VERSION "dbc-export 1 2026.26.6.5"

NS_ :

BS_:

BU_: APP APS BMS CC CMP CMPD CP DAS DI DIF DIR EPBL EPBR EVSE FC GTW HCML HCMR HVP ICR PCS PCS2 PLG PM PMF PMR PTC SCCM SCM SCS SDCR TAS UMC V2G VC VCBATT VCBATT0 VCBATT1 VCBATT2 VCFRONT VCFRONT1 VCFRONT2 VCLEFT VCRIGHT VCSEC

BO_ 963 VCRIGHT_switchStatus: 8 VCRIGHT
 SG_ VCRIGHT_switchStatusIndex M : 0|1@1+ (1,0) [0|1] "" Vector__XXX
 SG_ VCRIGHT_btnWindowUpRF : 24|1@1+ (1,0) [0|1] "" Vector__XXX
 SG_ VCRIGHT_btnWindowAutoUpRF : 25|1@1+ (1,0) [0|1] "" Vector__XXX
 SG_ VCRIGHT_btnWindowDownRF : 26|1@1+ (1,0) [0|1] "" Vector__XXX
 SG_ VCRIGHT_btnWindowAutoDownRF : 27|1@1+ (1,0) [0|1] "" Vector__XXX
 SG_ VCRIGHT_btnWindowUpRR : 28|1@1+ (1,0) [0|1] "" Vector__XXX
 SG_ VCRIGHT_btnWindowAutoUpRR : 29|1@1+ (1,0) [0|1] "" Vector__XXX
 SG_ VCRIGHT_btnWindowDownRR : 30|1@1+ (1,0) [0|1] "" Vector__XXX
 SG_ VCRIGHT_btnWindowAutoDownRR : 31|1@1+ (1,0) [0|1] "" Vector__XXX
 SG_ VCRIGHT_btnWindowSwPackUpLF : 32|1@1+ (1,0) [0|1] "" Vector__XXX
 SG_ VCRIGHT_btnWindowSwPackAutoUpLF : 33|1@1+ (1,0) [0|1] "" Vector__XXX
 SG_ VCRIGHT_btnWindowSwPackDownLF : 34|1@1+ (1,0) [0|1] "" Vector__XXX
 SG_ VCRIGHT_btnWindowSwPackAutoDwnLF : 35|1@1+ (1,0) [0|1] "" Vector__XXX
 SG_ VCRIGHT_btnWindowSwPackUpLR : 36|1@1+ (1,0) [0|1] "" Vector__XXX
 SG_ VCRIGHT_btnWindowSwPackAutoUpLR : 37|1@1+ (1,0) [0|1] "" Vector__XXX
 SG_ VCRIGHT_btnWindowSwPackDownLR : 38|1@1+ (1,0) [0|1] "" Vector__XXX
 SG_ VCRIGHT_btnWindowSwPackAutoDwnLR : 39|1@1+ (1,0) [0|1] "" Vector__XXX
 SG_ VCRIGHT_frontOccupancySwitch : 42|2@1+ (1,0) [0|3] "" Vector__XXX
 SG_ VCRIGHT_trunkExtReleasePressed : 48|1@1+ (1,0) [0|1] "" Vector__XXX
 SG_ VCRIGHT_btnWindowSwPackUpRR : 49|1@1+ (1,0) [0|1] "" Vector__XXX
 SG_ VCRIGHT_btnWindowSwPackAutoUpRR : 50|1@1+ (1,0) [0|1] "" Vector__XXX
 SG_ VCRIGHT_btnWindowSwPackDownRR : 51|1@1+ (1,0) [0|1] "" Vector__XXX
 SG_ VCRIGHT_btnWindowSwPackAutoDwnRR : 52|1@1+ (1,0) [0|1] "" Vector__XXX
 SG_ VCRIGHT_frontBuckleSwitch m0 : 40|2@1+ (1,0) [0|3] "" Vector__XXX
 SG_ VCRIGHT_rearCenterBuckleSwitch m0 : 44|2@1+ (1,0) [0|3] "" Vector__XXX
 SG_ VCRIGHT_rearRightBuckleSwitch m0 : 46|2@1+ (1,0) [0|3] "" Vector__XXX
 SG_ VCRIGHT_trunkExtReleasePressedPe m1 : 1|1@1+ (1,0) [0|1] "" Vector__XXX
 SG_ VCRIGHT_frontSeatTrackBack m1 : 2|2@1+ (1,0) [1|3] "" Vector__XXX
 SG_ VCRIGHT_frontSeatTrackForward m1 : 4|2@1+ (1,0) [1|3] "" Vector__XXX
 SG_ VCRIGHT_frontSeatTiltDown m1 : 6|2@1+ (1,0) [1|3] "" Vector__XXX
 SG_ VCRIGHT_frontSeatTiltUp m1 : 8|2@1+ (1,0) [1|3] "" Vector__XXX
 SG_ VCRIGHT_frontSeatLiftDown m1 : 10|2@1+ (1,0) [1|3] "" Vector__XXX
 SG_ VCRIGHT_frontSeatLiftUp m1 : 12|2@1+ (1,0) [1|3] "" Vector__XXX
 SG_ VCRIGHT_frontSeatBackrestBack m1 : 14|2@1+ (1,0) [1|3] "" Vector__XXX
 SG_ VCRIGHT_frontSeatBackrestForward m1 : 16|2@1+ (1,0) [1|3] "" Vector__XXX
 SG_ VCRIGHT_frontSeatLumbarDown m1 : 18|2@1+ (1,0) [1|3] "" Vector__XXX
 SG_ VCRIGHT_frontSeatLumbarUp m1 : 20|2@1+ (1,0) [1|3] "" Vector__XXX
 SG_ VCRIGHT_frontSeatLumbarIn m1 : 22|2@1+ (1,0) [1|3] "" Vector__XXX
 SG_ VCRIGHT_frontSeatResistiveOccupa m1 : 54|2@1+ (1,0) [1|3] "" Vector__XXX
 SG_ VCRIGHT_2RowSeatReclineSwitchpac m1 : 56|3@1+ (1,0) [0|7] "" Vector__XXX
 SG_ VCRIGHT_hvacHeatingAllowedRight m1 : 59|1@1+ (1,0) [0|1] "" Vector__XXX
 SG_ VCRIGHT_frontSeatThighSupportRet m1 : 60|2@1+ (1,0) [1|3] "" Vector__XXX

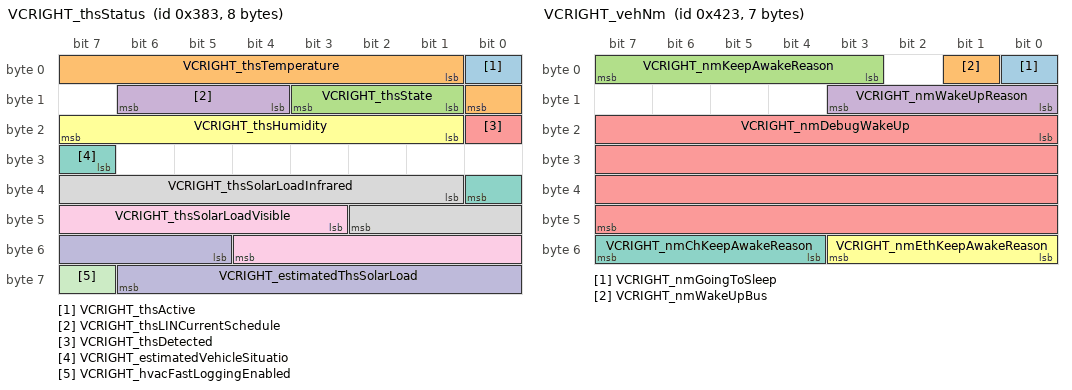
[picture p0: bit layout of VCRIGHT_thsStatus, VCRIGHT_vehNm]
BO_ 899 VCRIGHT_thsStatus: 8 VCRIGHT
 SG_ VCRIGHT_thsActive : 0|1@1+ (1,0) [0|1] "" Vector__XXX
 SG_ VCRIGHT_thsTemperature : 1|8@1+ (1,-40) [-40|150] "degC" Vector__XXX
 SG_ VCRIGHT_thsState : 9|3@1+ (1,0) [0|7] "" Vector__XXX
 SG_ VCRIGHT_thsLINCurrentSchedule : 12|3@1+ (1,0) [0|7] "" Vector__XXX
 SG_ VCRIGHT_thsDetected : 16|1@1+ (1,0) [0|1] "" Vector__XXX
 SG_ VCRIGHT_thsHumidity : 17|7@1+ (1,0) [0|100] "%" Vector__XXX
 SG_ VCRIGHT_estimatedVehicleSituatio : 31|2@1+ (1,0) [0|3] "" Vector__XXX
 SG_ VCRIGHT_thsSolarLoadInfrared : 33|10@1+ (2,0) [0|2044] "W/m2" Vector__XXX
 SG_ VCRIGHT_thsSolarLoadVisible : 43|10@1+ (2,0) [0|2044] "W/m2" Vector__XXX
 SG_ VCRIGHT_estimatedThsSolarLoad : 53|10@1+ (1,0) [0|1022] "W/m2" Vector__XXX
 SG_ VCRIGHT_hvacFastLoggingEnabled : 63|1@1+ (1,0) [0|1] "" Vector__XXX

BO_ 1545 VCRIGHT_udsResponse: 8 VCRIGHT
 SG_ VCRIGHT_udsResponseData_H : 7|32@0+ (1,0) [0|4294967295] "" Vector__XXX
 SG_ VCRIGHT_udsResponseData_L : 39|32@0+ (1,0) [0|4294967295] "" Vector__XXX

BO_ 1059 VCRIGHT_vehNm: 7 VCRIGHT
 SG_ VCRIGHT_nmGoingToSleep : 0|1@1+ (1,0) [0|1] "" Vector__XXX
 SG_ VCRIGHT_nmWakeUpBus : 1|1@1+ (1,0) [0|1] "" Vector__XXX
 SG_ VCRIGHT_nmKeepAwakeReason : 3|5@1+ (1,0) [1|31] "" Vector__XXX
 SG_ VCRIGHT_nmWakeUpReason : 8|4@1+ (1,0) [0|15] "" Vector__XXX
 SG_ VCRIGHT_nmDebugWakeUp : 16|32@1+ (1,0) [0|4294967295] "" Vector__XXX
 SG_ VCRIGHT_nmEthKeepAwakeReason : 48|4@1+ (1,0) [1|15] "" Vector__XXX
 SG_ VCRIGHT_nmChKeepAwakeReason : 52|4@1+ (1,0) [1|15] "" Vector__XXX

BO_ 707 VCRIGHT_windowStatus: 8 VCRIGHT
 SG_ VCRIGHT_windowStatusIndex M : 0|1@1+ (1,0) [0|1] "" Vector__XXX
 SG_ VCRIGHT_windowStateRF m0 : 1|4@1+ (1,0) [0|15] "" Vector__XXX
 SG_ VCRIGHT_windowTrimClearMoveReque m0 : 5|2@1+ (1,0) [0|3] "" Vector__XXX
 SG_ VCRIGHT_windowDutyRF m0 : 8|6@1- (5,0) [-100|100] "%" Vector__XXX
 SG_ VCRIGHT_windowTrimClearActiveReq m0 : 14|2@1+ (1,0) [1|3] "" Vector__XXX
 SG_ VCRIGHT_windowCurrentRF m0 : 16|6@1- (0.5,0) [-15|15] "A" Vector__XXX
 SG_ VCRIGHT_windowPositionRF m0 : 22|9@1- (1.25,265) [-50|580] "mm" Vector__XXX
 SG_ VCRIGHT_windowCalibratedRF m0 : 32|1@1+ (1,0) [0|1] "" Vector__XXX
 SG_ VCRIGHT_windowStateRR m0 : 33|4@1+ (1,0) [0|15] "" Vector__XXX
 SG_ VCRIGHT_windowDutyRR m0 : 40|6@1- (5,0) [-100|100] "%" Vector__XXX
 SG_ VCRIGHT_windowCurrentRR m0 : 48|6@1- (0.5,0) [-15|15] "A" Vector__XXX
 SG_ VCRIGHT_windowPositionRR m0 : 54|9@1- (1.25,265) [-50|580] "mm" Vector__XXX
 SG_ VCRIGHT_windowCalibratedRR m0 : 63|1@1+ (1,0) [0|1] "" Vector__XXX
 SG_ VCRIGHT_windowThermalTCRF m1 : 1|8@1+ (1,0) [0|255] "s" Vector__XXX
 SG_ VCRIGHT_windowThermalModeRF m1 : 9|2@1+ (1,0) [1|3] "" Vector__XXX
 SG_ VCRIGHT_windowStopReasonRF m1 : 11|3@1+ (1,0) [0|7] "" Vector__XXX
 SG_ VCRIGHT_windowStopReqReasonRF m1 : 14|4@1+ (1,0) [0|15] "" Vector__XXX
 SG_ VCRIGHT_windowThermalTCRR m1 : 18|8@1+ (1,0) [0|255] "s" Vector__XXX
 SG_ VCRIGHT_windowThermalModeRR m1 : 26|2@1+ (1,0) [1|3] "" Vector__XXX
 SG_ VCRIGHT_windowStopReasonRR m1 : 28|3@1+ (1,0) [0|7] "" Vector__XXX
 SG_ VCRIGHT_windowStopReqReasonRR m1 : 31|4@1+ (1,0) [0|15] "" Vector__XXX
 SG_ VCRIGHT_windowControlStateRF m1 : 35|2@1+ (1,0) [0|3] "" Vector__XXX
 SG_ VCRIGHT_windowCtrlUnavailableRF m1 : 38|3@1+ (1,0) [0|7] "" Vector__XXX
 SG_ VCRIGHT_windowControlStateRR m1 : 42|2@1+ (1,0) [0|3] "" Vector__XXX
 SG_ VCRIGHT_windowCtrlUnavailableRR m1 : 45|3@1+ (1,0) [0|7] "" Vector__XXX
 SG_ VCRIGHT_windowPositionStateRF m1 : 49|3@1+ (1,0) [0|7] "" Vector__XXX
 SG_ VCRIGHT_windowPositionStateRR m1 : 52|3@1+ (1,0) [0|7] "" Vector__XXX
 SG_ VCRIGHT_windowVehGearStateRF m1 : 56|2@1+ (1,0) [1|3] "" Vector__XXX
 SG_ VCRIGHT_windowVehGearStateRR m1 : 58|2@1+ (1,0) [1|3] "" Vector__XXX
 SG_ VCRIGHT_windowSpeedTableStatusRF m1 : 60|2@1+ (1,0) [1|3] "" Vector__XXX
 SG_ VCRIGHT_windowSpeedTableStatusRR m1 : 62|2@1+ (1,0) [1|3] "" Vector__XXX

BO_ 969 VCSEC_BLEEndpointInfo: 8 VCSEC
 SG_ VCSEC_BLEEndpointInfoIndex M : 0|8@1+ (1,0) [0|255] "" Vector__XXX
 SG_ VCSEC_BLECENTERComponentID m1 : 8|16@1+ (1,0) [0|65535] "" Vector__XXX
 SG_ VCSEC_BLECENTERPcbaID m1 : 24|8@1+ (1,0) [0|255] "" Vector__XXX
 SG_ VCSEC_BLECENTERAssemblyID m1 : 32|8@1+ (1,0) [0|255] "" Vector__XXX
 SG_ VCSEC_BLECENTERUsageID m1 : 40|16@1+ (1,0) [0|65535] "" Vector__XXX
 SG_ VCSEC_BLECENTERCrc m2 : 8|32@1+ (1,0) [0|4294967295] "" Vector__XXX
 SG_ VCSEC_BLELEFTAppGitHashByte m3 : 8|56@1+ (1,0) [0|7.20575940379e+16] "" Vector__XXX
 SG_ VCSEC_BLELEFTComponentID m4 : 8|16@1+ (1,0) [0|65535] "" Vector__XXX
 SG_ VCSEC_BLELEFTPcbaID m4 : 24|8@1+ (1,0) [0|255] "" Vector__XXX
 SG_ VCSEC_BLELEFTAssemblyID m4 : 32|8@1+ (1,0) [0|255] "" Vector__XXX
 SG_ VCSEC_BLELEFTUsageID m4 : 40|16@1+ (1,0) [0|65535] "" Vector__XXX
 SG_ VCSEC_BLELEFTCrc m5 : 8|32@1+ (1,0) [0|4294967295] "" Vector__XXX
 SG_ VCSEC_BLERIGHTAppGitHashByte m6 : 8|56@1+ (1,0) [0|7.20575940379e+16] "" Vector__XXX
 SG_ VCSEC_BLERIGHTComponentID m7 : 8|16@1+ (1,0) [0|65535] "" Vector__XXX
 SG_ VCSEC_BLERIGHTPcbaID m7 : 24|8@1+ (1,0) [0|255] "" Vector__XXX
 SG_ VCSEC_BLERIGHTAssemblyID m7 : 32|8@1+ (1,0) [0|255] "" Vector__XXX
 SG_ VCSEC_BLERIGHTUsageID m7 : 40|16@1+ (1,0) [0|65535] "" Vector__XXX
 SG_ VCSEC_BLERIGHTCrc m8 : 8|32@1+ (1,0) [0|4294967295] "" Vector__XXX
 SG_ VCSEC_BLEREARAppGitHashByte m9 : 8|56@1+ (1,0) [0|7.20575940379e+16] "" Vector__XXX
 SG_ VCSEC_BLEREARComponentID m10 : 8|16@1+ (1,0) [0|65535] "" Vector__XXX
 SG_ VCSEC_BLEREARPcbaID m10 : 24|8@1+ (1,0) [0|255] "" Vector__XXX
 SG_ VCSEC_BLEREARAssemblyID m10 : 32|8@1+ (1,0) [0|255] "" Vector__XXX
 SG_ VCSEC_BLEREARUsageID m10 : 40|16@1+ (1,0) [0|65535] "" Vector__XXX
 SG_ VCSEC_BLEREARCrc m11 : 8|32@1+ (1,0) [0|4294967295] "" Vector__XXX
 SG_ VCSEC_UWBRightCrc m12 : 8|32@1+ (1,0) [0|4294967295] "" Vector__XXX
 SG_ VCSEC_UWBRightRadioConfigState m12 : 40|4@1+ (1,0) [0|15] "" Vector__XXX
 SG_ VCSEC_UWBRightUpdateStatus m12 : 44|3@1+ (1,0) [0|6] "" Vector__XXX
 SG_ VCSEC_UWBRightRetryLimitReached m12 : 47|1@1+ (1,0) [0|1] "" Vector__XXX
 SG_ VCSEC_UWBRightDspVersion m12 : 48|16@1+ (1,0) [0|65535] "" Vector__XXX
 SG_ VCSEC_UWBRightComponentID m13 : 8|8@1+ (1,0) [0|255] "" Vector__XXX
 SG_ VCSEC_UWBRightPcbaID m13 : 16|8@1+ (1,0) [0|255] "" Vector__XXX
 SG_ VCSEC_UWBRightAssemblyID m13 : 24|8@1+ (1,0) [0|255] "" Vector__XXX
 SG_ VCSEC_UWBRightUsageID m13 : 32|16@1+ (1,0) [0|65535] "" Vector__XXX
 SG_ VCSEC_UWBRearRightCrc m15 : 8|32@1+ (1,0) [0|4294967295] "" Vector__XXX
 SG_ VCSEC_UWBRearRightRadioConfigSta m15 : 40|4@1+ (1,0) [0|15] "" Vector__XXX
 SG_ VCSEC_UWBRearRightUpdateStatus m15 : 44|3@1+ (1,0) [0|6] "" Vector__XXX
 SG_ VCSEC_UWBRearRightRetryLimitReac m15 : 47|1@1+ (1,0) [0|1] "" Vector__XXX
 SG_ VCSEC_UWBRearRightDspVersion m15 : 48|16@1+ (1,0) [0|65535] "" Vector__XXX
 SG_ VCSEC_UWBRearRightComponentID m16 : 8|8@1+ (1,0) [0|255] "" Vector__XXX
 SG_ VCSEC_UWBRearRightPcbaID m16 : 16|8@1+ (1,0) [0|255] "" Vector__XXX
 SG_ VCSEC_UWBRearRightAssemblyID m16 : 24|8@1+ (1,0) [0|255] "" Vector__XXX
 SG_ VCSEC_UWBRearRightUsageID m16 : 32|16@1+ (1,0) [0|65535] "" Vector__XXX
 SG_ VCSEC_UWBRearLeftCrc m18 : 8|32@1+ (1,0) [0|4294967295] "" Vector__XXX
 SG_ VCSEC_UWBRearLeftRadioConfigStat m18 : 40|4@1+ (1,0) [0|15] "" Vector__XXX
 SG_ VCSEC_UWBRearLeftUpdateStatus m18 : 44|3@1+ (1,0) [0|6] "" Vector__XXX
 SG_ VCSEC_UWBRearLeftRetryLimitReach m18 : 47|1@1+ (1,0) [0|1] "" Vector__XXX
 SG_ VCSEC_UWBRearLeftDspVersion m18 : 48|16@1+ (1,0) [0|65535] "" Vector__XXX
 SG_ VCSEC_UWBRearLeftComponentID m19 : 8|8@1+ (1,0) [0|255] "" Vector__XXX
 SG_ VCSEC_UWBRearLeftPcbaID m19 : 16|8@1+ (1,0) [0|255] "" Vector__XXX
 SG_ VCSEC_UWBRearLeftAssemblyID m19 : 24|8@1+ (1,0) [0|255] "" Vector__XXX
 SG_ VCSEC_UWBRearLeftUsageID m19 : 32|16@1+ (1,0) [0|65535] "" Vector__XXX
 SG_ VCSEC_UWBRearCrc m21 : 8|32@1+ (1,0) [0|4294967295] "" Vector__XXX
 SG_ VCSEC_UWBRearRadioConfigState m21 : 40|4@1+ (1,0) [0|15] "" Vector__XXX
 SG_ VCSEC_UWBRearUpdateStatus m21 : 44|3@1+ (1,0) [0|6] "" Vector__XXX
 SG_ VCSEC_UWBRearRetryLimitReached m21 : 47|1@1+ (1,0) [0|1] "" Vector__XXX
 SG_ VCSEC_UWBRearDspVersion m21 : 48|16@1+ (1,0) [0|65535] "" Vector__XXX
 SG_ VCSEC_UWBRearComponentID m22 : 8|8@1+ (1,0) [0|255] "" Vector__XXX
 SG_ VCSEC_UWBRearPcbaID m22 : 16|8@1+ (1,0) [0|255] "" Vector__XXX
 SG_ VCSEC_UWBRearAssemblyID m22 : 24|8@1+ (1,0) [0|255] "" Vector__XXX
 SG_ VCSEC_UWBRearUsageID m22 : 32|16@1+ (1,0) [0|65535] "" Vector__XXX
 SG_ VCSEC_UWBLeftCrc m24 : 8|32@1+ (1,0) [0|4294967295] "" Vector__XXX
 SG_ VCSEC_UWBLeftRadioConfigState m24 : 40|4@1+ (1,0) [0|15] "" Vector__XXX
 SG_ VCSEC_UWBLeftUpdateStatus m24 : 44|3@1+ (1,0) [0|6] "" Vector__XXX
 SG_ VCSEC_UWBLeftRetryLimitReached m24 : 47|1@1+ (1,0) [0|1] "" Vector__XXX
 SG_ VCSEC_UWBLeftDspVersion m24 : 48|16@1+ (1,0) [0|65535] "" Vector__XXX
 SG_ VCSEC_UWBLeftComponentID m25 : 8|8@1+ (1,0) [0|255] "" Vector__XXX
 SG_ VCSEC_UWBLeftPcbaID m25 : 16|8@1+ (1,0) [0|255] "" Vector__XXX
 SG_ VCSEC_UWBLeftAssemblyID m25 : 24|8@1+ (1,0) [0|255] "" Vector__XXX
 SG_ VCSEC_UWBLeftUsageID m25 : 32|16@1+ (1,0) [0|65535] "" Vector__XXX
 SG_ VCSEC_UWBCenterCrc m27 : 8|32@1+ (1,0) [0|4294967295] "" Vector__XXX
 SG_ VCSEC_UWBCenterRadioConfigState m27 : 40|4@1+ (1,0) [0|15] "" Vector__XXX
 SG_ VCSEC_UWBCenterUpdateStatus m27 : 44|3@1+ (1,0) [0|6] "" Vector__XXX
 SG_ VCSEC_UWBCenterRetryLimitReached m27 : 47|1@1+ (1,0) [0|1] "" Vector__XXX
 SG_ VCSEC_UWBCenterDspVersion m27 : 48|16@1+ (1,0) [0|65535] "" Vector__XXX
 SG_ VCSEC_UWBCenterComponentID m28 : 8|8@1+ (1,0) [0|255] "" Vector__XXX
 SG_ VCSEC_UWBCenterPcbaID m28 : 16|8@1+ (1,0) [0|255] "" Vector__XXX
 SG_ VCSEC_UWBCenterAssemblyID m28 : 24|8@1+ (1,0) [0|255] "" Vector__XXX
 SG_ VCSEC_UWBCenterUsageID m28 : 32|16@1+ (1,0) [0|65535] "" Vector__XXX
 SG_ VCSEC_BLERIGHTREARCrc m30 : 8|32@1+ (1,0) [0|4294967295] "" Vector__XXX
 SG_ VCSEC_BLERIGHTREARComponentID m31 : 8|16@1+ (1,0) [0|65535] "" Vector__XXX
 SG_ VCSEC_BLERIGHTREARPcbaID m31 : 24|8@1+ (1,0) [0|255] "" Vector__XXX
 SG_ VCSEC_BLERIGHTREARAssemblyID m31 : 32|8@1+ (1,0) [0|255] "" Vector__XXX
 SG_ VCSEC_BLERIGHTREARUsageID m31 : 40|16@1+ (1,0) [0|65535] "" Vector__XXX
 SG_ VCSEC_BLENFCCRADLECrc m33 : 8|32@1+ (1,0) [0|4294967295] "" Vector__XXX
 SG_ VCSEC_BLENFCCRADLEComponentID m34 : 8|16@1+ (1,0) [0|65535] "" Vector__XXX
 SG_ VCSEC_BLENFCCRADLEPcbaID m34 : 24|8@1+ (1,0) [0|255] "" Vector__XXX
 SG_ VCSEC_BLENFCCRADLEAssemblyID m34 : 32|8@1+ (1,0) [0|255] "" Vector__XXX
 SG_ VCSEC_BLENFCCRADLEUsageID m34 : 40|16@1+ (1,0) [0|65535] "" Vector__XXX
 SG_ VCSEC_BLELEFTREARCrc m36 : 8|32@1+ (1,0) [0|4294967295] "" Vector__XXX
 SG_ VCSEC_BLELEFTREARComponentID m37 : 8|16@1+ (1,0) [0|65535] "" Vector__XXX
 SG_ VCSEC_BLELEFTREARPcbaID m37 : 24|8@1+ (1,0) [0|255] "" Vector__XXX
 SG_ VCSEC_BLELEFTREARAssemblyID m37 : 32|8@1+ (1,0) [0|255] "" Vector__XXX
 SG_ VCSEC_BLELEFTREARUsageID m37 : 40|16@1+ (1,0) [0|65535] "" Vector__XXX

BO_ 607 VCSEC_ChildSeatStatus: 8 VCSEC
 SG_ VCSEC_childSeat0_connectionState : 0|3@1+ (1,0) [0|7] "" Vector__XXX
 SG_ VCSEC_childSeat0_taskDisconnecti : 3|2@1+ (1,0) [0|3] "" Vector__XXX
 SG_ VCSEC_childSeat0_state : 5|4@1+ (1,0) [0|15] "" Vector__XXX
 SG_ VCSEC_childSeat0_taskErrorCode : 9|3@1+ (1,0) [0|7] "" Vector__XXX
 SG_ VCSEC_childSeat0_RSSI : 12|8@1- (1,0) [-128|126] "" Vector__XXX
 SG_ VCSEC_childSeat0_ISOFixStatus : 20|2@1+ (1,0) [0|3] "" Vector__XXX
 SG_ VCSEC_childSeat0_buckleStatus : 22|2@1+ (1,0) [0|3] "" Vector__XXX
 SG_ VCSEC_childSeat0_occupancyStatus : 24|2@1+ (1,0) [0|3] "" Vector__XXX
 SG_ VCSEC_childSeat1_connectionState : 26|3@1+ (1,0) [0|7] "" Vector__XXX
 SG_ VCSEC_childSeat1_taskDisconnecti : 29|2@1+ (1,0) [0|3] "" Vector__XXX
 SG_ VCSEC_childSeat1_state : 31|4@1+ (1,0) [0|15] "" Vector__XXX
 SG_ VCSEC_childSeat1_taskErrorCode : 35|3@1+ (1,0) [0|7] "" Vector__XXX
 SG_ VCSEC_childSeat1_RSSI : 38|8@1- (1,0) [-128|126] "" Vector__XXX
 SG_ VCSEC_childSeat1_ISOFixStatus : 46|2@1+ (1,0) [0|3] "" Vector__XXX
 SG_ VCSEC_childSeat1_buckleStatus : 48|2@1+ (1,0) [0|3] "" Vector__XXX
 SG_ VCSEC_childSeat1_occupancyStatus : 50|2@1+ (1,0) [0|3] "" Vector__XXX
 SG_ VCSEC_childPresenceDetectionWarn : 52|1@1+ (1,0) [0|1] "" Vector__XXX
 SG_ VCSEC_childSeatScanStatus : 53|2@1+ (1,0) [0|3] "" Vector__XXX
 SG_ VCSEC_childPresenceDetectionStat : 55|4@1+ (1,0) [0|15] "" Vector__XXX
 SG_ VCSEC_childPresenceDetectionSupp : 59|2@1+ (1,0) [0|3] "" Vector__XXX
 SG_ VCSEC_childPresenceDetectionNoti : 61|1@1+ (1,0) [0|1] "" Vector__XXX

BO_ 857 VCSEC_DeviceStatus: 8 VCSEC
 SG_ VCSEC_DeviceStatusIndex M : 0|7@1+ (1,0) [0|127] "" Vector__XXX
 SG_ VCSEC_Device0AuthResponseTime m0 : 7|7@1+ (50,0) [0|6300] "ms" Vector__XXX
 SG_ VCSEC_Device0Impermanent m0 : 14|1@1+ (1,0) [0|1] "" Vector__XXX
 SG_ VCSEC_Device0SELockedDown m0 : 15|1@1+ (1,0) [0|1] "" Vector__XXX
 SG_ VCSEC_Device0Version m0 : 16|16@1+ (1,0) [0|65535] "" Vector__XXX
 SG_ VCSEC_Device0WLEntry m0 : 32|5@1+ (1,0) [0|31] "" Vector__XXX
 SG_ VCSEC_Device0OSVersion m0 : 37|12@1+ (1,0) [0|4095] "" Vector__XXX
 SG_ VCSEC_Device0BatteryLevel m0 : 49|8@1+ (0.015625,0) [0|3.9] "V" Vector__XXX
 SG_ VCSEC_Device0Formfactor m0 : 57|5@1+ (1,0) [0|31] "" Vector__XXX
 SG_ VCSEC_Device0BlacklistStatus m0 : 62|1@1+ (1,0) [0|1] "" Vector__XXX
 SG_ VCSEC_Device0Stationary m0 : 63|1@1+ (1,0) [0|1] "" Vector__XXX
 SG_ VCSEC_Device0Bonded m2 : 8|1@1+ (1,0) [0|1] "" Vector__XXX
 SG_ VCSEC_Device0Role m2 : 9|4@1+ (1,0) [0|15] "" Vector__XXX
 SG_ VCSEC_Device0WhitelistActiveTime m2 : 16|16@1+ (1,0) [0|65535] "mins" Vector__XXX
 SG_ VCSEC_Device0SHA1 m2 : 32|32@1+ (1,0) [0|4294967295] "" Vector__XXX
 SG_ VCSEC_Device0Permissions m3 : 32|32@1+ (1,0) [0|4294967295] "" Vector__XXX
 SG_ VCSEC_Device0ManufacturerHashBit m5 : 8|24@1+ (1,0) [0|16777215] "" Vector__XXX
 SG_ VCSEC_Device0BuildNumberHashBits m5 : 32|32@1+ (1,0) [0|4294967295] "" Vector__XXX
 SG_ VCSEC_Device1AuthResponseTime m6 : 7|7@1+ (50,0) [0|6300] "ms" Vector__XXX
 SG_ VCSEC_Device1Impermanent m6 : 14|1@1+ (1,0) [0|1] "" Vector__XXX
 SG_ VCSEC_Device1SELockedDown m6 : 15|1@1+ (1,0) [0|1] "" Vector__XXX
 SG_ VCSEC_Device1Version m6 : 16|16@1+ (1,0) [0|65535] "" Vector__XXX
 SG_ VCSEC_Device1WLEntry m6 : 32|5@1+ (1,0) [0|31] "" Vector__XXX
 SG_ VCSEC_Device1OSVersion m6 : 37|12@1+ (1,0) [0|4095] "" Vector__XXX
 SG_ VCSEC_Device1BatteryLevel m6 : 49|8@1+ (0.015625,0) [0|3.9] "V" Vector__XXX
 SG_ VCSEC_Device1Formfactor m6 : 57|5@1+ (1,0) [0|31] "" Vector__XXX
 SG_ VCSEC_Device1BlacklistStatus m6 : 62|1@1+ (1,0) [0|1] "" Vector__XXX
 SG_ VCSEC_Device1Stationary m6 : 63|1@1+ (1,0) [0|1] "" Vector__XXX
 SG_ VCSEC_Device1Bonded m8 : 8|1@1+ (1,0) [0|1] "" Vector__XXX
 SG_ VCSEC_Device1Role m8 : 9|4@1+ (1,0) [0|15] "" Vector__XXX
 SG_ VCSEC_Device1WhitelistActiveTime m8 : 16|16@1+ (1,0) [0|65535] "mins" Vector__XXX
 SG_ VCSEC_Device1SHA1 m8 : 32|32@1+ (1,0) [0|4294967295] "" Vector__XXX
 SG_ VCSEC_Device1Permissions m9 : 32|32@1+ (1,0) [0|4294967295] "" Vector__XXX
 SG_ VCSEC_Device1ManufacturerHashBit m11 : 8|24@1+ (1,0) [0|16777215] "" Vector__XXX
 SG_ VCSEC_Device1BuildNumberHashBits m11 : 32|32@1+ (1,0) [0|4294967295] "" Vector__XXX
 SG_ VCSEC_Device2AuthResponseTime m12 : 7|7@1+ (50,0) [0|6300] "ms" Vector__XXX
 SG_ VCSEC_Device2Impermanent m12 : 14|1@1+ (1,0) [0|1] "" Vector__XXX
 SG_ VCSEC_Device2SELockedDown m12 : 15|1@1+ (1,0) [0|1] "" Vector__XXX
 SG_ VCSEC_Device2Version m12 : 16|16@1+ (1,0) [0|65535] "" Vector__XXX
 SG_ VCSEC_Device2WLEntry m12 : 32|5@1+ (1,0) [0|31] "" Vector__XXX
 SG_ VCSEC_Device2OSVersion m12 : 37|12@1+ (1,0) [0|4095] "" Vector__XXX
 SG_ VCSEC_Device2BatteryLevel m12 : 49|8@1+ (0.015625,0) [0|3.9] "V" Vector__XXX
 SG_ VCSEC_Device2Formfactor m12 : 57|5@1+ (1,0) [0|31] "" Vector__XXX
 SG_ VCSEC_Device2BlacklistStatus m12 : 62|1@1+ (1,0) [0|1] "" Vector__XXX
 SG_ VCSEC_Device2Stationary m12 : 63|1@1+ (1,0) [0|1] "" Vector__XXX
 SG_ VCSEC_Device2Bonded m14 : 8|1@1+ (1,0) [0|1] "" Vector__XXX
 SG_ VCSEC_Device2Role m14 : 9|4@1+ (1,0) [0|15] "" Vector__XXX
 SG_ VCSEC_Device2WhitelistActiveTime m14 : 16|16@1+ (1,0) [0|65535] "mins" Vector__XXX
 SG_ VCSEC_Device2SHA1 m14 : 32|32@1+ (1,0) [0|4294967295] "" Vector__XXX
 SG_ VCSEC_Device2Permissions m15 : 32|32@1+ (1,0) [0|4294967295] "" Vector__XXX
 SG_ VCSEC_Device2ManufacturerHashBit m17 : 8|24@1+ (1,0) [0|16777215] "" Vector__XXX
 SG_ VCSEC_Device2BuildNumberHashBits m17 : 32|32@1+ (1,0) [0|4294967295] "" Vector__XXX
 SG_ VCSEC_Device3AuthResponseTime m18 : 7|7@1+ (50,0) [0|6300] "ms" Vector__XXX
 SG_ VCSEC_Device3Impermanent m18 : 14|1@1+ (1,0) [0|1] "" Vector__XXX
 SG_ VCSEC_Device3SELockedDown m18 : 15|1@1+ (1,0) [0|1] "" Vector__XXX
 SG_ VCSEC_Device3Version m18 : 16|16@1+ (1,0) [0|65535] "" Vector__XXX
 SG_ VCSEC_Device3WLEntry m18 : 32|5@1+ (1,0) [0|31] "" Vector__XXX
 SG_ VCSEC_Device3OSVersion m18 : 37|12@1+ (1,0) [0|4095] "" Vector__XXX
 SG_ VCSEC_Device3BatteryLevel m18 : 49|8@1+ (0.015625,0) [0|3.9] "V" Vector__XXX
 SG_ VCSEC_Device3Formfactor m18 : 57|5@1+ (1,0) [0|31] "" Vector__XXX
 SG_ VCSEC_Device3BlacklistStatus m18 : 62|1@1+ (1,0) [0|1] "" Vector__XXX
 SG_ VCSEC_Device3Stationary m18 : 63|1@1+ (1,0) [0|1] "" Vector__XXX
 SG_ VCSEC_Device3Bonded m20 : 8|1@1+ (1,0) [0|1] "" Vector__XXX
 SG_ VCSEC_Device3Role m20 : 9|4@1+ (1,0) [0|15] "" Vector__XXX
 SG_ VCSEC_Device3WhitelistActiveTime m20 : 16|16@1+ (1,0) [0|65535] "mins" Vector__XXX
 SG_ VCSEC_Device3SHA1 m20 : 32|32@1+ (1,0) [0|4294967295] "" Vector__XXX
 SG_ VCSEC_Device3Permissions m21 : 32|32@1+ (1,0) [0|4294967295] "" Vector__XXX
 SG_ VCSEC_Device3ManufacturerHashBit m23 : 8|24@1+ (1,0) [0|16777215] "" Vector__XXX
 SG_ VCSEC_Device3BuildNumberHashBits m23 : 32|32@1+ (1,0) [0|4294967295] "" Vector__XXX
 SG_ VCSEC_Device4AuthResponseTime m24 : 7|7@1+ (50,0) [0|6300] "ms" Vector__XXX
 SG_ VCSEC_Device4Impermanent m24 : 14|1@1+ (1,0) [0|1] "" Vector__XXX
 SG_ VCSEC_Device4SELockedDown m24 : 15|1@1+ (1,0) [0|1] "" Vector__XXX
 SG_ VCSEC_Device4Version m24 : 16|16@1+ (1,0) [0|65535] "" Vector__XXX
 SG_ VCSEC_Device4WLEntry m24 : 32|5@1+ (1,0) [0|31] "" Vector__XXX
 SG_ VCSEC_Device4OSVersion m24 : 37|12@1+ (1,0) [0|4095] "" Vector__XXX
 SG_ VCSEC_Device4BatteryLevel m24 : 49|8@1+ (0.015625,0) [0|3.9] "V" Vector__XXX
 SG_ VCSEC_Device4Formfactor m24 : 57|5@1+ (1,0) [0|31] "" Vector__XXX
 SG_ VCSEC_Device4BlacklistStatus m24 : 62|1@1+ (1,0) [0|1] "" Vector__XXX
 SG_ VCSEC_Device4Stationary m24 : 63|1@1+ (1,0) [0|1] "" Vector__XXX
 SG_ VCSEC_Device4Bonded m26 : 8|1@1+ (1,0) [0|1] "" Vector__XXX
 SG_ VCSEC_Device4Role m26 : 9|4@1+ (1,0) [0|15] "" Vector__XXX
 SG_ VCSEC_Device4WhitelistActiveTime m26 : 16|16@1+ (1,0) [0|65535] "mins" Vector__XXX
 SG_ VCSEC_Device4SHA1 m26 : 32|32@1+ (1,0) [0|4294967295] "" Vector__XXX
 SG_ VCSEC_Device4Permissions m27 : 32|32@1+ (1,0) [0|4294967295] "" Vector__XXX
 SG_ VCSEC_Device4ManufacturerHashBit m29 : 8|24@1+ (1,0) [0|16777215] "" Vector__XXX
 SG_ VCSEC_Device4BuildNumberHashBits m29 : 32|32@1+ (1,0) [0|4294967295] "" Vector__XXX
 SG_ VCSEC_Device5AuthResponseTime m30 : 7|7@1+ (50,0) [0|6300] "ms" Vector__XXX
 SG_ VCSEC_Device5Impermanent m30 : 14|1@1+ (1,0) [0|1] "" Vector__XXX
 SG_ VCSEC_Device5SELockedDown m30 : 15|1@1+ (1,0) [0|1] "" Vector__XXX
 SG_ VCSEC_Device5Version m30 : 16|16@1+ (1,0) [0|65535] "" Vector__XXX
 SG_ VCSEC_Device5WLEntry m30 : 32|5@1+ (1,0) [0|31] "" Vector__XXX
 SG_ VCSEC_Device5OSVersion m30 : 37|12@1+ (1,0) [0|4095] "" Vector__XXX
 SG_ VCSEC_Device5BatteryLevel m30 : 49|8@1+ (0.015625,0) [0|3.9] "V" Vector__XXX
 SG_ VCSEC_Device5Formfactor m30 : 57|5@1+ (1,0) [0|31] "" Vector__XXX
 SG_ VCSEC_Device5BlacklistStatus m30 : 62|1@1+ (1,0) [0|1] "" Vector__XXX
 SG_ VCSEC_Device5Stationary m30 : 63|1@1+ (1,0) [0|1] "" Vector__XXX
 SG_ VCSEC_Device5Bonded m32 : 8|1@1+ (1,0) [0|1] "" Vector__XXX
 SG_ VCSEC_Device5Role m32 : 9|4@1+ (1,0) [0|15] "" Vector__XXX
 SG_ VCSEC_Device5WhitelistActiveTime m32 : 16|16@1+ (1,0) [0|65535] "mins" Vector__XXX
 SG_ VCSEC_Device5SHA1 m32 : 32|32@1+ (1,0) [0|4294967295] "" Vector__XXX
 SG_ VCSEC_Device5Permissions m33 : 32|32@1+ (1,0) [0|4294967295] "" Vector__XXX
 SG_ VCSEC_Device5ManufacturerHashBit m35 : 8|24@1+ (1,0) [0|16777215] "" Vector__XXX
 SG_ VCSEC_Device5BuildNumberHashBits m35 : 32|32@1+ (1,0) [0|4294967295] "" Vector__XXX
 SG_ VCSEC_Device6AuthResponseTime m36 : 7|7@1+ (50,0) [0|6300] "ms" Vector__XXX
 SG_ VCSEC_Device6Impermanent m36 : 14|1@1+ (1,0) [0|1] "" Vector__XXX
 SG_ VCSEC_Device6SELockedDown m36 : 15|1@1+ (1,0) [0|1] "" Vector__XXX
 SG_ VCSEC_Device6Version m36 : 16|16@1+ (1,0) [0|65535] "" Vector__XXX
 SG_ VCSEC_Device6WLEntry m36 : 32|5@1+ (1,0) [0|31] "" Vector__XXX
 SG_ VCSEC_Device6OSVersion m36 : 37|12@1+ (1,0) [0|4095] "" Vector__XXX
 SG_ VCSEC_Device6BatteryLevel m36 : 49|8@1+ (0.015625,0) [0|3.9] "V" Vector__XXX
 SG_ VCSEC_Device6Formfactor m36 : 57|5@1+ (1,0) [0|31] "" Vector__XXX
 SG_ VCSEC_Device6BlacklistStatus m36 : 62|1@1+ (1,0) [0|1] "" Vector__XXX
 SG_ VCSEC_Device6Stationary m36 : 63|1@1+ (1,0) [0|1] "" Vector__XXX
 SG_ VCSEC_Device6Bonded m38 : 8|1@1+ (1,0) [0|1] "" Vector__XXX
 SG_ VCSEC_Device6Role m38 : 9|4@1+ (1,0) [0|15] "" Vector__XXX
 SG_ VCSEC_Device6WhitelistActiveTime m38 : 16|16@1+ (1,0) [0|65535] "mins" Vector__XXX
 SG_ VCSEC_Device6SHA1 m38 : 32|32@1+ (1,0) [0|4294967295] "" Vector__XXX
 SG_ VCSEC_Device6Permissions m39 : 32|32@1+ (1,0) [0|4294967295] "" Vector__XXX
 SG_ VCSEC_Device6ManufacturerHashBit m41 : 8|24@1+ (1,0) [0|16777215] "" Vector__XXX
 SG_ VCSEC_Device6BuildNumberHashBits m41 : 32|32@1+ (1,0) [0|4294967295] "" Vector__XXX
 SG_ VCSEC_Device7AuthResponseTime m42 : 7|7@1+ (50,0) [0|6300] "ms" Vector__XXX
 SG_ VCSEC_Device7Impermanent m42 : 14|1@1+ (1,0) [0|1] "" Vector__XXX
 SG_ VCSEC_Device7SELockedDown m42 : 15|1@1+ (1,0) [0|1] "" Vector__XXX
 SG_ VCSEC_Device7Version m42 : 16|16@1+ (1,0) [0|65535] "" Vector__XXX
 SG_ VCSEC_Device7WLEntry m42 : 32|5@1+ (1,0) [0|31] "" Vector__XXX
 SG_ VCSEC_Device7OSVersion m42 : 37|12@1+ (1,0) [0|4095] "" Vector__XXX
 SG_ VCSEC_Device7BatteryLevel m42 : 49|8@1+ (0.015625,0) [0|3.9] "V" Vector__XXX
 SG_ VCSEC_Device7Formfactor m42 : 57|5@1+ (1,0) [0|31] "" Vector__XXX
 SG_ VCSEC_Device7BlacklistStatus m42 : 62|1@1+ (1,0) [0|1] "" Vector__XXX
 SG_ VCSEC_Device7Stationary m42 : 63|1@1+ (1,0) [0|1] "" Vector__XXX
 SG_ VCSEC_Device7Bonded m44 : 8|1@1+ (1,0) [0|1] "" Vector__XXX
 SG_ VCSEC_Device7Role m44 : 9|4@1+ (1,0) [0|15] "" Vector__XXX
 SG_ VCSEC_Device7WhitelistActiveTime m44 : 16|16@1+ (1,0) [0|65535] "mins" Vector__XXX
 SG_ VCSEC_Device7SHA1 m44 : 32|32@1+ (1,0) [0|4294967295] "" Vector__XXX
 SG_ VCSEC_Device7Permissions m45 : 32|32@1+ (1,0) [0|4294967295] "" Vector__XXX
 SG_ VCSEC_Device7ManufacturerHashBit m47 : 8|24@1+ (1,0) [0|16777215] "" Vector__XXX
 SG_ VCSEC_Device7BuildNumberHashBits m47 : 32|32@1+ (1,0) [0|4294967295] "" Vector__XXX
 SG_ VCSEC_Device8AuthResponseTime m48 : 7|7@1+ (50,0) [0|6300] "ms" Vector__XXX
 SG_ VCSEC_Device8Impermanent m48 : 14|1@1+ (1,0) [0|1] "" Vector__XXX
 SG_ VCSEC_Device8SELockedDown m48 : 15|1@1+ (1,0) [0|1] "" Vector__XXX
 SG_ VCSEC_Device8Version m48 : 16|16@1+ (1,0) [0|65535] "" Vector__XXX
 SG_ VCSEC_Device8WLEntry m48 : 32|5@1+ (1,0) [0|31] "" Vector__XXX
 SG_ VCSEC_Device8OSVersion m48 : 37|12@1+ (1,0) [0|4095] "" Vector__XXX
 SG_ VCSEC_Device8BatteryLevel m48 : 49|8@1+ (0.015625,0) [0|3.9] "V" Vector__XXX
 SG_ VCSEC_Device8Formfactor m48 : 57|5@1+ (1,0) [0|31] "" Vector__XXX
 SG_ VCSEC_Device8BlacklistStatus m48 : 62|1@1+ (1,0) [0|1] "" Vector__XXX
 SG_ VCSEC_Device8Stationary m48 : 63|1@1+ (1,0) [0|1] "" Vector__XXX
 SG_ VCSEC_Device8Bonded m50 : 8|1@1+ (1,0) [0|1] "" Vector__XXX
 SG_ VCSEC_Device8Role m50 : 9|4@1+ (1,0) [0|15] "" Vector__XXX
 SG_ VCSEC_Device8WhitelistActiveTime m50 : 16|16@1+ (1,0) [0|65535] "mins" Vector__XXX
 SG_ VCSEC_Device8SHA1 m50 : 32|32@1+ (1,0) [0|4294967295] "" Vector__XXX
 SG_ VCSEC_Device8Permissions m51 : 32|32@1+ (1,0) [0|4294967295] "" Vector__XXX
 SG_ VCSEC_Device8ManufacturerHashBit m53 : 8|24@1+ (1,0) [0|16777215] "" Vector__XXX
 SG_ VCSEC_Device8BuildNumberHashBits m53 : 32|32@1+ (1,0) [0|4294967295] "" Vector__XXX
 SG_ VCSEC_Device9AuthResponseTime m54 : 7|7@1+ (50,0) [0|6300] "ms" Vector__XXX
 SG_ VCSEC_Device9Impermanent m54 : 14|1@1+ (1,0) [0|1] "" Vector__XXX
 SG_ VCSEC_Device9SELockedDown m54 : 15|1@1+ (1,0) [0|1] "" Vector__XXX
 SG_ VCSEC_Device9Version m54 : 16|16@1+ (1,0) [0|65535] "" Vector__XXX
 SG_ VCSEC_Device9WLEntry m54 : 32|5@1+ (1,0) [0|31] "" Vector__XXX
 SG_ VCSEC_Device9OSVersion m54 : 37|12@1+ (1,0) [0|4095] "" Vector__XXX
 SG_ VCSEC_Device9BatteryLevel m54 : 49|8@1+ (0.015625,0) [0|3.9] "V" Vector__XXX
 SG_ VCSEC_Device9Formfactor m54 : 57|5@1+ (1,0) [0|31] "" Vector__XXX
 SG_ VCSEC_Device9BlacklistStatus m54 : 62|1@1+ (1,0) [0|1] "" Vector__XXX
 SG_ VCSEC_Device9Stationary m54 : 63|1@1+ (1,0) [0|1] "" Vector__XXX
 SG_ VCSEC_Device9Bonded m56 : 8|1@1+ (1,0) [0|1] "" Vector__XXX
 SG_ VCSEC_Device9Role m56 : 9|4@1+ (1,0) [0|15] "" Vector__XXX
 SG_ VCSEC_Device9WhitelistActiveTime m56 : 16|16@1+ (1,0) [0|65535] "mins" Vector__XXX
 SG_ VCSEC_Device9SHA1 m56 : 32|32@1+ (1,0) [0|4294967295] "" Vector__XXX
 SG_ VCSEC_Device9Permissions m57 : 32|32@1+ (1,0) [0|4294967295] "" Vector__XXX
 SG_ VCSEC_Device9ManufacturerHashBit m59 : 8|24@1+ (1,0) [0|16777215] "" Vector__XXX
 SG_ VCSEC_Device9BuildNumberHashBits m59 : 32|32@1+ (1,0) [0|4294967295] "" Vector__XXX
 SG_ VCSEC_Device10AuthResponseTime m60 : 7|7@1+ (50,0) [0|6300] "ms" Vector__XXX
 SG_ VCSEC_Device10Impermanent m60 : 14|1@1+ (1,0) [0|1] "" Vector__XXX
 SG_ VCSEC_Device10SELockedDown m60 : 15|1@1+ (1,0) [0|1] "" Vector__XXX
 SG_ VCSEC_Device10Version m60 : 16|16@1+ (1,0) [0|65535] "" Vector__XXX
 SG_ VCSEC_Device10WLEntry m60 : 32|5@1+ (1,0) [0|31] "" Vector__XXX
 SG_ VCSEC_Device10OSVersion m60 : 37|12@1+ (1,0) [0|4095] "" Vector__XXX
 SG_ VCSEC_Device10BatteryLevel m60 : 49|8@1+ (0.015625,0) [0|3.9] "V" Vector__XXX
 SG_ VCSEC_Device10Formfactor m60 : 57|5@1+ (1,0) [0|31] "" Vector__XXX
 SG_ VCSEC_Device10BlacklistStatus m60 : 62|1@1+ (1,0) [0|1] "" Vector__XXX
 SG_ VCSEC_Device10Stationary m60 : 63|1@1+ (1,0) [0|1] "" Vector__XXX
 SG_ VCSEC_Device10Bonded m62 : 8|1@1+ (1,0) [0|1] "" Vector__XXX
 SG_ VCSEC_Device10Role m62 : 9|4@1+ (1,0) [0|15] "" Vector__XXX
 SG_ VCSEC_Device10WhitelistActiveTim m62 : 16|16@1+ (1,0) [0|65535] "mins" Vector__XXX
 SG_ VCSEC_Device10SHA1 m62 : 32|32@1+ (1,0) [0|4294967295] "" Vector__XXX
 SG_ VCSEC_Device10Permissions m63 : 32|32@1+ (1,0) [0|4294967295] "" Vector__XXX
 SG_ VCSEC_Device10ManufacturerHashBi m65 : 8|24@1+ (1,0) [0|16777215] "" Vector__XXX
 SG_ VCSEC_Device10BuildNumberHashBit m65 : 32|32@1+ (1,0) [0|4294967295] "" Vector__XXX
 SG_ VCSEC_Device11AuthResponseTime m66 : 7|7@1+ (50,0) [0|6300] "ms" Vector__XXX
 SG_ VCSEC_Device11Impermanent m66 : 14|1@1+ (1,0) [0|1] "" Vector__XXX
 SG_ VCSEC_Device11SELockedDown m66 : 15|1@1+ (1,0) [0|1] "" Vector__XXX
 SG_ VCSEC_Device11Version m66 : 16|16@1+ (1,0) [0|65535] "" Vector__XXX
 SG_ VCSEC_Device11WLEntry m66 : 32|5@1+ (1,0) [0|31] "" Vector__XXX
 SG_ VCSEC_Device11OSVersion m66 : 37|12@1+ (1,0) [0|4095] "" Vector__XXX
 SG_ VCSEC_Device11BatteryLevel m66 : 49|8@1+ (0.015625,0) [0|3.9] "V" Vector__XXX
 SG_ VCSEC_Device11Formfactor m66 : 57|5@1+ (1,0) [0|31] "" Vector__XXX
 SG_ VCSEC_Device11BlacklistStatus m66 : 62|1@1+ (1,0) [0|1] "" Vector__XXX
 SG_ VCSEC_Device11Stationary m66 : 63|1@1+ (1,0) [0|1] "" Vector__XXX
 SG_ VCSEC_Device11Bonded m68 : 8|1@1+ (1,0) [0|1] "" Vector__XXX
 SG_ VCSEC_Device11Role m68 : 9|4@1+ (1,0) [0|15] "" Vector__XXX
 SG_ VCSEC_Device11WhitelistActiveTim m68 : 16|16@1+ (1,0) [0|65535] "mins" Vector__XXX
 SG_ VCSEC_Device11SHA1 m68 : 32|32@1+ (1,0) [0|4294967295] "" Vector__XXX
 SG_ VCSEC_Device11Permissions m69 : 32|32@1+ (1,0) [0|4294967295] "" Vector__XXX
 SG_ VCSEC_Device11ManufacturerHashBi m71 : 8|24@1+ (1,0) [0|16777215] "" Vector__XXX
 SG_ VCSEC_Device11BuildNumberHashBit m71 : 32|32@1+ (1,0) [0|4294967295] "" Vector__XXX
 SG_ VCSEC_Device12AuthResponseTime m72 : 7|7@1+ (50,0) [0|6300] "ms" Vector__XXX
 SG_ VCSEC_Device12Impermanent m72 : 14|1@1+ (1,0) [0|1] "" Vector__XXX
 SG_ VCSEC_Device12SELockedDown m72 : 15|1@1+ (1,0) [0|1] "" Vector__XXX
 SG_ VCSEC_Device12Version m72 : 16|16@1+ (1,0) [0|65535] "" Vector__XXX
 SG_ VCSEC_Device12WLEntry m72 : 32|5@1+ (1,0) [0|31] "" Vector__XXX
 SG_ VCSEC_Device12OSVersion m72 : 37|12@1+ (1,0) [0|4095] "" Vector__XXX
 SG_ VCSEC_Device12BatteryLevel m72 : 49|8@1+ (0.015625,0) [0|3.9] "V" Vector__XXX
 SG_ VCSEC_Device12Formfactor m72 : 57|5@1+ (1,0) [0|31] "" Vector__XXX
 SG_ VCSEC_Device12BlacklistStatus m72 : 62|1@1+ (1,0) [0|1] "" Vector__XXX
 SG_ VCSEC_Device12Stationary m72 : 63|1@1+ (1,0) [0|1] "" Vector__XXX
 SG_ VCSEC_Device12Bonded m74 : 8|1@1+ (1,0) [0|1] "" Vector__XXX
 SG_ VCSEC_Device12Role m74 : 9|4@1+ (1,0) [0|15] "" Vector__XXX
 SG_ VCSEC_Device12WhitelistActiveTim m74 : 16|16@1+ (1,0) [0|65535] "mins" Vector__XXX
 SG_ VCSEC_Device12SHA1 m74 : 32|32@1+ (1,0) [0|4294967295] "" Vector__XXX
 SG_ VCSEC_Device12Permissions m75 : 32|32@1+ (1,0) [0|4294967295] "" Vector__XXX
 SG_ VCSEC_Device12ManufacturerHashBi m77 : 8|24@1+ (1,0) [0|16777215] "" Vector__XXX
 SG_ VCSEC_Device12BuildNumberHashBit m77 : 32|32@1+ (1,0) [0|4294967295] "" Vector__XXX
 SG_ VCSEC_Device13AuthResponseTime m78 : 7|7@1+ (50,0) [0|6300] "ms" Vector__XXX
 SG_ VCSEC_Device13Impermanent m78 : 14|1@1+ (1,0) [0|1] "" Vector__XXX
 SG_ VCSEC_Device13SELockedDown m78 : 15|1@1+ (1,0) [0|1] "" Vector__XXX
 SG_ VCSEC_Device13Version m78 : 16|16@1+ (1,0) [0|65535] "" Vector__XXX
 SG_ VCSEC_Device13WLEntry m78 : 32|5@1+ (1,0) [0|31] "" Vector__XXX
 SG_ VCSEC_Device13OSVersion m78 : 37|12@1+ (1,0) [0|4095] "" Vector__XXX
 SG_ VCSEC_Device13BatteryLevel m78 : 49|8@1+ (0.015625,0) [0|3.9] "V" Vector__XXX
 SG_ VCSEC_Device13Formfactor m78 : 57|5@1+ (1,0) [0|31] "" Vector__XXX
 SG_ VCSEC_Device13BlacklistStatus m78 : 62|1@1+ (1,0) [0|1] "" Vector__XXX
 SG_ VCSEC_Device13Stationary m78 : 63|1@1+ (1,0) [0|1] "" Vector__XXX
 SG_ VCSEC_Device13Bonded m80 : 8|1@1+ (1,0) [0|1] "" Vector__XXX
 SG_ VCSEC_Device13Role m80 : 9|4@1+ (1,0) [0|15] "" Vector__XXX
 SG_ VCSEC_Device13WhitelistActiveTim m80 : 16|16@1+ (1,0) [0|65535] "mins" Vector__XXX
 SG_ VCSEC_Device13SHA1 m80 : 32|32@1+ (1,0) [0|4294967295] "" Vector__XXX
 SG_ VCSEC_Device13Permissions m81 : 32|32@1+ (1,0) [0|4294967295] "" Vector__XXX
 SG_ VCSEC_Device13ManufacturerHashBi m83 : 8|24@1+ (1,0) [0|16777215] "" Vector__XXX
 SG_ VCSEC_Device13BuildNumberHashBit m83 : 32|32@1+ (1,0) [0|4294967295] "" Vector__XXX
 SG_ VCSEC_Device14AuthResponseTime m84 : 7|7@1+ (50,0) [0|6300] "ms" Vector__XXX
 SG_ VCSEC_Device14Impermanent m84 : 14|1@1+ (1,0) [0|1] "" Vector__XXX
 SG_ VCSEC_Device14SELockedDown m84 : 15|1@1+ (1,0) [0|1] "" Vector__XXX
 SG_ VCSEC_Device14Version m84 : 16|16@1+ (1,0) [0|65535] "" Vector__XXX
 SG_ VCSEC_Device14WLEntry m84 : 32|5@1+ (1,0) [0|31] "" Vector__XXX
 SG_ VCSEC_Device14OSVersion m84 : 37|12@1+ (1,0) [0|4095] "" Vector__XXX
 SG_ VCSEC_Device14BatteryLevel m84 : 49|8@1+ (0.015625,0) [0|3.9] "V" Vector__XXX
 SG_ VCSEC_Device14Formfactor m84 : 57|5@1+ (1,0) [0|31] "" Vector__XXX
 SG_ VCSEC_Device14BlacklistStatus m84 : 62|1@1+ (1,0) [0|1] "" Vector__XXX
 SG_ VCSEC_Device14Stationary m84 : 63|1@1+ (1,0) [0|1] "" Vector__XXX
 SG_ VCSEC_Device14Bonded m86 : 8|1@1+ (1,0) [0|1] "" Vector__XXX
 SG_ VCSEC_Device14Role m86 : 9|4@1+ (1,0) [0|15] "" Vector__XXX
 SG_ VCSEC_Device14WhitelistActiveTim m86 : 16|16@1+ (1,0) [0|65535] "mins" Vector__XXX
 SG_ VCSEC_Device14SHA1 m86 : 32|32@1+ (1,0) [0|4294967295] "" Vector__XXX
 SG_ VCSEC_Device14Permissions m87 : 32|32@1+ (1,0) [0|4294967295] "" Vector__XXX
 SG_ VCSEC_Device14ManufacturerHashBi m89 : 8|24@1+ (1,0) [0|16777215] "" Vector__XXX
 SG_ VCSEC_Device14BuildNumberHashBit m89 : 32|32@1+ (1,0) [0|4294967295] "" Vector__XXX
 SG_ VCSEC_Device15AuthResponseTime m90 : 7|7@1+ (50,0) [0|6300] "ms" Vector__XXX
 SG_ VCSEC_Device15Impermanent m90 : 14|1@1+ (1,0) [0|1] "" Vector__XXX
 SG_ VCSEC_Device15SELockedDown m90 : 15|1@1+ (1,0) [0|1] "" Vector__XXX
 SG_ VCSEC_Device15Version m90 : 16|16@1+ (1,0) [0|65535] "" Vector__XXX
 SG_ VCSEC_Device15WLEntry m90 : 32|5@1+ (1,0) [0|31] "" Vector__XXX
 SG_ VCSEC_Device15OSVersion m90 : 37|12@1+ (1,0) [0|4095] "" Vector__XXX
 SG_ VCSEC_Device15BatteryLevel m90 : 49|8@1+ (0.015625,0) [0|3.9] "V" Vector__XXX
 SG_ VCSEC_Device15Formfactor m90 : 57|5@1+ (1,0) [0|31] "" Vector__XXX
 SG_ VCSEC_Device15BlacklistStatus m90 : 62|1@1+ (1,0) [0|1] "" Vector__XXX
 SG_ VCSEC_Device15Stationary m90 : 63|1@1+ (1,0) [0|1] "" Vector__XXX
 SG_ VCSEC_Device15Bonded m92 : 8|1@1+ (1,0) [0|1] "" Vector__XXX
 SG_ VCSEC_Device15Role m92 : 9|4@1+ (1,0) [0|15] "" Vector__XXX
 SG_ VCSEC_Device15WhitelistActiveTim m92 : 16|16@1+ (1,0) [0|65535] "mins" Vector__XXX
 SG_ VCSEC_Device15SHA1 m92 : 32|32@1+ (1,0) [0|4294967295] "" Vector__XXX
 SG_ VCSEC_Device15Permissions m93 : 32|32@1+ (1,0) [0|4294967295] "" Vector__XXX
 SG_ VCSEC_Device15ManufacturerHashBi m95 : 8|24@1+ (1,0) [0|16777215] "" Vector__XXX
 SG_ VCSEC_Device15BuildNumberHashBit m95 : 32|32@1+ (1,0) [0|4294967295] "" Vector__XXX
 SG_ VCSEC_Device16AuthResponseTime m96 : 7|7@1+ (50,0) [0|6300] "ms" Vector__XXX
 SG_ VCSEC_Device16Impermanent m96 : 14|1@1+ (1,0) [0|1] "" Vector__XXX
 SG_ VCSEC_Device16SELockedDown m96 : 15|1@1+ (1,0) [0|1] "" Vector__XXX
 SG_ VCSEC_Device16Version m96 : 16|16@1+ (1,0) [0|65535] "" Vector__XXX
 SG_ VCSEC_Device16WLEntry m96 : 32|5@1+ (1,0) [0|31] "" Vector__XXX
 SG_ VCSEC_Device16OSVersion m96 : 37|12@1+ (1,0) [0|4095] "" Vector__XXX
 SG_ VCSEC_Device16BatteryLevel m96 : 49|8@1+ (0.015625,0) [0|3.9] "V" Vector__XXX
 SG_ VCSEC_Device16Formfactor m96 : 57|5@1+ (1,0) [0|31] "" Vector__XXX
 SG_ VCSEC_Device16BlacklistStatus m96 : 62|1@1+ (1,0) [0|1] "" Vector__XXX
 SG_ VCSEC_Device16Stationary m96 : 63|1@1+ (1,0) [0|1] "" Vector__XXX
 SG_ VCSEC_Device16Bonded m98 : 8|1@1+ (1,0) [0|1] "" Vector__XXX
 SG_ VCSEC_Device16Role m98 : 9|4@1+ (1,0) [0|15] "" Vector__XXX
 SG_ VCSEC_Device16WhitelistActiveTim m98 : 16|16@1+ (1,0) [0|65535] "mins" Vector__XXX
 SG_ VCSEC_Device16SHA1 m98 : 32|32@1+ (1,0) [0|4294967295] "" Vector__XXX
 SG_ VCSEC_Device16Permissions m99 : 32|32@1+ (1,0) [0|4294967295] "" Vector__XXX
 SG_ VCSEC_Device16ManufacturerHashBi m101 : 8|24@1+ (1,0) [0|16777215] "" Vector__XXX
 SG_ VCSEC_Device16BuildNumberHashBit m101 : 32|32@1+ (1,0) [0|4294967295] "" Vector__XXX
 SG_ VCSEC_Device17AuthResponseTime m102 : 7|7@1+ (50,0) [0|6300] "ms" Vector__XXX
 SG_ VCSEC_Device17Impermanent m102 : 14|1@1+ (1,0) [0|1] "" Vector__XXX
 SG_ VCSEC_Device17SELockedDown m102 : 15|1@1+ (1,0) [0|1] "" Vector__XXX
 SG_ VCSEC_Device17Version m102 : 16|16@1+ (1,0) [0|65535] "" Vector__XXX
 SG_ VCSEC_Device17WLEntry m102 : 32|5@1+ (1,0) [0|31] "" Vector__XXX
 SG_ VCSEC_Device17OSVersion m102 : 37|12@1+ (1,0) [0|4095] "" Vector__XXX
 SG_ VCSEC_Device17BatteryLevel m102 : 49|8@1+ (0.015625,0) [0|3.9] "V" Vector__XXX
 SG_ VCSEC_Device17Formfactor m102 : 57|5@1+ (1,0) [0|31] "" Vector__XXX
 SG_ VCSEC_Device17BlacklistStatus m102 : 62|1@1+ (1,0) [0|1] "" Vector__XXX
 SG_ VCSEC_Device17Stationary m102 : 63|1@1+ (1,0) [0|1] "" Vector__XXX
 SG_ VCSEC_Device17Bonded m104 : 8|1@1+ (1,0) [0|1] "" Vector__XXX
 SG_ VCSEC_Device17Role m104 : 9|4@1+ (1,0) [0|15] "" Vector__XXX
 SG_ VCSEC_Device17WhitelistActiveTim m104 : 16|16@1+ (1,0) [0|65535] "mins" Vector__XXX
 SG_ VCSEC_Device17SHA1 m104 : 32|32@1+ (1,0) [0|4294967295] "" Vector__XXX
 SG_ VCSEC_Device17Permissions m105 : 32|32@1+ (1,0) [0|4294967295] "" Vector__XXX
 SG_ VCSEC_Device17ManufacturerHashBi m107 : 8|24@1+ (1,0) [0|16777215] "" Vector__XXX
 SG_ VCSEC_Device17BuildNumberHashBit m107 : 32|32@1+ (1,0) [0|4294967295] "" Vector__XXX
 SG_ VCSEC_Device18AuthResponseTime m108 : 7|7@1+ (50,0) [0|6300] "ms" Vector__XXX
 SG_ VCSEC_Device18Impermanent m108 : 14|1@1+ (1,0) [0|1] "" Vector__XXX
 SG_ VCSEC_Device18SELockedDown m108 : 15|1@1+ (1,0) [0|1] "" Vector__XXX
 SG_ VCSEC_Device18Version m108 : 16|16@1+ (1,0) [0|65535] "" Vector__XXX
 SG_ VCSEC_Device18WLEntry m108 : 32|5@1+ (1,0) [0|31] "" Vector__XXX
 SG_ VCSEC_Device18OSVersion m108 : 37|12@1+ (1,0) [0|4095] "" Vector__XXX
 SG_ VCSEC_Device18BatteryLevel m108 : 49|8@1+ (0.015625,0) [0|3.9] "V" Vector__XXX
 SG_ VCSEC_Device18Formfactor m108 : 57|5@1+ (1,0) [0|31] "" Vector__XXX
 SG_ VCSEC_Device18BlacklistStatus m108 : 62|1@1+ (1,0) [0|1] "" Vector__XXX
 SG_ VCSEC_Device18Stationary m108 : 63|1@1+ (1,0) [0|1] "" Vector__XXX
 SG_ VCSEC_Device18Bonded m110 : 8|1@1+ (1,0) [0|1] "" Vector__XXX
 SG_ VCSEC_Device18Role m110 : 9|4@1+ (1,0) [0|15] "" Vector__XXX
 SG_ VCSEC_Device18WhitelistActiveTim m110 : 16|16@1+ (1,0) [0|65535] "mins" Vector__XXX
 SG_ VCSEC_Device18SHA1 m110 : 32|32@1+ (1,0) [0|4294967295] "" Vector__XXX
 SG_ VCSEC_Device18Permissions m111 : 32|32@1+ (1,0) [0|4294967295] "" Vector__XXX
 SG_ VCSEC_Device18ManufacturerHashBi m113 : 8|24@1+ (1,0) [0|16777215] "" Vector__XXX
 SG_ VCSEC_Device18BuildNumberHashBit m113 : 32|32@1+ (1,0) [0|4294967295] "" Vector__XXX
 SG_ VCSEC_Device19AuthResponseTime m114 : 7|7@1+ (50,0) [0|6300] "ms" Vector__XXX
 SG_ VCSEC_Device19Impermanent m114 : 14|1@1+ (1,0) [0|1] "" Vector__XXX
 SG_ VCSEC_Device19SELockedDown m114 : 15|1@1+ (1,0) [0|1] "" Vector__XXX
 SG_ VCSEC_Device19Version m114 : 16|16@1+ (1,0) [0|65535] "" Vector__XXX
 SG_ VCSEC_Device19WLEntry m114 : 32|5@1+ (1,0) [0|31] "" Vector__XXX
 SG_ VCSEC_Device19OSVersion m114 : 37|12@1+ (1,0) [0|4095] "" Vector__XXX
 SG_ VCSEC_Device19BatteryLevel m114 : 49|8@1+ (0.015625,0) [0|3.9] "V" Vector__XXX
 SG_ VCSEC_Device19Formfactor m114 : 57|5@1+ (1,0) [0|31] "" Vector__XXX
 SG_ VCSEC_Device19BlacklistStatus m114 : 62|1@1+ (1,0) [0|1] "" Vector__XXX
 SG_ VCSEC_Device19Stationary m114 : 63|1@1+ (1,0) [0|1] "" Vector__XXX
 SG_ VCSEC_Device19Bonded m116 : 8|1@1+ (1,0) [0|1] "" Vector__XXX
 SG_ VCSEC_Device19Role m116 : 9|4@1+ (1,0) [0|15] "" Vector__XXX
 SG_ VCSEC_Device19WhitelistActiveTim m116 : 16|16@1+ (1,0) [0|65535] "mins" Vector__XXX
 SG_ VCSEC_Device19SHA1 m116 : 32|32@1+ (1,0) [0|4294967295] "" Vector__XXX
 SG_ VCSEC_Device19Permissions m117 : 32|32@1+ (1,0) [0|4294967295] "" Vector__XXX
 SG_ VCSEC_Device19ManufacturerHashBi m119 : 8|24@1+ (1,0) [0|16777215] "" Vector__XXX
 SG_ VCSEC_Device19BuildNumberHashBit m119 : 32|32@1+ (1,0) [0|4294967295] "" Vector__XXX

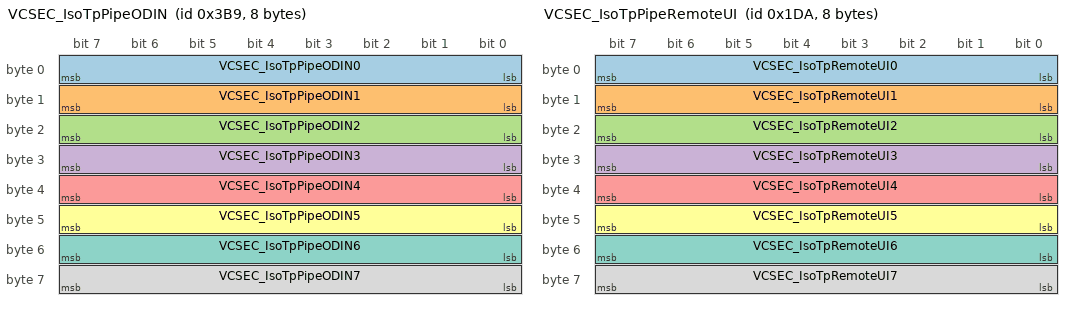
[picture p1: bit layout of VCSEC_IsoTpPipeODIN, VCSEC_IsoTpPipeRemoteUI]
BO_ 953 VCSEC_IsoTpPipeODIN: 8 VCSEC
 SG_ VCSEC_IsoTpPipeODIN0 : 0|8@1+ (1,0) [0|255] "" Vector__XXX
 SG_ VCSEC_IsoTpPipeODIN1 : 8|8@1+ (1,0) [0|255] "" Vector__XXX
 SG_ VCSEC_IsoTpPipeODIN2 : 16|8@1+ (1,0) [0|255] "" Vector__XXX
 SG_ VCSEC_IsoTpPipeODIN3 : 24|8@1+ (1,0) [0|255] "" Vector__XXX
 SG_ VCSEC_IsoTpPipeODIN4 : 32|8@1+ (1,0) [0|255] "" Vector__XXX
 SG_ VCSEC_IsoTpPipeODIN5 : 40|8@1+ (1,0) [0|255] "" Vector__XXX
 SG_ VCSEC_IsoTpPipeODIN6 : 48|8@1+ (1,0) [0|255] "" Vector__XXX
 SG_ VCSEC_IsoTpPipeODIN7 : 56|8@1+ (1,0) [0|255] "" Vector__XXX

BO_ 474 VCSEC_IsoTpPipeRemoteUI: 8 VCSEC
 SG_ VCSEC_IsoTpRemoteUI0 : 0|8@1+ (1,0) [0|255] "" Vector__XXX
 SG_ VCSEC_IsoTpRemoteUI1 : 8|8@1+ (1,0) [0|255] "" Vector__XXX
 SG_ VCSEC_IsoTpRemoteUI2 : 16|8@1+ (1,0) [0|255] "" Vector__XXX
 SG_ VCSEC_IsoTpRemoteUI3 : 24|8@1+ (1,0) [0|255] "" Vector__XXX
 SG_ VCSEC_IsoTpRemoteUI4 : 32|8@1+ (1,0) [0|255] "" Vector__XXX
 SG_ VCSEC_IsoTpRemoteUI5 : 40|8@1+ (1,0) [0|255] "" Vector__XXX
 SG_ VCSEC_IsoTpRemoteUI6 : 48|8@1+ (1,0) [0|255] "" Vector__XXX
 SG_ VCSEC_IsoTpRemoteUI7 : 56|8@1+ (1,0) [0|255] "" Vector__XXX

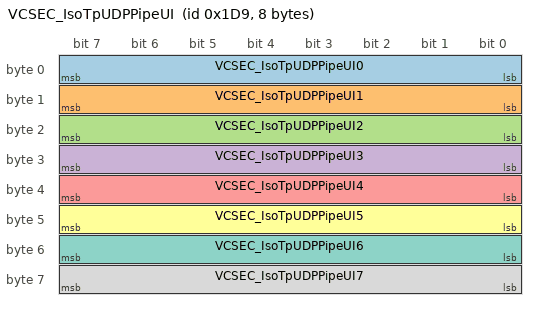
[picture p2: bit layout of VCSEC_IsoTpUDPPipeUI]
BO_ 473 VCSEC_IsoTpUDPPipeUI: 8 VCSEC
 SG_ VCSEC_IsoTpUDPPipeUI0 : 0|8@1+ (1,0) [0|255] "" Vector__XXX
 SG_ VCSEC_IsoTpUDPPipeUI1 : 8|8@1+ (1,0) [0|255] "" Vector__XXX
 SG_ VCSEC_IsoTpUDPPipeUI2 : 16|8@1+ (1,0) [0|255] "" Vector__XXX
 SG_ VCSEC_IsoTpUDPPipeUI3 : 24|8@1+ (1,0) [0|255] "" Vector__XXX
 SG_ VCSEC_IsoTpUDPPipeUI4 : 32|8@1+ (1,0) [0|255] "" Vector__XXX
 SG_ VCSEC_IsoTpUDPPipeUI5 : 40|8@1+ (1,0) [0|255] "" Vector__XXX
 SG_ VCSEC_IsoTpUDPPipeUI6 : 48|8@1+ (1,0) [0|255] "" Vector__XXX
 SG_ VCSEC_IsoTpUDPPipeUI7 : 56|8@1+ (1,0) [0|255] "" Vector__XXX

BO_ 1066 VCSEC_TPMSConnectionData: 8 VCSEC
 SG_ VCSEC_TPMSSensorState0 : 0|3@1+ (1,0) [0|7] "" Vector__XXX
 SG_ VCSEC_TPMSRSSI0 : 3|7@1+ (1,-127) [-127|0] "dBm" Vector__XXX
 SG_ VCSEC_TPMSConnectionTypeCurrent0 : 10|2@1+ (1,0) [0|3] "" Vector__XXX
 SG_ VCSEC_TPMSConnectionTypeDesired0 : 12|2@1+ (1,0) [0|3] "" Vector__XXX
 SG_ VCSEC_TPMSSensorState1 : 14|3@1+ (1,0) [0|7] "" Vector__XXX
 SG_ VCSEC_TPMSRSSI1 : 17|7@1+ (1,-127) [-127|0] "dBm" Vector__XXX
 SG_ VCSEC_TPMSConnectionTypeCurrent1 : 24|2@1+ (1,0) [0|3] "" Vector__XXX
 SG_ VCSEC_TPMSConnectionTypeDesired1 : 26|2@1+ (1,0) [0|3] "" Vector__XXX
 SG_ VCSEC_TPMSSensorState2 : 28|3@1+ (1,0) [0|7] "" Vector__XXX
 SG_ VCSEC_TPMSRSSI2 : 31|7@1+ (1,-127) [-127|0] "dBm" Vector__XXX
 SG_ VCSEC_TPMSConnectionTypeCurrent2 : 38|2@1+ (1,0) [0|3] "" Vector__XXX
 SG_ VCSEC_TPMSConnectionTypeDesired2 : 40|2@1+ (1,0) [0|3] "" Vector__XXX
 SG_ VCSEC_TPMSSensorState3 : 42|3@1+ (1,0) [0|7] "" Vector__XXX
 SG_ VCSEC_TPMSRSSI3 : 45|7@1+ (1,-127) [-127|0] "dBm" Vector__XXX
 SG_ VCSEC_TPMSConnectionTypeCurrent3 : 52|2@1+ (1,0) [0|3] "" Vector__XXX
 SG_ VCSEC_TPMSConnectionTypeDesired3 : 54|2@1+ (1,0) [0|3] "" Vector__XXX
 SG_ VCSEC_TPMSSensorPresence0 : 56|2@1+ (1,0) [0|3] "" Vector__XXX
 SG_ VCSEC_TPMSSensorPresence1 : 58|2@1+ (1,0) [0|3] "" Vector__XXX
 SG_ VCSEC_TPMSSensorPresence2 : 60|2@1+ (1,0) [0|3] "" Vector__XXX
 SG_ VCSEC_TPMSSensorPresence3 : 62|2@1+ (1,0) [0|3] "" Vector__XXX

BO_TX_BU_ 963 : VCRIGHT;
BO_TX_BU_ 899 : VCRIGHT;
BO_TX_BU_ 1545 : VCRIGHT;
BO_TX_BU_ 1059 : VCRIGHT;
BO_TX_BU_ 707 : VCRIGHT;
BO_TX_BU_ 969 : VCSEC;
BO_TX_BU_ 607 : VCSEC;
BO_TX_BU_ 857 : VCSEC;
BO_TX_BU_ 953 : VCSEC;
BO_TX_BU_ 474 : VCSEC;
BO_TX_BU_ 473 : VCSEC;
BO_TX_BU_ 1066 : VCSEC;
CM_ BO_ 963 "Right body controller message: switch status; frame length observed on a vehicle bus";
CM_ SG_ 963 VCRIGHT_switchStatusIndex "Right body controller: switch status index";
CM_ SG_ 963 VCRIGHT_btnWindowUpRF "Position from firmware; message assignment inferred.";
CM_ SG_ 963 VCRIGHT_btnWindowAutoUpRF "Position from firmware; message assignment inferred.";
CM_ SG_ 963 VCRIGHT_btnWindowDownRF "Position from firmware; message assignment inferred.";
CM_ SG_ 963 VCRIGHT_btnWindowAutoDownRF "Position from firmware; message assignment inferred.";
CM_ SG_ 963 VCRIGHT_btnWindowUpRR "Position from firmware; message assignment inferred.";
CM_ SG_ 963 VCRIGHT_btnWindowAutoUpRR "Position from firmware; message assignment inferred.";
CM_ SG_ 963 VCRIGHT_btnWindowDownRR "Position from firmware; message assignment inferred.";
CM_ SG_ 963 VCRIGHT_btnWindowAutoDownRR "Position from firmware; message assignment inferred.";
CM_ SG_ 963 VCRIGHT_btnWindowSwPackUpLF "Position from firmware; message assignment inferred.";
CM_ SG_ 963 VCRIGHT_btnWindowSwPackAutoUpLF "Position from firmware; message assignment inferred.";
CM_ SG_ 963 VCRIGHT_btnWindowSwPackDownLF "Position from firmware; message assignment inferred.";
CM_ SG_ 963 VCRIGHT_btnWindowSwPackAutoDwnLF "Position from firmware; message assignment inferred.";
CM_ SG_ 963 VCRIGHT_btnWindowSwPackUpLR "Position from firmware; message assignment inferred.";
CM_ SG_ 963 VCRIGHT_btnWindowSwPackAutoUpLR "Position from firmware; message assignment inferred.";
CM_ SG_ 963 VCRIGHT_btnWindowSwPackDownLR "Position from firmware; message assignment inferred.";
CM_ SG_ 963 VCRIGHT_btnWindowSwPackAutoDwnLR "Position from firmware; message assignment inferred.";
CM_ SG_ 963 VCRIGHT_frontOccupancySwitch "Front right seat occupancy status. Position from firmware; message assignment inferred.";
CM_ SG_ 963 VCRIGHT_trunkExtReleasePressed "State of exterior trunk release switch. Position from firmware; message assignment inferred.";
CM_ SG_ 963 VCRIGHT_btnWindowSwPackUpRR "Position from firmware; message assignment inferred.";
CM_ SG_ 963 VCRIGHT_btnWindowSwPackAutoUpRR "Position from firmware; message assignment inferred.";
CM_ SG_ 963 VCRIGHT_btnWindowSwPackDownRR "Position from firmware; message assignment inferred.";
CM_ SG_ 963 VCRIGHT_btnWindowSwPackAutoDwnRR "Position from firmware; message assignment inferred.";
CM_ SG_ 963 VCRIGHT_frontBuckleSwitch "Right body controller: front buckle switch";
CM_ SG_ 963 VCRIGHT_rearCenterBuckleSwitch "Right body controller: rear center buckle switch";
CM_ SG_ 963 VCRIGHT_rearRightBuckleSwitch "Right body controller: rear right buckle switch";
CM_ SG_ 963 VCRIGHT_trunkExtReleasePressedPe "Right body controller: trunk ext release pressed persist";
CM_ SG_ 963 VCRIGHT_frontSeatTrackBack "Right body controller: front seat track back; raw 0 = signal not available (SNA)";
CM_ SG_ 963 VCRIGHT_frontSeatTrackForward "Right body controller: front seat track forward; raw 0 = signal not available (SNA)";
CM_ SG_ 963 VCRIGHT_frontSeatTiltDown "Right body controller: front seat tilt down; raw 0 = signal not available (SNA)";
CM_ SG_ 963 VCRIGHT_frontSeatTiltUp "Right body controller: front seat tilt up; raw 0 = signal not available (SNA)";
CM_ SG_ 963 VCRIGHT_frontSeatLiftDown "Right body controller: front seat lift down; raw 0 = signal not available (SNA)";
CM_ SG_ 963 VCRIGHT_frontSeatLiftUp "Right body controller: front seat lift up; raw 0 = signal not available (SNA)";
CM_ SG_ 963 VCRIGHT_frontSeatBackrestBack "Right body controller: front seat backrest back; raw 0 = signal not available (SNA)";
CM_ SG_ 963 VCRIGHT_frontSeatBackrestForward "Right body controller: front seat backrest forward; raw 0 = signal not available (SNA)";
CM_ SG_ 963 VCRIGHT_frontSeatLumbarDown "Right body controller: front seat lumbar down; raw 0 = signal not available (SNA)";
CM_ SG_ 963 VCRIGHT_frontSeatLumbarUp "Right body controller: front seat lumbar up; raw 0 = signal not available (SNA)";
CM_ SG_ 963 VCRIGHT_frontSeatLumbarIn "Right body controller: front seat lumbar in; raw 0 = signal not available (SNA)";
CM_ SG_ 963 VCRIGHT_frontSeatResistiveOccupa "Front right seat occupancy status; raw 0 = signal not available (SNA)";
CM_ SG_ 963 VCRIGHT_2RowSeatReclineSwitchpac "State of the right second row powered recline adjustment switchpack";
CM_ SG_ 963 VCRIGHT_hvacHeatingAllowedRight "Right body controller: hvac heating allowed right";
CM_ SG_ 963 VCRIGHT_frontSeatThighSupportRet "Status of the switch used to retract front seat thigh support; raw 0 = signal not available (SNA)";
CM_ BO_ 899 "Right body controller message: ths status; frame length observed on a vehicle bus";
CM_ SG_ 899 VCRIGHT_thsActive "Right body controller: ths active";
CM_ SG_ 899 VCRIGHT_thsTemperature "Tesla HVAC sensor temperature; raw 255 = signal not available (SNA)";
CM_ SG_ 899 VCRIGHT_thsState "Right body controller: ths state";
CM_ SG_ 899 VCRIGHT_thsLINCurrentSchedule "Right body controller: ths LIN current schedule";
CM_ SG_ 899 VCRIGHT_thsDetected "Tesla HVAC sensor connection is detected";
CM_ SG_ 899 VCRIGHT_thsHumidity "Tesla HVAC sensor humidity; raw 127 = signal not available (SNA)";
CM_ SG_ 899 VCRIGHT_estimatedVehicleSituatio "Right body controller: estimated vehicle situation";
CM_ SG_ 899 VCRIGHT_thsSolarLoadInfrared "Solar power hitting the vehicle in the infrared spectrum; raw 1023 = signal not available (SNA)";
CM_ SG_ 899 VCRIGHT_thsSolarLoadVisible "Solar power hitting the vehicle in the visible spectrum; raw 1023 = signal not available (SNA)";
CM_ SG_ 899 VCRIGHT_estimatedThsSolarLoad "Right body controller: estimated ths solar load; raw 1023 = signal not available (SNA)";
CM_ SG_ 899 VCRIGHT_hvacFastLoggingEnabled "Right body controller: hvac fast logging enabled";
CM_ BO_ 1545 "Right body controller message: uds response; frame length from the layout, not yet observed on a vehicle bus";
CM_ SG_ 1545 VCRIGHT_udsResponseData_H "Right body controller: uds response data h";
CM_ SG_ 1545 VCRIGHT_udsResponseData_L "Right body controller: uds response data l";
CM_ BO_ 1059 "Right body controller message: veh nm; frame length observed on a vehicle bus";
CM_ SG_ 1059 VCRIGHT_nmGoingToSleep "Right body controller: nm going to sleep";
CM_ SG_ 1059 VCRIGHT_nmWakeUpBus "Right body controller: nm wake up bus";
CM_ SG_ 1059 VCRIGHT_nmKeepAwakeReason "Reason controller is preventing the vehicle from sleeping; raw 0 = signal not available (SNA)";
CM_ SG_ 1059 VCRIGHT_nmWakeUpReason "Right body controller: nm wake up reason";
CM_ SG_ 1059 VCRIGHT_nmDebugWakeUp "Right body controller: nm debug wake up";
CM_ SG_ 1059 VCRIGHT_nmEthKeepAwakeReason "Right body controller: nm eth keep awake reason; raw 0 = signal not available (SNA)";
CM_ SG_ 1059 VCRIGHT_nmChKeepAwakeReason "Right body controller: nm ch keep awake reason; raw 0 = signal not available (SNA)";
CM_ BO_ 707 "Right body controller message: window status; frame length observed on a vehicle bus";
CM_ SG_ 707 VCRIGHT_windowStatusIndex "Right body controller: window status index";
CM_ SG_ 707 VCRIGHT_windowStateRF "Status of right front window motor";
CM_ SG_ 707 VCRIGHT_windowTrimClearMoveReque "Reports a request for whether windows should enter or exit trim clear mode. Signal is only valid if Vehicle Controller Left (VCLEFT) is on driver side.";
CM_ SG_ 707 VCRIGHT_windowDutyRF "Right body controller: window duty RF";
CM_ SG_ 707 VCRIGHT_windowTrimClearActiveReq "Reports whether window trim clear is active. Signal is only valid if Vehicle Controller Left (VCLEFT) is on driver side; raw 0 = signal not available (SNA)";
CM_ SG_ 707 VCRIGHT_windowCurrentRF "Current drawn by left front window regulator";
CM_ SG_ 707 VCRIGHT_windowPositionRF "Right body controller: window position RF; raw 1 = signal not available (SNA)";
CM_ SG_ 707 VCRIGHT_windowCalibratedRF "Calibration status of right front window motor";
CM_ SG_ 707 VCRIGHT_windowStateRR "Status of right rear window motor";
CM_ SG_ 707 VCRIGHT_windowDutyRR "Right body controller: window duty RR";
CM_ SG_ 707 VCRIGHT_windowCurrentRR "Current drawn by left rear window regulator";
CM_ SG_ 707 VCRIGHT_windowPositionRR "Right body controller: window position RR";
CM_ SG_ 707 VCRIGHT_windowCalibratedRR "Calibration status of right rear window motor";
CM_ SG_ 707 VCRIGHT_windowThermalTCRF "Right body controller: window thermal TCRF";
CM_ SG_ 707 VCRIGHT_windowThermalModeRF "Right body controller: window thermal mode RF; raw 0 = signal not available (SNA)";
CM_ SG_ 707 VCRIGHT_windowStopReasonRF "Reason for right front window stopping motion";
CM_ SG_ 707 VCRIGHT_windowStopReqReasonRF "Reason for right front window stopping motion";
CM_ SG_ 707 VCRIGHT_windowThermalTCRR "Right body controller: window thermal TCRR";
CM_ SG_ 707 VCRIGHT_windowThermalModeRR "Right body controller: window thermal mode RR; raw 0 = signal not available (SNA)";
CM_ SG_ 707 VCRIGHT_windowStopReasonRR "Reason for right rear window stopping motion";
CM_ SG_ 707 VCRIGHT_windowStopReqReasonRR "Reason for right rear window stopping motion";
CM_ SG_ 707 VCRIGHT_windowControlStateRF "Window control state";
CM_ SG_ 707 VCRIGHT_windowCtrlUnavailableRF "Window control unavailable reason";
CM_ SG_ 707 VCRIGHT_windowControlStateRR "Window control state";
CM_ SG_ 707 VCRIGHT_windowCtrlUnavailableRR "Window control unavailable reason";
CM_ SG_ 707 VCRIGHT_windowPositionStateRF "Reports the window position state";
CM_ SG_ 707 VCRIGHT_windowPositionStateRR "Window position state";
CM_ SG_ 707 VCRIGHT_windowVehGearStateRF "Window's interpretation of vehicle gear state; raw 0 = signal not available (SNA)";
CM_ SG_ 707 VCRIGHT_windowVehGearStateRR "Window's interpretation of vehicle gear state; raw 0 = signal not available (SNA)";
CM_ SG_ 707 VCRIGHT_windowSpeedTableStatusRF "Speed table build status of right front window; raw 0 = signal not available (SNA)";
CM_ SG_ 707 VCRIGHT_windowSpeedTableStatusRR "Speed table build status of right rear window; raw 0 = signal not available (SNA)";
CM_ BO_ 969 "Vehicle security controller message: BLE endpoint info; frame length from the layout, not yet observed on a vehicle bus";
CM_ SG_ 969 VCSEC_BLEEndpointInfoIndex "Vehicle security controller: BLE endpoint info index";
CM_ SG_ 969 VCSEC_BLECENTERComponentID "Vehicle security controller: BLECENTER component ID";
CM_ SG_ 969 VCSEC_BLECENTERPcbaID "Vehicle security controller: BLECENTER pcba ID";
CM_ SG_ 969 VCSEC_BLECENTERAssemblyID "Vehicle security controller: BLECENTER assembly ID";
CM_ SG_ 969 VCSEC_BLECENTERUsageID "Vehicle security controller: BLECENTER usage ID";
CM_ SG_ 969 VCSEC_BLECENTERCrc "Vehicle security controller: BLECENTER crc";
CM_ SG_ 969 VCSEC_BLELEFTAppGitHashByte "Vehicle security controller: BLELEFT app git hash byte";
CM_ SG_ 969 VCSEC_BLELEFTComponentID "Vehicle security controller: BLELEFT component ID";
CM_ SG_ 969 VCSEC_BLELEFTPcbaID "Vehicle security controller: BLELEFT pcba ID";
CM_ SG_ 969 VCSEC_BLELEFTAssemblyID "Vehicle security controller: BLELEFT assembly ID";
CM_ SG_ 969 VCSEC_BLELEFTUsageID "Vehicle security controller: BLELEFT usage ID";
CM_ SG_ 969 VCSEC_BLELEFTCrc "Vehicle security controller: BLELEFT crc";
CM_ SG_ 969 VCSEC_BLERIGHTAppGitHashByte "Vehicle security controller: BLERIGHT app git hash byte";
CM_ SG_ 969 VCSEC_BLERIGHTComponentID "Vehicle security controller: BLERIGHT component ID";
CM_ SG_ 969 VCSEC_BLERIGHTPcbaID "Vehicle security controller: BLERIGHT pcba ID";
CM_ SG_ 969 VCSEC_BLERIGHTAssemblyID "Vehicle security controller: BLERIGHT assembly ID";
CM_ SG_ 969 VCSEC_BLERIGHTUsageID "Vehicle security controller: BLERIGHT usage ID";
CM_ SG_ 969 VCSEC_BLERIGHTCrc "Vehicle security controller: BLERIGHT crc";
CM_ SG_ 969 VCSEC_BLEREARAppGitHashByte "Vehicle security controller: BLEREAR app git hash byte";
CM_ SG_ 969 VCSEC_BLEREARComponentID "Vehicle security controller: BLEREAR component ID";
CM_ SG_ 969 VCSEC_BLEREARPcbaID "Vehicle security controller: BLEREAR pcba ID";
CM_ SG_ 969 VCSEC_BLEREARAssemblyID "Vehicle security controller: BLEREAR assembly ID";
CM_ SG_ 969 VCSEC_BLEREARUsageID "Vehicle security controller: BLEREAR usage ID";
CM_ SG_ 969 VCSEC_BLEREARCrc "Vehicle security controller: BLEREAR crc";
CM_ SG_ 969 VCSEC_UWBRightCrc "Vehicle security controller: UWB right crc";
CM_ SG_ 969 VCSEC_UWBRightRadioConfigState "Vehicle security controller: UWB right radio config state";
CM_ SG_ 969 VCSEC_UWBRightUpdateStatus "Vehicle security controller: UWB right update status; raw 7 = signal not available (SNA)";
CM_ SG_ 969 VCSEC_UWBRightRetryLimitReached "Vehicle security controller: UWB right retry limit reached";
CM_ SG_ 969 VCSEC_UWBRightDspVersion "Vehicle security controller: UWB right dsp version";
CM_ SG_ 969 VCSEC_UWBRightComponentID "Vehicle security controller: UWB right component ID";
CM_ SG_ 969 VCSEC_UWBRightPcbaID "Vehicle security controller: UWB right pcba ID";
CM_ SG_ 969 VCSEC_UWBRightAssemblyID "Vehicle security controller: UWB right assembly ID";
CM_ SG_ 969 VCSEC_UWBRightUsageID "Vehicle security controller: UWB right usage ID";
CM_ SG_ 969 VCSEC_UWBRearRightCrc "Vehicle security controller: UWB rear right crc";
CM_ SG_ 969 VCSEC_UWBRearRightRadioConfigSta "Vehicle security controller: UWB rear right radio config state";
CM_ SG_ 969 VCSEC_UWBRearRightUpdateStatus "Vehicle security controller: UWB rear right update status; raw 7 = signal not available (SNA)";
CM_ SG_ 969 VCSEC_UWBRearRightRetryLimitReac "Vehicle security controller: UWB rear right retry limit reached";
CM_ SG_ 969 VCSEC_UWBRearRightDspVersion "Vehicle security controller: UWB rear right dsp version";
CM_ SG_ 969 VCSEC_UWBRearRightComponentID "Vehicle security controller: UWB rear right component ID";
CM_ SG_ 969 VCSEC_UWBRearRightPcbaID "Vehicle security controller: UWB rear right pcba ID";
CM_ SG_ 969 VCSEC_UWBRearRightAssemblyID "Vehicle security controller: UWB rear right assembly ID";
CM_ SG_ 969 VCSEC_UWBRearRightUsageID "Vehicle security controller: UWB rear right usage ID";
CM_ SG_ 969 VCSEC_UWBRearLeftCrc "Vehicle security controller: UWB rear left crc";
CM_ SG_ 969 VCSEC_UWBRearLeftRadioConfigStat "Vehicle security controller: UWB rear left radio config state";
CM_ SG_ 969 VCSEC_UWBRearLeftUpdateStatus "Vehicle security controller: UWB rear left update status; raw 7 = signal not available (SNA)";
CM_ SG_ 969 VCSEC_UWBRearLeftRetryLimitReach "Vehicle security controller: UWB rear left retry limit reached";
CM_ SG_ 969 VCSEC_UWBRearLeftDspVersion "Vehicle security controller: UWB rear left dsp version";
CM_ SG_ 969 VCSEC_UWBRearLeftComponentID "Vehicle security controller: UWB rear left component ID";
CM_ SG_ 969 VCSEC_UWBRearLeftPcbaID "Vehicle security controller: UWB rear left pcba ID";
CM_ SG_ 969 VCSEC_UWBRearLeftAssemblyID "Vehicle security controller: UWB rear left assembly ID";
CM_ SG_ 969 VCSEC_UWBRearLeftUsageID "Vehicle security controller: UWB rear left usage ID";
CM_ SG_ 969 VCSEC_UWBRearCrc "Vehicle security controller: UWB rear crc";
CM_ SG_ 969 VCSEC_UWBRearRadioConfigState "Vehicle security controller: UWB rear radio config state";
CM_ SG_ 969 VCSEC_UWBRearUpdateStatus "Vehicle security controller: UWB rear update status; raw 7 = signal not available (SNA)";
CM_ SG_ 969 VCSEC_UWBRearRetryLimitReached "Vehicle security controller: UWB rear retry limit reached";
CM_ SG_ 969 VCSEC_UWBRearDspVersion "Vehicle security controller: UWB rear dsp version";
CM_ SG_ 969 VCSEC_UWBRearComponentID "Vehicle security controller: UWB rear component ID";
CM_ SG_ 969 VCSEC_UWBRearPcbaID "Vehicle security controller: UWB rear pcba ID";
CM_ SG_ 969 VCSEC_UWBRearAssemblyID "Vehicle security controller: UWB rear assembly ID";
CM_ SG_ 969 VCSEC_UWBRearUsageID "Vehicle security controller: UWB rear usage ID";
CM_ SG_ 969 VCSEC_UWBLeftCrc "Vehicle security controller: UWB left crc";
CM_ SG_ 969 VCSEC_UWBLeftRadioConfigState "Vehicle security controller: UWB left radio config state";
CM_ SG_ 969 VCSEC_UWBLeftUpdateStatus "Vehicle security controller: UWB left update status; raw 7 = signal not available (SNA)";
CM_ SG_ 969 VCSEC_UWBLeftRetryLimitReached "Vehicle security controller: UWB left retry limit reached";
CM_ SG_ 969 VCSEC_UWBLeftDspVersion "Vehicle security controller: UWB left dsp version";
CM_ SG_ 969 VCSEC_UWBLeftComponentID "Vehicle security controller: UWB left component ID";
CM_ SG_ 969 VCSEC_UWBLeftPcbaID "Vehicle security controller: UWB left pcba ID";
CM_ SG_ 969 VCSEC_UWBLeftAssemblyID "Vehicle security controller: UWB left assembly ID";
CM_ SG_ 969 VCSEC_UWBLeftUsageID "Vehicle security controller: UWB left usage ID";
CM_ SG_ 969 VCSEC_UWBCenterCrc "Vehicle security controller: UWB center crc";
CM_ SG_ 969 VCSEC_UWBCenterRadioConfigState "Vehicle security controller: UWB center radio config state";
CM_ SG_ 969 VCSEC_UWBCenterUpdateStatus "Vehicle security controller: UWB center update status; raw 7 = signal not available (SNA)";
CM_ SG_ 969 VCSEC_UWBCenterRetryLimitReached "Vehicle security controller: UWB center retry limit reached";
CM_ SG_ 969 VCSEC_UWBCenterDspVersion "Vehicle security controller: UWB center dsp version";
CM_ SG_ 969 VCSEC_UWBCenterComponentID "Vehicle security controller: UWB center component ID";
CM_ SG_ 969 VCSEC_UWBCenterPcbaID "Vehicle security controller: UWB center pcba ID";
CM_ SG_ 969 VCSEC_UWBCenterAssemblyID "Vehicle security controller: UWB center assembly ID";
CM_ SG_ 969 VCSEC_UWBCenterUsageID "Vehicle security controller: UWB center usage ID";
CM_ SG_ 969 VCSEC_BLERIGHTREARCrc "Vehicle security controller: BLERIGHTREAR crc";
CM_ SG_ 969 VCSEC_BLERIGHTREARComponentID "Vehicle security controller: BLERIGHTREAR component ID";
CM_ SG_ 969 VCSEC_BLERIGHTREARPcbaID "Vehicle security controller: BLERIGHTREAR pcba ID";
CM_ SG_ 969 VCSEC_BLERIGHTREARAssemblyID "Vehicle security controller: BLERIGHTREAR assembly ID";
CM_ SG_ 969 VCSEC_BLERIGHTREARUsageID "Vehicle security controller: BLERIGHTREAR usage ID";
CM_ SG_ 969 VCSEC_BLENFCCRADLECrc "Vehicle security controller: BLENFCCRADLE crc";
CM_ SG_ 969 VCSEC_BLENFCCRADLEComponentID "Vehicle security controller: BLENFCCRADLE component ID";
CM_ SG_ 969 VCSEC_BLENFCCRADLEPcbaID "Vehicle security controller: BLENFCCRADLE pcba ID";
CM_ SG_ 969 VCSEC_BLENFCCRADLEAssemblyID "Vehicle security controller: BLENFCCRADLE assembly ID";
CM_ SG_ 969 VCSEC_BLENFCCRADLEUsageID "Vehicle security controller: BLENFCCRADLE usage ID";
CM_ SG_ 969 VCSEC_BLELEFTREARCrc "Vehicle security controller: BLELEFTREAR crc";
CM_ SG_ 969 VCSEC_BLELEFTREARComponentID "Vehicle security controller: BLELEFTREAR component ID";
CM_ SG_ 969 VCSEC_BLELEFTREARPcbaID "Vehicle security controller: BLELEFTREAR pcba ID";
CM_ SG_ 969 VCSEC_BLELEFTREARAssemblyID "Vehicle security controller: BLELEFTREAR assembly ID";
CM_ SG_ 969 VCSEC_BLELEFTREARUsageID "Vehicle security controller: BLELEFTREAR usage ID";
CM_ BO_ 607 "Vehicle security controller message: child seat status; frame length from the layout, not yet observed on a vehicle bus";
CM_ SG_ 607 VCSEC_childSeat0_connectionState "Vehicle security controller: child seat0 connection state";
CM_ SG_ 607 VCSEC_childSeat0_taskDisconnecti "Vehicle security controller: child seat0 task disconnection reason";
CM_ SG_ 607 VCSEC_childSeat0_state "Vehicle security controller: child seat0 state";
CM_ SG_ 607 VCSEC_childSeat0_taskErrorCode "Vehicle security controller: child seat0 task error code";
CM_ SG_ 607 VCSEC_childSeat0_RSSI "Vehicle security controller: child seat0 RSSI; raw 127 = signal not available (SNA)";
CM_ SG_ 607 VCSEC_childSeat0_ISOFixStatus "Vehicle security controller: child seat0 ISO fix status";
CM_ SG_ 607 VCSEC_childSeat0_buckleStatus "Vehicle security controller: child seat0 buckle status";
CM_ SG_ 607 VCSEC_childSeat0_occupancyStatus "Vehicle security controller: child seat0 occupancy status";
CM_ SG_ 607 VCSEC_childSeat1_connectionState "Vehicle security controller: child seat1 connection state";
CM_ SG_ 607 VCSEC_childSeat1_taskDisconnecti "Vehicle security controller: child seat1 task disconnection reason";
CM_ SG_ 607 VCSEC_childSeat1_state "Vehicle security controller: child seat1 state";
CM_ SG_ 607 VCSEC_childSeat1_taskErrorCode "Vehicle security controller: child seat1 task error code";
CM_ SG_ 607 VCSEC_childSeat1_RSSI "Vehicle security controller: child seat1 RSSI; raw 127 = signal not available (SNA)";
CM_ SG_ 607 VCSEC_childSeat1_ISOFixStatus "Vehicle security controller: child seat1 ISO fix status";
CM_ SG_ 607 VCSEC_childSeat1_buckleStatus "Vehicle security controller: child seat1 buckle status";
CM_ SG_ 607 VCSEC_childSeat1_occupancyStatus "Vehicle security controller: child seat1 occupancy status";
CM_ SG_ 607 VCSEC_childPresenceDetectionWarn "Vehicle security controller: child presence detection warning active";
CM_ SG_ 607 VCSEC_childSeatScanStatus "Vehicle security controller: child seat scan status";
CM_ SG_ 607 VCSEC_childPresenceDetectionStat "Vehicle security controller: child presence detection state";
CM_ SG_ 607 VCSEC_childPresenceDetectionSupp "Vehicle security controller: child presence detection support type";
CM_ SG_ 607 VCSEC_childPresenceDetectionNoti "Vehicle security controller: child presence detection notification enabled";
CM_ BO_ 857 "Vehicle security controller message: device status; frame length from the layout, not yet observed on a vehicle bus";
CM_ SG_ 857 VCSEC_DeviceStatusIndex "Vehicle security controller: device status index";
CM_ SG_ 857 VCSEC_Device0AuthResponseTime "Slowest response of an authed key";
CM_ SG_ 857 VCSEC_Device0Impermanent "Vehicle security controller: device0 impermanent";
CM_ SG_ 857 VCSEC_Device0SELockedDown "Vehicle security controller: device0 SE locked down";
CM_ SG_ 857 VCSEC_Device0Version "Vehicle security controller: device0 version";
CM_ SG_ 857 VCSEC_Device0WLEntry "White list index of Bluetooth device 0.";
CM_ SG_ 857 VCSEC_Device0OSVersion "Vehicle security controller: device0 OS version";
CM_ SG_ 857 VCSEC_Device0BatteryLevel "Battery voltage of Bluetooth device (Only for Keyfobs)";
CM_ SG_ 857 VCSEC_Device0Formfactor "Form factor device";
CM_ SG_ 857 VCSEC_Device0BlacklistStatus "Vehicle security controller: device0 blacklist status";
CM_ SG_ 857 VCSEC_Device0Stationary "Vehicle security controller: device0 stationary";
CM_ SG_ 857 VCSEC_Device0Bonded "Vehicle security controller: device0 bonded";
CM_ SG_ 857 VCSEC_Device0Role "Vehicle security controller: device0 role";
CM_ SG_ 857 VCSEC_Device0WhitelistActiveTime "Vehicle security controller: device0 whitelist active time";
CM_ SG_ 857 VCSEC_Device0SHA1 "SHA1 of the public key of the device";
CM_ SG_ 857 VCSEC_Device0Permissions "Vehicle security controller: device0 permissions";
CM_ SG_ 857 VCSEC_Device0ManufacturerHashBit "Vehicle security controller: device0 manufacturer hash bits";
CM_ SG_ 857 VCSEC_Device0BuildNumberHashBits "Vehicle security controller: device0 build number hash bits";
CM_ SG_ 857 VCSEC_Device1AuthResponseTime "Slowest response of an authed key; raw 127 = signal not available (SNA)";
CM_ SG_ 857 VCSEC_Device1Impermanent "Vehicle security controller: device1 impermanent";
CM_ SG_ 857 VCSEC_Device1SELockedDown "Vehicle security controller: device1 SE locked down";
CM_ SG_ 857 VCSEC_Device1Version "Vehicle security controller: device1 version";
CM_ SG_ 857 VCSEC_Device1WLEntry "White list index of the device";
CM_ SG_ 857 VCSEC_Device1OSVersion "Vehicle security controller: device1 OS version";
CM_ SG_ 857 VCSEC_Device1BatteryLevel "Battery voltage of Bluetooth device (Only for Keyfobs)";
CM_ SG_ 857 VCSEC_Device1Formfactor "Form factor of the device";
CM_ SG_ 857 VCSEC_Device1BlacklistStatus "Vehicle security controller: device1 blacklist status";
CM_ SG_ 857 VCSEC_Device1Stationary "Vehicle security controller: device1 stationary";
CM_ SG_ 857 VCSEC_Device1Bonded "Vehicle security controller: device1 bonded";
CM_ SG_ 857 VCSEC_Device1Role "Vehicle security controller: device1 role";
CM_ SG_ 857 VCSEC_Device1WhitelistActiveTime "Vehicle security controller: device1 whitelist active time";
CM_ SG_ 857 VCSEC_Device1SHA1 "SHA1 of the public key of the device";
CM_ SG_ 857 VCSEC_Device1Permissions "Vehicle security controller: device1 permissions";
CM_ SG_ 857 VCSEC_Device1ManufacturerHashBit "Vehicle security controller: device1 manufacturer hash bits";
CM_ SG_ 857 VCSEC_Device1BuildNumberHashBits "Vehicle security controller: device1 build number hash bits";
CM_ SG_ 857 VCSEC_Device2AuthResponseTime "Slowest response of an authed key; raw 127 = signal not available (SNA)";
CM_ SG_ 857 VCSEC_Device2Impermanent "Vehicle security controller: device2 impermanent";
CM_ SG_ 857 VCSEC_Device2SELockedDown "Vehicle security controller: device2 SE locked down";
CM_ SG_ 857 VCSEC_Device2Version "Vehicle security controller: device2 version";
CM_ SG_ 857 VCSEC_Device2WLEntry "White list index of Bluetooth device 2.";
CM_ SG_ 857 VCSEC_Device2OSVersion "Vehicle security controller: device2 OS version";
CM_ SG_ 857 VCSEC_Device2BatteryLevel "Battery voltage of Bluetooth device (Only for Keyfobs)";
CM_ SG_ 857 VCSEC_Device2Formfactor "Form factor of the device";
CM_ SG_ 857 VCSEC_Device2BlacklistStatus "Vehicle security controller: device2 blacklist status";
CM_ SG_ 857 VCSEC_Device2Stationary "Vehicle security controller: device2 stationary";
CM_ SG_ 857 VCSEC_Device2Bonded "Vehicle security controller: device2 bonded";
CM_ SG_ 857 VCSEC_Device2Role "Vehicle security controller: device2 role";
CM_ SG_ 857 VCSEC_Device2WhitelistActiveTime "Vehicle security controller: device2 whitelist active time";
CM_ SG_ 857 VCSEC_Device2SHA1 "SHA1 of the public key of the device";
CM_ SG_ 857 VCSEC_Device2Permissions "Vehicle security controller: device2 permissions";
CM_ SG_ 857 VCSEC_Device2ManufacturerHashBit "Vehicle security controller: device2 manufacturer hash bits";
CM_ SG_ 857 VCSEC_Device2BuildNumberHashBits "Vehicle security controller: device2 build number hash bits";
CM_ SG_ 857 VCSEC_Device3AuthResponseTime "Slowest response of an authed key; raw 127 = signal not available (SNA)";
CM_ SG_ 857 VCSEC_Device3Impermanent "Vehicle security controller: device3 impermanent";
CM_ SG_ 857 VCSEC_Device3SELockedDown "Vehicle security controller: device3 SE locked down";
CM_ SG_ 857 VCSEC_Device3Version "Vehicle security controller: device3 version";
CM_ SG_ 857 VCSEC_Device3WLEntry "White list index of the device.";
CM_ SG_ 857 VCSEC_Device3OSVersion "Vehicle security controller: device3 OS version";
CM_ SG_ 857 VCSEC_Device3BatteryLevel "Battery voltage of Bluetooth device (Only for Keyfobs)";
CM_ SG_ 857 VCSEC_Device3Formfactor "Form factor of the device.";
CM_ SG_ 857 VCSEC_Device3BlacklistStatus "Vehicle security controller: device3 blacklist status";
CM_ SG_ 857 VCSEC_Device3Stationary "Vehicle security controller: device3 stationary";
CM_ SG_ 857 VCSEC_Device3Bonded "Vehicle security controller: device3 bonded";
CM_ SG_ 857 VCSEC_Device3Role "Vehicle security controller: device3 role";
CM_ SG_ 857 VCSEC_Device3WhitelistActiveTime "Vehicle security controller: device3 whitelist active time";
CM_ SG_ 857 VCSEC_Device3SHA1 "SHA1 of the public key of the device";
CM_ SG_ 857 VCSEC_Device3Permissions "Vehicle security controller: device3 permissions";
CM_ SG_ 857 VCSEC_Device3ManufacturerHashBit "Vehicle security controller: device3 manufacturer hash bits";
CM_ SG_ 857 VCSEC_Device3BuildNumberHashBits "Vehicle security controller: device3 build number hash bits";
CM_ SG_ 857 VCSEC_Device4AuthResponseTime "Slowest response of an authed key; raw 127 = signal not available (SNA)";
CM_ SG_ 857 VCSEC_Device4Impermanent "Vehicle security controller: device4 impermanent";
CM_ SG_ 857 VCSEC_Device4SELockedDown "Vehicle security controller: device4 SE locked down";
CM_ SG_ 857 VCSEC_Device4Version "Vehicle security controller: device4 version";
CM_ SG_ 857 VCSEC_Device4WLEntry "White list index of the device.";
CM_ SG_ 857 VCSEC_Device4OSVersion "Vehicle security controller: device4 OS version";
CM_ SG_ 857 VCSEC_Device4BatteryLevel "Battery voltage of Bluetooth device (Only for Keyfobs)";
CM_ SG_ 857 VCSEC_Device4Formfactor "Form factor of the device.";
CM_ SG_ 857 VCSEC_Device4BlacklistStatus "Vehicle security controller: device4 blacklist status";
CM_ SG_ 857 VCSEC_Device4Stationary "Vehicle security controller: device4 stationary";
CM_ SG_ 857 VCSEC_Device4Bonded "Vehicle security controller: device4 bonded";
CM_ SG_ 857 VCSEC_Device4Role "Vehicle security controller: device4 role";
CM_ SG_ 857 VCSEC_Device4WhitelistActiveTime "Vehicle security controller: device4 whitelist active time";
CM_ SG_ 857 VCSEC_Device4SHA1 "SHA1 of the public key of the device";
CM_ SG_ 857 VCSEC_Device4Permissions "Vehicle security controller: device4 permissions";
CM_ SG_ 857 VCSEC_Device4ManufacturerHashBit "Vehicle security controller: device4 manufacturer hash bits";
CM_ SG_ 857 VCSEC_Device4BuildNumberHashBits "Vehicle security controller: device4 build number hash bits";
CM_ SG_ 857 VCSEC_Device5AuthResponseTime "Slowest response of an authed key; raw 127 = signal not available (SNA)";
CM_ SG_ 857 VCSEC_Device5Impermanent "Vehicle security controller: device5 impermanent";
CM_ SG_ 857 VCSEC_Device5SELockedDown "Vehicle security controller: device5 SE locked down";
CM_ SG_ 857 VCSEC_Device5Version "Vehicle security controller: device5 version";
CM_ SG_ 857 VCSEC_Device5WLEntry "White list index of the device.";
CM_ SG_ 857 VCSEC_Device5OSVersion "Vehicle security controller: device5 OS version";
CM_ SG_ 857 VCSEC_Device5BatteryLevel "Battery voltage of Bluetooth device (Only for Keyfobs)";
CM_ SG_ 857 VCSEC_Device5Formfactor "Form factor of the device.";
CM_ SG_ 857 VCSEC_Device5BlacklistStatus "Vehicle security controller: device5 blacklist status";
CM_ SG_ 857 VCSEC_Device5Stationary "Vehicle security controller: device5 stationary";
CM_ SG_ 857 VCSEC_Device5Bonded "Vehicle security controller: device5 bonded";
CM_ SG_ 857 VCSEC_Device5Role "Vehicle security controller: device5 role";
CM_ SG_ 857 VCSEC_Device5WhitelistActiveTime "Vehicle security controller: device5 whitelist active time";
CM_ SG_ 857 VCSEC_Device5SHA1 "SHA1 of the public key of the device";
CM_ SG_ 857 VCSEC_Device5Permissions "Vehicle security controller: device5 permissions";
CM_ SG_ 857 VCSEC_Device5ManufacturerHashBit "Vehicle security controller: device5 manufacturer hash bits";
CM_ SG_ 857 VCSEC_Device5BuildNumberHashBits "Vehicle security controller: device5 build number hash bits";
CM_ SG_ 857 VCSEC_Device6AuthResponseTime "Slowest response of an authed key; raw 127 = signal not available (SNA)";
CM_ SG_ 857 VCSEC_Device6Impermanent "Vehicle security controller: device6 impermanent";
CM_ SG_ 857 VCSEC_Device6SELockedDown "Vehicle security controller: device6 SE locked down";
CM_ SG_ 857 VCSEC_Device6Version "Vehicle security controller: device6 version";
CM_ SG_ 857 VCSEC_Device6WLEntry "White list index of the device.";
CM_ SG_ 857 VCSEC_Device6OSVersion "Vehicle security controller: device6 OS version";
CM_ SG_ 857 VCSEC_Device6BatteryLevel "Battery voltage of Bluetooth device (Only for Keyfobs)";
CM_ SG_ 857 VCSEC_Device6Formfactor "Form factor of the device.";
CM_ SG_ 857 VCSEC_Device6BlacklistStatus "Vehicle security controller: device6 blacklist status";
CM_ SG_ 857 VCSEC_Device6Stationary "Vehicle security controller: device6 stationary";
CM_ SG_ 857 VCSEC_Device6Bonded "Vehicle security controller: device6 bonded";
CM_ SG_ 857 VCSEC_Device6Role "Vehicle security controller: device6 role";
CM_ SG_ 857 VCSEC_Device6WhitelistActiveTime "Vehicle security controller: device6 whitelist active time";
CM_ SG_ 857 VCSEC_Device6SHA1 "SHA1 of the public key of the device";
CM_ SG_ 857 VCSEC_Device6Permissions "Vehicle security controller: device6 permissions";
CM_ SG_ 857 VCSEC_Device6ManufacturerHashBit "Vehicle security controller: device6 manufacturer hash bits";
CM_ SG_ 857 VCSEC_Device6BuildNumberHashBits "Vehicle security controller: device6 build number hash bits";
CM_ SG_ 857 VCSEC_Device7AuthResponseTime "Slowest response of an authed key; raw 127 = signal not available (SNA)";
CM_ SG_ 857 VCSEC_Device7Impermanent "Vehicle security controller: device7 impermanent";
CM_ SG_ 857 VCSEC_Device7SELockedDown "Vehicle security controller: device7 SE locked down";
CM_ SG_ 857 VCSEC_Device7Version "Vehicle security controller: device7 version";
CM_ SG_ 857 VCSEC_Device7WLEntry "White list index of the device.";
CM_ SG_ 857 VCSEC_Device7OSVersion "Vehicle security controller: device7 OS version";
CM_ SG_ 857 VCSEC_Device7BatteryLevel "Battery voltage of Bluetooth device (Only for Keyfobs)";
CM_ SG_ 857 VCSEC_Device7Formfactor "Form factor of the device.";
CM_ SG_ 857 VCSEC_Device7BlacklistStatus "Vehicle security controller: device7 blacklist status";
CM_ SG_ 857 VCSEC_Device7Stationary "Vehicle security controller: device7 stationary";
CM_ SG_ 857 VCSEC_Device7Bonded "Vehicle security controller: device7 bonded";
CM_ SG_ 857 VCSEC_Device7Role "Vehicle security controller: device7 role";
CM_ SG_ 857 VCSEC_Device7WhitelistActiveTime "Vehicle security controller: device7 whitelist active time";
CM_ SG_ 857 VCSEC_Device7SHA1 "SHA1 of the public key of the device";
CM_ SG_ 857 VCSEC_Device7Permissions "Vehicle security controller: device7 permissions";
CM_ SG_ 857 VCSEC_Device7ManufacturerHashBit "Vehicle security controller: device7 manufacturer hash bits";
CM_ SG_ 857 VCSEC_Device7BuildNumberHashBits "Vehicle security controller: device7 build number hash bits";
CM_ SG_ 857 VCSEC_Device8AuthResponseTime "Slowest response of an authed key; raw 127 = signal not available (SNA)";
CM_ SG_ 857 VCSEC_Device8Impermanent "Vehicle security controller: device8 impermanent";
CM_ SG_ 857 VCSEC_Device8SELockedDown "Vehicle security controller: device8 SE locked down";
CM_ SG_ 857 VCSEC_Device8Version "Vehicle security controller: device8 version";
CM_ SG_ 857 VCSEC_Device8WLEntry "White list index of the device.";
CM_ SG_ 857 VCSEC_Device8OSVersion "Vehicle security controller: device8 OS version";
CM_ SG_ 857 VCSEC_Device8BatteryLevel "Battery voltage of Bluetooth device (Only for Keyfobs)";
CM_ SG_ 857 VCSEC_Device8Formfactor "Form factor of the device.";
CM_ SG_ 857 VCSEC_Device8BlacklistStatus "Vehicle security controller: device8 blacklist status";
CM_ SG_ 857 VCSEC_Device8Stationary "Vehicle security controller: device8 stationary";
CM_ SG_ 857 VCSEC_Device8Bonded "Vehicle security controller: device8 bonded";
CM_ SG_ 857 VCSEC_Device8Role "Vehicle security controller: device8 role";
CM_ SG_ 857 VCSEC_Device8WhitelistActiveTime "Vehicle security controller: device8 whitelist active time";
CM_ SG_ 857 VCSEC_Device8SHA1 "SHA1 of the public key of the device";
CM_ SG_ 857 VCSEC_Device8Permissions "Vehicle security controller: device8 permissions";
CM_ SG_ 857 VCSEC_Device8ManufacturerHashBit "Vehicle security controller: device8 manufacturer hash bits";
CM_ SG_ 857 VCSEC_Device8BuildNumberHashBits "Vehicle security controller: device8 build number hash bits";
CM_ SG_ 857 VCSEC_Device9AuthResponseTime "Slowest response of an authed key; raw 127 = signal not available (SNA)";
CM_ SG_ 857 VCSEC_Device9Impermanent "Vehicle security controller: device9 impermanent";
CM_ SG_ 857 VCSEC_Device9SELockedDown "Vehicle security controller: device9 SE locked down";
CM_ SG_ 857 VCSEC_Device9Version "Vehicle security controller: device9 version";
CM_ SG_ 857 VCSEC_Device9WLEntry "White list index of the device.";
CM_ SG_ 857 VCSEC_Device9OSVersion "Vehicle security controller: device9 OS version";
CM_ SG_ 857 VCSEC_Device9BatteryLevel "Battery voltage of Bluetooth device (Only for Keyfobs)";
CM_ SG_ 857 VCSEC_Device9Formfactor "Form factor of the device.";
CM_ SG_ 857 VCSEC_Device9BlacklistStatus "Vehicle security controller: device9 blacklist status";
CM_ SG_ 857 VCSEC_Device9Stationary "Vehicle security controller: device9 stationary";
CM_ SG_ 857 VCSEC_Device9Bonded "Vehicle security controller: device9 bonded";
CM_ SG_ 857 VCSEC_Device9Role "Vehicle security controller: device9 role";
CM_ SG_ 857 VCSEC_Device9WhitelistActiveTime "Vehicle security controller: device9 whitelist active time";
CM_ SG_ 857 VCSEC_Device9SHA1 "SHA1 of the public key of the device";
CM_ SG_ 857 VCSEC_Device9Permissions "Vehicle security controller: device9 permissions";
CM_ SG_ 857 VCSEC_Device9ManufacturerHashBit "Vehicle security controller: device9 manufacturer hash bits";
CM_ SG_ 857 VCSEC_Device9BuildNumberHashBits "Vehicle security controller: device9 build number hash bits";
CM_ SG_ 857 VCSEC_Device10AuthResponseTime "Slowest response of an authed key; raw 127 = signal not available (SNA)";
CM_ SG_ 857 VCSEC_Device10Impermanent "Vehicle security controller: device10 impermanent";
CM_ SG_ 857 VCSEC_Device10SELockedDown "Vehicle security controller: device10 SE locked down";
CM_ SG_ 857 VCSEC_Device10Version "Vehicle security controller: device10 version";
CM_ SG_ 857 VCSEC_Device10WLEntry "White list index of the device.";
CM_ SG_ 857 VCSEC_Device10OSVersion "Vehicle security controller: device10 OS version";
CM_ SG_ 857 VCSEC_Device10BatteryLevel "Battery voltage of Bluetooth device (Only for Keyfobs)";
CM_ SG_ 857 VCSEC_Device10Formfactor "Form factor of the device.";
CM_ SG_ 857 VCSEC_Device10BlacklistStatus "Vehicle security controller: device10 blacklist status";
CM_ SG_ 857 VCSEC_Device10Stationary "Vehicle security controller: device10 stationary";
CM_ SG_ 857 VCSEC_Device10Bonded "Vehicle security controller: device10 bonded";
CM_ SG_ 857 VCSEC_Device10Role "Vehicle security controller: device10 role";
CM_ SG_ 857 VCSEC_Device10WhitelistActiveTim "Vehicle security controller: device10 whitelist active time";
CM_ SG_ 857 VCSEC_Device10SHA1 "SHA1 of the public key of the device";
CM_ SG_ 857 VCSEC_Device10Permissions "Vehicle security controller: device10 permissions";
CM_ SG_ 857 VCSEC_Device10ManufacturerHashBi "Vehicle security controller: device10 manufacturer hash bits";
CM_ SG_ 857 VCSEC_Device10BuildNumberHashBit "Vehicle security controller: device10 build number hash bits";
CM_ SG_ 857 VCSEC_Device11AuthResponseTime "Slowest response of an authed key; raw 127 = signal not available (SNA)";
CM_ SG_ 857 VCSEC_Device11Impermanent "Vehicle security controller: device11 impermanent";
CM_ SG_ 857 VCSEC_Device11SELockedDown "Vehicle security controller: device11 SE locked down";
CM_ SG_ 857 VCSEC_Device11Version "Vehicle security controller: device11 version";
CM_ SG_ 857 VCSEC_Device11WLEntry "White list index of the device.";
CM_ SG_ 857 VCSEC_Device11OSVersion "Vehicle security controller: device11 OS version";
CM_ SG_ 857 VCSEC_Device11BatteryLevel "Battery voltage of Bluetooth device (Only for Keyfobs)";
CM_ SG_ 857 VCSEC_Device11Formfactor "Form factor of the device.";
CM_ SG_ 857 VCSEC_Device11BlacklistStatus "Vehicle security controller: device11 blacklist status";
CM_ SG_ 857 VCSEC_Device11Stationary "Vehicle security controller: device11 stationary";
CM_ SG_ 857 VCSEC_Device11Bonded "Vehicle security controller: device11 bonded";
CM_ SG_ 857 VCSEC_Device11Role "Vehicle security controller: device11 role";
CM_ SG_ 857 VCSEC_Device11WhitelistActiveTim "Vehicle security controller: device11 whitelist active time";
CM_ SG_ 857 VCSEC_Device11SHA1 "SHA1 of the public key of the device";
CM_ SG_ 857 VCSEC_Device11Permissions "Vehicle security controller: device11 permissions";
CM_ SG_ 857 VCSEC_Device11ManufacturerHashBi "Vehicle security controller: device11 manufacturer hash bits";
CM_ SG_ 857 VCSEC_Device11BuildNumberHashBit "Vehicle security controller: device11 build number hash bits";
CM_ SG_ 857 VCSEC_Device12AuthResponseTime "Slowest response of an authed key; raw 127 = signal not available (SNA)";
CM_ SG_ 857 VCSEC_Device12Impermanent "Vehicle security controller: device12 impermanent";
CM_ SG_ 857 VCSEC_Device12SELockedDown "Vehicle security controller: device12 SE locked down";
CM_ SG_ 857 VCSEC_Device12Version "Vehicle security controller: device12 version";
CM_ SG_ 857 VCSEC_Device12WLEntry "White list index of the device.";
CM_ SG_ 857 VCSEC_Device12OSVersion "Vehicle security controller: device12 OS version";
CM_ SG_ 857 VCSEC_Device12BatteryLevel "Battery voltage of Bluetooth device (Only for Keyfobs)";
CM_ SG_ 857 VCSEC_Device12Formfactor "Form factor of the device.";
CM_ SG_ 857 VCSEC_Device12BlacklistStatus "Vehicle security controller: device12 blacklist status";
CM_ SG_ 857 VCSEC_Device12Stationary "Vehicle security controller: device12 stationary";
CM_ SG_ 857 VCSEC_Device12Bonded "Vehicle security controller: device12 bonded";
CM_ SG_ 857 VCSEC_Device12Role "Vehicle security controller: device12 role";
CM_ SG_ 857 VCSEC_Device12WhitelistActiveTim "Vehicle security controller: device12 whitelist active time";
CM_ SG_ 857 VCSEC_Device12SHA1 "SHA1 of the public key of the device";
CM_ SG_ 857 VCSEC_Device12Permissions "Vehicle security controller: device12 permissions";
CM_ SG_ 857 VCSEC_Device12ManufacturerHashBi "Vehicle security controller: device12 manufacturer hash bits";
CM_ SG_ 857 VCSEC_Device12BuildNumberHashBit "Vehicle security controller: device12 build number hash bits";
CM_ SG_ 857 VCSEC_Device13AuthResponseTime "Slowest response of an authed key; raw 127 = signal not available (SNA)";
CM_ SG_ 857 VCSEC_Device13Impermanent "Vehicle security controller: device13 impermanent";
CM_ SG_ 857 VCSEC_Device13SELockedDown "Vehicle security controller: device13 SE locked down";
CM_ SG_ 857 VCSEC_Device13Version "Vehicle security controller: device13 version";
CM_ SG_ 857 VCSEC_Device13WLEntry "White list index of the device.";
CM_ SG_ 857 VCSEC_Device13OSVersion "Vehicle security controller: device13 OS version";
CM_ SG_ 857 VCSEC_Device13BatteryLevel "Battery voltage of Bluetooth device (Only for Keyfobs)";
CM_ SG_ 857 VCSEC_Device13Formfactor "Form factor of the device.";
CM_ SG_ 857 VCSEC_Device13BlacklistStatus "Vehicle security controller: device13 blacklist status";
CM_ SG_ 857 VCSEC_Device13Stationary "Vehicle security controller: device13 stationary";
CM_ SG_ 857 VCSEC_Device13Bonded "Vehicle security controller: device13 bonded";
CM_ SG_ 857 VCSEC_Device13Role "Vehicle security controller: device13 role";
CM_ SG_ 857 VCSEC_Device13WhitelistActiveTim "Vehicle security controller: device13 whitelist active time";
CM_ SG_ 857 VCSEC_Device13SHA1 "SHA1 of the public key of the device";
CM_ SG_ 857 VCSEC_Device13Permissions "Vehicle security controller: device13 permissions";
CM_ SG_ 857 VCSEC_Device13ManufacturerHashBi "Vehicle security controller: device13 manufacturer hash bits";
CM_ SG_ 857 VCSEC_Device13BuildNumberHashBit "Vehicle security controller: device13 build number hash bits";
CM_ SG_ 857 VCSEC_Device14AuthResponseTime "Slowest response of an authed key; raw 127 = signal not available (SNA)";
CM_ SG_ 857 VCSEC_Device14Impermanent "Vehicle security controller: device14 impermanent";
CM_ SG_ 857 VCSEC_Device14SELockedDown "Vehicle security controller: device14 SE locked down";
CM_ SG_ 857 VCSEC_Device14Version "Vehicle security controller: device14 version";
CM_ SG_ 857 VCSEC_Device14WLEntry "White list index of the device.";
CM_ SG_ 857 VCSEC_Device14OSVersion "Vehicle security controller: device14 OS version";
CM_ SG_ 857 VCSEC_Device14BatteryLevel "Battery voltage of Bluetooth device (Only for Keyfobs)";
CM_ SG_ 857 VCSEC_Device14Formfactor "Form factor of the device.";
CM_ SG_ 857 VCSEC_Device14BlacklistStatus "Vehicle security controller: device14 blacklist status";
CM_ SG_ 857 VCSEC_Device14Stationary "Vehicle security controller: device14 stationary";
CM_ SG_ 857 VCSEC_Device14Bonded "Vehicle security controller: device14 bonded";
CM_ SG_ 857 VCSEC_Device14Role "Vehicle security controller: device14 role";
CM_ SG_ 857 VCSEC_Device14WhitelistActiveTim "Vehicle security controller: device14 whitelist active time";
CM_ SG_ 857 VCSEC_Device14SHA1 "SHA1 of the public key of the device";
CM_ SG_ 857 VCSEC_Device14Permissions "Vehicle security controller: device14 permissions";
CM_ SG_ 857 VCSEC_Device14ManufacturerHashBi "Vehicle security controller: device14 manufacturer hash bits";
CM_ SG_ 857 VCSEC_Device14BuildNumberHashBit "Vehicle security controller: device14 build number hash bits";
CM_ SG_ 857 VCSEC_Device15AuthResponseTime "Slowest response of an authed key; raw 127 = signal not available (SNA)";
CM_ SG_ 857 VCSEC_Device15Impermanent "Vehicle security controller: device15 impermanent";
CM_ SG_ 857 VCSEC_Device15SELockedDown "Vehicle security controller: device15 SE locked down";
CM_ SG_ 857 VCSEC_Device15Version "Vehicle security controller: device15 version";
CM_ SG_ 857 VCSEC_Device15WLEntry "White list index of the device.";
CM_ SG_ 857 VCSEC_Device15OSVersion "Vehicle security controller: device15 OS version";
CM_ SG_ 857 VCSEC_Device15BatteryLevel "Battery voltage of Bluetooth device (Only for Keyfobs)";
CM_ SG_ 857 VCSEC_Device15Formfactor "Form factor of the device.";
CM_ SG_ 857 VCSEC_Device15BlacklistStatus "Vehicle security controller: device15 blacklist status";
CM_ SG_ 857 VCSEC_Device15Stationary "Vehicle security controller: device15 stationary";
CM_ SG_ 857 VCSEC_Device15Bonded "Vehicle security controller: device15 bonded";
CM_ SG_ 857 VCSEC_Device15Role "Vehicle security controller: device15 role";
CM_ SG_ 857 VCSEC_Device15WhitelistActiveTim "Vehicle security controller: device15 whitelist active time";
CM_ SG_ 857 VCSEC_Device15SHA1 "SHA1 of the public key of the device";
CM_ SG_ 857 VCSEC_Device15Permissions "Vehicle security controller: device15 permissions";
CM_ SG_ 857 VCSEC_Device15ManufacturerHashBi "Vehicle security controller: device15 manufacturer hash bits";
CM_ SG_ 857 VCSEC_Device15BuildNumberHashBit "Vehicle security controller: device15 build number hash bits";
CM_ SG_ 857 VCSEC_Device16AuthResponseTime "Slowest response of an authed key; raw 127 = signal not available (SNA)";
CM_ SG_ 857 VCSEC_Device16Impermanent "Vehicle security controller: device16 impermanent";
CM_ SG_ 857 VCSEC_Device16SELockedDown "Vehicle security controller: device16 SE locked down";
CM_ SG_ 857 VCSEC_Device16Version "Vehicle security controller: device16 version";
CM_ SG_ 857 VCSEC_Device16WLEntry "White list index of the device.";
CM_ SG_ 857 VCSEC_Device16OSVersion "Vehicle security controller: device16 OS version";
CM_ SG_ 857 VCSEC_Device16BatteryLevel "Battery voltage of Bluetooth device (Only for Keyfobs)";
CM_ SG_ 857 VCSEC_Device16Formfactor "Form factor of the device.";
CM_ SG_ 857 VCSEC_Device16BlacklistStatus "Vehicle security controller: device16 blacklist status";
CM_ SG_ 857 VCSEC_Device16Stationary "Vehicle security controller: device16 stationary";
CM_ SG_ 857 VCSEC_Device16Bonded "Vehicle security controller: device16 bonded";
CM_ SG_ 857 VCSEC_Device16Role "Vehicle security controller: device16 role";
CM_ SG_ 857 VCSEC_Device16WhitelistActiveTim "Vehicle security controller: device16 whitelist active time";
CM_ SG_ 857 VCSEC_Device16SHA1 "SHA1 of the public key of the device";
CM_ SG_ 857 VCSEC_Device16Permissions "Vehicle security controller: device16 permissions";
CM_ SG_ 857 VCSEC_Device16ManufacturerHashBi "Vehicle security controller: device16 manufacturer hash bits";
CM_ SG_ 857 VCSEC_Device16BuildNumberHashBit "Vehicle security controller: device16 build number hash bits";
CM_ SG_ 857 VCSEC_Device17AuthResponseTime "Slowest response of an authed key; raw 127 = signal not available (SNA)";
CM_ SG_ 857 VCSEC_Device17Impermanent "Vehicle security controller: device17 impermanent";
CM_ SG_ 857 VCSEC_Device17SELockedDown "Vehicle security controller: device17 SE locked down";
CM_ SG_ 857 VCSEC_Device17Version "Vehicle security controller: device17 version";
CM_ SG_ 857 VCSEC_Device17WLEntry "White list index of the device.";
CM_ SG_ 857 VCSEC_Device17OSVersion "Vehicle security controller: device17 OS version";
CM_ SG_ 857 VCSEC_Device17BatteryLevel "Battery voltage of Bluetooth device (Only for Keyfobs)";
CM_ SG_ 857 VCSEC_Device17Formfactor "Form factor of the device.";
CM_ SG_ 857 VCSEC_Device17BlacklistStatus "Vehicle security controller: device17 blacklist status";
CM_ SG_ 857 VCSEC_Device17Stationary "Vehicle security controller: device17 stationary";
CM_ SG_ 857 VCSEC_Device17Bonded "Vehicle security controller: device17 bonded";
CM_ SG_ 857 VCSEC_Device17Role "Vehicle security controller: device17 role";
CM_ SG_ 857 VCSEC_Device17WhitelistActiveTim "Vehicle security controller: device17 whitelist active time";
CM_ SG_ 857 VCSEC_Device17SHA1 "SHA1 of the public key of the device";
CM_ SG_ 857 VCSEC_Device17Permissions "Vehicle security controller: device17 permissions";
CM_ SG_ 857 VCSEC_Device17ManufacturerHashBi "Vehicle security controller: device17 manufacturer hash bits";
CM_ SG_ 857 VCSEC_Device17BuildNumberHashBit "Vehicle security controller: device17 build number hash bits";
CM_ SG_ 857 VCSEC_Device18AuthResponseTime "Slowest response of an authed key; raw 127 = signal not available (SNA)";
CM_ SG_ 857 VCSEC_Device18Impermanent "Vehicle security controller: device18 impermanent";
CM_ SG_ 857 VCSEC_Device18SELockedDown "Vehicle security controller: device18 SE locked down";
CM_ SG_ 857 VCSEC_Device18Version "Vehicle security controller: device18 version";
CM_ SG_ 857 VCSEC_Device18WLEntry "White list index of the device.";
CM_ SG_ 857 VCSEC_Device18OSVersion "Vehicle security controller: device18 OS version";
CM_ SG_ 857 VCSEC_Device18BatteryLevel "Battery voltage of Bluetooth device (Only for Keyfobs)";
CM_ SG_ 857 VCSEC_Device18Formfactor "Form factor of the device.";
CM_ SG_ 857 VCSEC_Device18BlacklistStatus "Vehicle security controller: device18 blacklist status";
CM_ SG_ 857 VCSEC_Device18Stationary "Vehicle security controller: device18 stationary";
CM_ SG_ 857 VCSEC_Device18Bonded "Vehicle security controller: device18 bonded";
CM_ SG_ 857 VCSEC_Device18Role "Vehicle security controller: device18 role";
CM_ SG_ 857 VCSEC_Device18WhitelistActiveTim "Vehicle security controller: device18 whitelist active time";
CM_ SG_ 857 VCSEC_Device18SHA1 "SHA1 of the public key of the device";
CM_ SG_ 857 VCSEC_Device18Permissions "Vehicle security controller: device18 permissions";
CM_ SG_ 857 VCSEC_Device18ManufacturerHashBi "Vehicle security controller: device18 manufacturer hash bits";
CM_ SG_ 857 VCSEC_Device18BuildNumberHashBit "Vehicle security controller: device18 build number hash bits";
CM_ SG_ 857 VCSEC_Device19AuthResponseTime "Slowest response of an authed key; raw 127 = signal not available (SNA)";
CM_ SG_ 857 VCSEC_Device19Impermanent "Vehicle security controller: device19 impermanent";
CM_ SG_ 857 VCSEC_Device19SELockedDown "Vehicle security controller: device19 SE locked down";
CM_ SG_ 857 VCSEC_Device19Version "Vehicle security controller: device19 version";
CM_ SG_ 857 VCSEC_Device19WLEntry "White list index of the device.";
CM_ SG_ 857 VCSEC_Device19OSVersion "Vehicle security controller: device19 OS version";
CM_ SG_ 857 VCSEC_Device19BatteryLevel "Battery voltage of Bluetooth device (Only for Keyfobs)";
CM_ SG_ 857 VCSEC_Device19Formfactor "Form factor of the device.";
CM_ SG_ 857 VCSEC_Device19BlacklistStatus "Vehicle security controller: device19 blacklist status";
CM_ SG_ 857 VCSEC_Device19Stationary "Vehicle security controller: device19 stationary";
CM_ SG_ 857 VCSEC_Device19Bonded "Vehicle security controller: device19 bonded";
CM_ SG_ 857 VCSEC_Device19Role "Vehicle security controller: device19 role";
CM_ SG_ 857 VCSEC_Device19WhitelistActiveTim "Vehicle security controller: device19 whitelist active time";
CM_ SG_ 857 VCSEC_Device19SHA1 "SHA1 of the public key of the device";
CM_ SG_ 857 VCSEC_Device19Permissions "Vehicle security controller: device19 permissions";
CM_ SG_ 857 VCSEC_Device19ManufacturerHashBi "Vehicle security controller: device19 manufacturer hash bits";
CM_ SG_ 857 VCSEC_Device19BuildNumberHashBit "Vehicle security controller: device19 build number hash bits";
CM_ BO_ 953 "Vehicle security controller message; frame length from the layout, not yet observed on a vehicle bus";
CM_ SG_ 953 VCSEC_IsoTpPipeODIN0 "Vehicle security controller: iso tp pipe ODIN0";
CM_ SG_ 953 VCSEC_IsoTpPipeODIN1 "Vehicle security controller: iso tp pipe ODIN1";
CM_ SG_ 953 VCSEC_IsoTpPipeODIN2 "Vehicle security controller: iso tp pipe ODIN2";
CM_ SG_ 953 VCSEC_IsoTpPipeODIN3 "Vehicle security controller: iso tp pipe ODIN3";
CM_ SG_ 953 VCSEC_IsoTpPipeODIN4 "Vehicle security controller: iso tp pipe ODIN4";
CM_ SG_ 953 VCSEC_IsoTpPipeODIN5 "Vehicle security controller: iso tp pipe ODIN5";
CM_ SG_ 953 VCSEC_IsoTpPipeODIN6 "Vehicle security controller: iso tp pipe ODIN6";
CM_ SG_ 953 VCSEC_IsoTpPipeODIN7 "Vehicle security controller: iso tp pipe ODIN7";
CM_ BO_ 474 "Vehicle security controller message: iso tp pipe remote UI; frame length from the layout, not yet observed on a vehicle bus";
CM_ SG_ 474 VCSEC_IsoTpRemoteUI0 "Vehicle security controller: iso tp remote UI0";
CM_ SG_ 474 VCSEC_IsoTpRemoteUI1 "Vehicle security controller: iso tp remote UI1";
CM_ SG_ 474 VCSEC_IsoTpRemoteUI2 "Vehicle security controller: iso tp remote UI2";
CM_ SG_ 474 VCSEC_IsoTpRemoteUI3 "Vehicle security controller: iso tp remote UI3";
CM_ SG_ 474 VCSEC_IsoTpRemoteUI4 "Vehicle security controller: iso tp remote UI4";
CM_ SG_ 474 VCSEC_IsoTpRemoteUI5 "Vehicle security controller: iso tp remote UI5";
CM_ SG_ 474 VCSEC_IsoTpRemoteUI6 "Vehicle security controller: iso tp remote UI6";
CM_ SG_ 474 VCSEC_IsoTpRemoteUI7 "Vehicle security controller: iso tp remote UI7";
CM_ BO_ 473 "Vehicle security controller message: iso tp UDP pipe UI; frame length from the layout, not yet observed on a vehicle bus";
CM_ SG_ 473 VCSEC_IsoTpUDPPipeUI0 "Vehicle security controller: iso tp UDP pipe UI0";
CM_ SG_ 473 VCSEC_IsoTpUDPPipeUI1 "Vehicle security controller: iso tp UDP pipe UI1";
CM_ SG_ 473 VCSEC_IsoTpUDPPipeUI2 "Vehicle security controller: iso tp UDP pipe UI2";
CM_ SG_ 473 VCSEC_IsoTpUDPPipeUI3 "Vehicle security controller: iso tp UDP pipe UI3";
CM_ SG_ 473 VCSEC_IsoTpUDPPipeUI4 "Vehicle security controller: iso tp UDP pipe UI4";
CM_ SG_ 473 VCSEC_IsoTpUDPPipeUI5 "Vehicle security controller: iso tp UDP pipe UI5";
CM_ SG_ 473 VCSEC_IsoTpUDPPipeUI6 "Vehicle security controller: iso tp UDP pipe UI6";
CM_ SG_ 473 VCSEC_IsoTpUDPPipeUI7 "Vehicle security controller: iso tp UDP pipe UI7";
CM_ BO_ 1066 "Vehicle security controller message: TPMS connection data; frame length from the layout, not yet observed on a vehicle bus";
CM_ SG_ 1066 VCSEC_TPMSSensorState0 "Indicates the sensors pairing/connectivity status";
CM_ SG_ 1066 VCSEC_TPMSRSSI0 "Received Signal Strength Index reported by sensor.";
CM_ SG_ 1066 VCSEC_TPMSConnectionTypeCurrent0 "Vehicle security controller: TPMS connection type current0";
CM_ SG_ 1066 VCSEC_TPMSConnectionTypeDesired0 "Vehicle security controller: TPMS connection type desired0";
CM_ SG_ 1066 VCSEC_TPMSSensorState1 "Indicates the sensors pairing/connectivity status";
CM_ SG_ 1066 VCSEC_TPMSRSSI1 "Received Signal Strength Index reported by sensor.";
CM_ SG_ 1066 VCSEC_TPMSConnectionTypeCurrent1 "Vehicle security controller: TPMS connection type current1";
CM_ SG_ 1066 VCSEC_TPMSConnectionTypeDesired1 "Vehicle security controller: TPMS connection type desired1";
CM_ SG_ 1066 VCSEC_TPMSSensorState2 "Indicates the sensors pairing/connectivity status";
CM_ SG_ 1066 VCSEC_TPMSRSSI2 "Received Signal Strength Index reported by sensor.";
CM_ SG_ 1066 VCSEC_TPMSConnectionTypeCurrent2 "Vehicle security controller: TPMS connection type current2";
CM_ SG_ 1066 VCSEC_TPMSConnectionTypeDesired2 "Vehicle security controller: TPMS connection type desired2";
CM_ SG_ 1066 VCSEC_TPMSSensorState3 "Indicates the sensors pairing/connectivity status";
CM_ SG_ 1066 VCSEC_TPMSRSSI3 "Received Signal Strength Index reported by sensor.";
CM_ SG_ 1066 VCSEC_TPMSConnectionTypeCurrent3 "Vehicle security controller: TPMS connection type current3";
CM_ SG_ 1066 VCSEC_TPMSConnectionTypeDesired3 "Vehicle security controller: TPMS connection type desired3";
CM_ SG_ 1066 VCSEC_TPMSSensorPresence0 "Indicates the sensors detection status";
CM_ SG_ 1066 VCSEC_TPMSSensorPresence1 "Indicates the sensors detection status";
CM_ SG_ 1066 VCSEC_TPMSSensorPresence2 "Indicates the sensors detection status";
CM_ SG_ 1066 VCSEC_TPMSSensorPresence3 "Indicates the sensors detection status";
BA_DEF_ BO_ "GenMsgCycleTime" INT 0 3600000;
BA_DEF_ BO_ "GenMsgSendType" ENUM "Cyclic","NotUsed","NotUsed","NotUsed","NotUsed","NotUsed","NotUsed","IfActive","NoMsgSendType","NotUsed";
BA_DEF_ BO_ "VFrameFormat" ENUM "StandardCAN","ExtendedCAN","reserved","J1939PG","reserved","reserved","reserved","reserved","reserved","reserved","reserved","reserved","reserved","reserved","StandardCAN_FD","ExtendedCAN_FD";
BA_DEF_ BO_ "CANFD_BRS" ENUM "0","1";
BA_DEF_ SG_ "GenSigSNA" STRING;
BA_DEF_ SG_ "SystemSignalLongSymbol" STRING;
BA_DEF_ SG_ "Confidence" ENUM "validated","plausible","layout-only","contradicted";
BA_DEF_DEF_ "GenMsgCycleTime" 0;
BA_DEF_DEF_ "GenMsgSendType" "NoMsgSendType";
BA_DEF_DEF_ "VFrameFormat" "StandardCAN";
BA_DEF_DEF_ "CANFD_BRS" "1";
BA_DEF_DEF_ "GenSigSNA" "";
BA_DEF_DEF_ "SystemSignalLongSymbol" "";
BA_DEF_DEF_ "Confidence" "layout-only";
BA_ "GenMsgCycleTime" BO_ 963 100;
BA_ "GenMsgSendType" BO_ 963 0;
BA_ "GenMsgCycleTime" BO_ 899 100;
BA_ "GenMsgSendType" BO_ 899 0;
BA_ "GenMsgCycleTime" BO_ 1059 100;
BA_ "GenMsgSendType" BO_ 1059 0;
BA_ "GenMsgCycleTime" BO_ 707 100;
BA_ "GenMsgSendType" BO_ 707 0;
BA_ "GenMsgCycleTime" BO_ 969 1000;
BA_ "GenMsgSendType" BO_ 969 0;
BA_ "GenMsgCycleTime" BO_ 607 500;
BA_ "GenMsgSendType" BO_ 607 0;
BA_ "GenMsgCycleTime" BO_ 857 100;
BA_ "GenMsgSendType" BO_ 857 0;
BA_ "GenMsgCycleTime" BO_ 1066 200;
BA_ "GenMsgSendType" BO_ 1066 0;
BA_ "Confidence" SG_ 963 VCRIGHT_switchStatusIndex 1;
BA_ "Confidence" SG_ 963 VCRIGHT_btnWindowUpRF 1;
BA_ "Confidence" SG_ 963 VCRIGHT_btnWindowAutoUpRF 1;
BA_ "Confidence" SG_ 963 VCRIGHT_btnWindowDownRF 1;
BA_ "Confidence" SG_ 963 VCRIGHT_btnWindowAutoDownRF 1;
BA_ "Confidence" SG_ 963 VCRIGHT_btnWindowUpRR 1;
BA_ "Confidence" SG_ 963 VCRIGHT_btnWindowAutoUpRR 1;
BA_ "Confidence" SG_ 963 VCRIGHT_btnWindowDownRR 1;
BA_ "Confidence" SG_ 963 VCRIGHT_btnWindowAutoDownRR 1;
BA_ "Confidence" SG_ 963 VCRIGHT_btnWindowSwPackUpLF 1;
BA_ "Confidence" SG_ 963 VCRIGHT_btnWindowSwPackAutoUpLF 1;
BA_ "Confidence" SG_ 963 VCRIGHT_btnWindowSwPackDownLF 1;
BA_ "Confidence" SG_ 963 VCRIGHT_btnWindowSwPackAutoDwnLF 1;
BA_ "Confidence" SG_ 963 VCRIGHT_btnWindowSwPackUpLR 1;
BA_ "Confidence" SG_ 963 VCRIGHT_btnWindowSwPackAutoUpLR 1;
BA_ "Confidence" SG_ 963 VCRIGHT_btnWindowSwPackDownLR 1;
BA_ "Confidence" SG_ 963 VCRIGHT_btnWindowSwPackAutoDwnLR 1;
BA_ "Confidence" SG_ 963 VCRIGHT_frontOccupancySwitch 1;
BA_ "Confidence" SG_ 963 VCRIGHT_trunkExtReleasePressed 1;
BA_ "Confidence" SG_ 963 VCRIGHT_btnWindowSwPackUpRR 1;
BA_ "Confidence" SG_ 963 VCRIGHT_btnWindowSwPackAutoUpRR 1;
BA_ "Confidence" SG_ 963 VCRIGHT_btnWindowSwPackDownRR 1;
BA_ "Confidence" SG_ 963 VCRIGHT_btnWindowSwPackAutoDwnRR 1;
BA_ "Confidence" SG_ 963 VCRIGHT_frontBuckleSwitch 1;
BA_ "Confidence" SG_ 963 VCRIGHT_rearCenterBuckleSwitch 1;
BA_ "Confidence" SG_ 963 VCRIGHT_rearRightBuckleSwitch 1;
BA_ "Confidence" SG_ 963 VCRIGHT_trunkExtReleasePressedPe 0;
BA_ "SystemSignalLongSymbol" SG_ 963 VCRIGHT_trunkExtReleasePressedPe "VCRIGHT_trunkExtReleasePressedPersist";
BA_ "Confidence" SG_ 963 VCRIGHT_frontSeatTrackBack 0;
BA_ "GenSigSNA" SG_ 963 VCRIGHT_frontSeatTrackBack "0";
BA_ "Confidence" SG_ 963 VCRIGHT_frontSeatTrackForward 0;
BA_ "GenSigSNA" SG_ 963 VCRIGHT_frontSeatTrackForward "0";
BA_ "Confidence" SG_ 963 VCRIGHT_frontSeatTiltDown 0;
BA_ "GenSigSNA" SG_ 963 VCRIGHT_frontSeatTiltDown "0";
BA_ "Confidence" SG_ 963 VCRIGHT_frontSeatTiltUp 0;
BA_ "GenSigSNA" SG_ 963 VCRIGHT_frontSeatTiltUp "0";
BA_ "Confidence" SG_ 963 VCRIGHT_frontSeatLiftDown 0;
BA_ "GenSigSNA" SG_ 963 VCRIGHT_frontSeatLiftDown "0";
BA_ "Confidence" SG_ 963 VCRIGHT_frontSeatLiftUp 0;
BA_ "GenSigSNA" SG_ 963 VCRIGHT_frontSeatLiftUp "0";
BA_ "Confidence" SG_ 963 VCRIGHT_frontSeatBackrestBack 0;
BA_ "GenSigSNA" SG_ 963 VCRIGHT_frontSeatBackrestBack "0";
BA_ "Confidence" SG_ 963 VCRIGHT_frontSeatBackrestForward 0;
BA_ "GenSigSNA" SG_ 963 VCRIGHT_frontSeatBackrestForward "0";
BA_ "Confidence" SG_ 963 VCRIGHT_frontSeatLumbarDown 0;
BA_ "GenSigSNA" SG_ 963 VCRIGHT_frontSeatLumbarDown "0";
BA_ "Confidence" SG_ 963 VCRIGHT_frontSeatLumbarUp 0;
BA_ "GenSigSNA" SG_ 963 VCRIGHT_frontSeatLumbarUp "0";
BA_ "Confidence" SG_ 963 VCRIGHT_frontSeatLumbarIn 0;
BA_ "GenSigSNA" SG_ 963 VCRIGHT_frontSeatLumbarIn "0";
BA_ "Confidence" SG_ 963 VCRIGHT_frontSeatResistiveOccupa 0;
BA_ "GenSigSNA" SG_ 963 VCRIGHT_frontSeatResistiveOccupa "0";
BA_ "SystemSignalLongSymbol" SG_ 963 VCRIGHT_frontSeatResistiveOccupa "VCRIGHT_frontSeatResistiveOccupancy";
BA_ "Confidence" SG_ 963 VCRIGHT_2RowSeatReclineSwitchpac 0;
BA_ "SystemSignalLongSymbol" SG_ 963 VCRIGHT_2RowSeatReclineSwitchpac "VCRIGHT_2RowSeatReclineSwitchpackState";
BA_ "Confidence" SG_ 963 VCRIGHT_hvacHeatingAllowedRight 0;
BA_ "Confidence" SG_ 963 VCRIGHT_frontSeatThighSupportRet 0;
BA_ "GenSigSNA" SG_ 963 VCRIGHT_frontSeatThighSupportRet "0";
BA_ "SystemSignalLongSymbol" SG_ 963 VCRIGHT_frontSeatThighSupportRet "VCRIGHT_frontSeatThighSupportRetractSwitch";
BA_ "Confidence" SG_ 899 VCRIGHT_thsActive 0;
BA_ "Confidence" SG_ 899 VCRIGHT_thsTemperature 0;
BA_ "GenSigSNA" SG_ 899 VCRIGHT_thsTemperature "255";
BA_ "Confidence" SG_ 899 VCRIGHT_thsState 0;
BA_ "Confidence" SG_ 899 VCRIGHT_thsLINCurrentSchedule 0;
BA_ "Confidence" SG_ 899 VCRIGHT_thsDetected 0;
BA_ "Confidence" SG_ 899 VCRIGHT_thsHumidity 0;
BA_ "GenSigSNA" SG_ 899 VCRIGHT_thsHumidity "127";
BA_ "Confidence" SG_ 899 VCRIGHT_estimatedVehicleSituatio 0;
BA_ "SystemSignalLongSymbol" SG_ 899 VCRIGHT_estimatedVehicleSituatio "VCRIGHT_estimatedVehicleSituation";
BA_ "Confidence" SG_ 899 VCRIGHT_thsSolarLoadInfrared 0;
BA_ "GenSigSNA" SG_ 899 VCRIGHT_thsSolarLoadInfrared "1023";
BA_ "Confidence" SG_ 899 VCRIGHT_thsSolarLoadVisible 0;
BA_ "GenSigSNA" SG_ 899 VCRIGHT_thsSolarLoadVisible "1023";
BA_ "Confidence" SG_ 899 VCRIGHT_estimatedThsSolarLoad 0;
BA_ "GenSigSNA" SG_ 899 VCRIGHT_estimatedThsSolarLoad "1023";
BA_ "Confidence" SG_ 899 VCRIGHT_hvacFastLoggingEnabled 0;
BA_ "Confidence" SG_ 1545 VCRIGHT_udsResponseData_H 1;
BA_ "Confidence" SG_ 1545 VCRIGHT_udsResponseData_L 1;
BA_ "Confidence" SG_ 1059 VCRIGHT_nmGoingToSleep 0;
BA_ "Confidence" SG_ 1059 VCRIGHT_nmWakeUpBus 0;
BA_ "Confidence" SG_ 1059 VCRIGHT_nmKeepAwakeReason 0;
BA_ "GenSigSNA" SG_ 1059 VCRIGHT_nmKeepAwakeReason "0";
BA_ "Confidence" SG_ 1059 VCRIGHT_nmWakeUpReason 0;
BA_ "Confidence" SG_ 1059 VCRIGHT_nmDebugWakeUp 0;
BA_ "Confidence" SG_ 1059 VCRIGHT_nmEthKeepAwakeReason 0;
BA_ "GenSigSNA" SG_ 1059 VCRIGHT_nmEthKeepAwakeReason "0";
BA_ "Confidence" SG_ 1059 VCRIGHT_nmChKeepAwakeReason 0;
BA_ "GenSigSNA" SG_ 1059 VCRIGHT_nmChKeepAwakeReason "0";
BA_ "Confidence" SG_ 707 VCRIGHT_windowStatusIndex 1;
BA_ "Confidence" SG_ 707 VCRIGHT_windowStateRF 0;
BA_ "Confidence" SG_ 707 VCRIGHT_windowTrimClearMoveReque 0;
BA_ "SystemSignalLongSymbol" SG_ 707 VCRIGHT_windowTrimClearMoveReque "VCRIGHT_windowTrimClearMoveRequest";
BA_ "Confidence" SG_ 707 VCRIGHT_windowDutyRF 0;
BA_ "Confidence" SG_ 707 VCRIGHT_windowTrimClearActiveReq 0;
BA_ "GenSigSNA" SG_ 707 VCRIGHT_windowTrimClearActiveReq "0";
BA_ "SystemSignalLongSymbol" SG_ 707 VCRIGHT_windowTrimClearActiveReq "VCRIGHT_windowTrimClearActiveRequest";
BA_ "Confidence" SG_ 707 VCRIGHT_windowCurrentRF 0;
BA_ "Confidence" SG_ 707 VCRIGHT_windowPositionRF 0;
BA_ "GenSigSNA" SG_ 707 VCRIGHT_windowPositionRF "1";
BA_ "Confidence" SG_ 707 VCRIGHT_windowCalibratedRF 0;
BA_ "Confidence" SG_ 707 VCRIGHT_windowStateRR 0;
BA_ "Confidence" SG_ 707 VCRIGHT_windowDutyRR 0;
BA_ "Confidence" SG_ 707 VCRIGHT_windowCurrentRR 0;
BA_ "Confidence" SG_ 707 VCRIGHT_windowPositionRR 0;
BA_ "Confidence" SG_ 707 VCRIGHT_windowCalibratedRR 0;
BA_ "Confidence" SG_ 707 VCRIGHT_windowThermalTCRF 0;
BA_ "Confidence" SG_ 707 VCRIGHT_windowThermalModeRF 0;
BA_ "GenSigSNA" SG_ 707 VCRIGHT_windowThermalModeRF "0";
BA_ "Confidence" SG_ 707 VCRIGHT_windowStopReasonRF 0;
BA_ "Confidence" SG_ 707 VCRIGHT_windowStopReqReasonRF 0;
BA_ "Confidence" SG_ 707 VCRIGHT_windowThermalTCRR 0;
BA_ "Confidence" SG_ 707 VCRIGHT_windowThermalModeRR 0;
BA_ "GenSigSNA" SG_ 707 VCRIGHT_windowThermalModeRR "0";
BA_ "Confidence" SG_ 707 VCRIGHT_windowStopReasonRR 0;
BA_ "Confidence" SG_ 707 VCRIGHT_windowStopReqReasonRR 0;
BA_ "Confidence" SG_ 707 VCRIGHT_windowControlStateRF 0;
BA_ "Confidence" SG_ 707 VCRIGHT_windowCtrlUnavailableRF 0;
BA_ "Confidence" SG_ 707 VCRIGHT_windowControlStateRR 0;
BA_ "Confidence" SG_ 707 VCRIGHT_windowCtrlUnavailableRR 0;
BA_ "Confidence" SG_ 707 VCRIGHT_windowPositionStateRF 0;
BA_ "Confidence" SG_ 707 VCRIGHT_windowPositionStateRR 0;
BA_ "Confidence" SG_ 707 VCRIGHT_windowVehGearStateRF 0;
BA_ "GenSigSNA" SG_ 707 VCRIGHT_windowVehGearStateRF "0";
BA_ "Confidence" SG_ 707 VCRIGHT_windowVehGearStateRR 0;
BA_ "GenSigSNA" SG_ 707 VCRIGHT_windowVehGearStateRR "0";
BA_ "Confidence" SG_ 707 VCRIGHT_windowSpeedTableStatusRF 0;
BA_ "GenSigSNA" SG_ 707 VCRIGHT_windowSpeedTableStatusRF "0";
BA_ "Confidence" SG_ 707 VCRIGHT_windowSpeedTableStatusRR 0;
BA_ "GenSigSNA" SG_ 707 VCRIGHT_windowSpeedTableStatusRR "0";
BA_ "Confidence" SG_ 969 VCSEC_BLEEndpointInfoIndex 1;
BA_ "Confidence" SG_ 969 VCSEC_BLECENTERComponentID 0;
BA_ "Confidence" SG_ 969 VCSEC_BLECENTERPcbaID 0;
BA_ "Confidence" SG_ 969 VCSEC_BLECENTERAssemblyID 0;
BA_ "Confidence" SG_ 969 VCSEC_BLECENTERUsageID 0;
BA_ "Confidence" SG_ 969 VCSEC_BLECENTERCrc 0;
BA_ "Confidence" SG_ 969 VCSEC_BLELEFTAppGitHashByte 0;
BA_ "Confidence" SG_ 969 VCSEC_BLELEFTComponentID 0;
BA_ "Confidence" SG_ 969 VCSEC_BLELEFTPcbaID 0;
BA_ "Confidence" SG_ 969 VCSEC_BLELEFTAssemblyID 0;
BA_ "Confidence" SG_ 969 VCSEC_BLELEFTUsageID 0;
BA_ "Confidence" SG_ 969 VCSEC_BLELEFTCrc 0;
BA_ "Confidence" SG_ 969 VCSEC_BLERIGHTAppGitHashByte 0;
BA_ "Confidence" SG_ 969 VCSEC_BLERIGHTComponentID 0;
BA_ "Confidence" SG_ 969 VCSEC_BLERIGHTPcbaID 0;
BA_ "Confidence" SG_ 969 VCSEC_BLERIGHTAssemblyID 0;
BA_ "Confidence" SG_ 969 VCSEC_BLERIGHTUsageID 0;
BA_ "Confidence" SG_ 969 VCSEC_BLERIGHTCrc 0;
BA_ "Confidence" SG_ 969 VCSEC_BLEREARAppGitHashByte 0;
BA_ "Confidence" SG_ 969 VCSEC_BLEREARComponentID 0;
BA_ "Confidence" SG_ 969 VCSEC_BLEREARPcbaID 0;
BA_ "Confidence" SG_ 969 VCSEC_BLEREARAssemblyID 0;
BA_ "Confidence" SG_ 969 VCSEC_BLEREARUsageID 0;
BA_ "Confidence" SG_ 969 VCSEC_BLEREARCrc 0;
BA_ "Confidence" SG_ 969 VCSEC_UWBRightCrc 0;
BA_ "Confidence" SG_ 969 VCSEC_UWBRightRadioConfigState 0;
BA_ "Confidence" SG_ 969 VCSEC_UWBRightUpdateStatus 0;
BA_ "GenSigSNA" SG_ 969 VCSEC_UWBRightUpdateStatus "7";
BA_ "Confidence" SG_ 969 VCSEC_UWBRightRetryLimitReached 0;
BA_ "Confidence" SG_ 969 VCSEC_UWBRightDspVersion 0;
BA_ "Confidence" SG_ 969 VCSEC_UWBRightComponentID 0;
BA_ "Confidence" SG_ 969 VCSEC_UWBRightPcbaID 0;
BA_ "Confidence" SG_ 969 VCSEC_UWBRightAssemblyID 0;
BA_ "Confidence" SG_ 969 VCSEC_UWBRightUsageID 0;
BA_ "Confidence" SG_ 969 VCSEC_UWBRearRightCrc 0;
BA_ "Confidence" SG_ 969 VCSEC_UWBRearRightRadioConfigSta 0;
BA_ "SystemSignalLongSymbol" SG_ 969 VCSEC_UWBRearRightRadioConfigSta "VCSEC_UWBRearRightRadioConfigState";
BA_ "Confidence" SG_ 969 VCSEC_UWBRearRightUpdateStatus 0;
BA_ "GenSigSNA" SG_ 969 VCSEC_UWBRearRightUpdateStatus "7";
BA_ "Confidence" SG_ 969 VCSEC_UWBRearRightRetryLimitReac 0;
BA_ "SystemSignalLongSymbol" SG_ 969 VCSEC_UWBRearRightRetryLimitReac "VCSEC_UWBRearRightRetryLimitReached";
BA_ "Confidence" SG_ 969 VCSEC_UWBRearRightDspVersion 0;
BA_ "Confidence" SG_ 969 VCSEC_UWBRearRightComponentID 0;
BA_ "Confidence" SG_ 969 VCSEC_UWBRearRightPcbaID 0;
BA_ "Confidence" SG_ 969 VCSEC_UWBRearRightAssemblyID 0;
BA_ "Confidence" SG_ 969 VCSEC_UWBRearRightUsageID 0;
BA_ "Confidence" SG_ 969 VCSEC_UWBRearLeftCrc 0;
BA_ "Confidence" SG_ 969 VCSEC_UWBRearLeftRadioConfigStat 0;
BA_ "SystemSignalLongSymbol" SG_ 969 VCSEC_UWBRearLeftRadioConfigStat "VCSEC_UWBRearLeftRadioConfigState";
BA_ "Confidence" SG_ 969 VCSEC_UWBRearLeftUpdateStatus 0;
BA_ "GenSigSNA" SG_ 969 VCSEC_UWBRearLeftUpdateStatus "7";
BA_ "Confidence" SG_ 969 VCSEC_UWBRearLeftRetryLimitReach 0;
BA_ "SystemSignalLongSymbol" SG_ 969 VCSEC_UWBRearLeftRetryLimitReach "VCSEC_UWBRearLeftRetryLimitReached";
BA_ "Confidence" SG_ 969 VCSEC_UWBRearLeftDspVersion 0;
BA_ "Confidence" SG_ 969 VCSEC_UWBRearLeftComponentID 0;
BA_ "Confidence" SG_ 969 VCSEC_UWBRearLeftPcbaID 0;
BA_ "Confidence" SG_ 969 VCSEC_UWBRearLeftAssemblyID 0;
BA_ "Confidence" SG_ 969 VCSEC_UWBRearLeftUsageID 0;
BA_ "Confidence" SG_ 969 VCSEC_UWBRearCrc 0;
BA_ "Confidence" SG_ 969 VCSEC_UWBRearRadioConfigState 0;
BA_ "Confidence" SG_ 969 VCSEC_UWBRearUpdateStatus 0;
BA_ "GenSigSNA" SG_ 969 VCSEC_UWBRearUpdateStatus "7";
BA_ "Confidence" SG_ 969 VCSEC_UWBRearRetryLimitReached 0;
BA_ "Confidence" SG_ 969 VCSEC_UWBRearDspVersion 0;
BA_ "Confidence" SG_ 969 VCSEC_UWBRearComponentID 0;
BA_ "Confidence" SG_ 969 VCSEC_UWBRearPcbaID 0;
BA_ "Confidence" SG_ 969 VCSEC_UWBRearAssemblyID 0;
BA_ "Confidence" SG_ 969 VCSEC_UWBRearUsageID 0;
BA_ "Confidence" SG_ 969 VCSEC_UWBLeftCrc 0;
BA_ "Confidence" SG_ 969 VCSEC_UWBLeftRadioConfigState 0;
BA_ "Confidence" SG_ 969 VCSEC_UWBLeftUpdateStatus 0;
BA_ "GenSigSNA" SG_ 969 VCSEC_UWBLeftUpdateStatus "7";
BA_ "Confidence" SG_ 969 VCSEC_UWBLeftRetryLimitReached 0;
BA_ "Confidence" SG_ 969 VCSEC_UWBLeftDspVersion 0;
BA_ "Confidence" SG_ 969 VCSEC_UWBLeftComponentID 0;
BA_ "Confidence" SG_ 969 VCSEC_UWBLeftPcbaID 0;
BA_ "Confidence" SG_ 969 VCSEC_UWBLeftAssemblyID 0;
BA_ "Confidence" SG_ 969 VCSEC_UWBLeftUsageID 0;
BA_ "Confidence" SG_ 969 VCSEC_UWBCenterCrc 0;
BA_ "Confidence" SG_ 969 VCSEC_UWBCenterRadioConfigState 0;
BA_ "Confidence" SG_ 969 VCSEC_UWBCenterUpdateStatus 0;
BA_ "GenSigSNA" SG_ 969 VCSEC_UWBCenterUpdateStatus "7";
BA_ "Confidence" SG_ 969 VCSEC_UWBCenterRetryLimitReached 0;
BA_ "Confidence" SG_ 969 VCSEC_UWBCenterDspVersion 0;
BA_ "Confidence" SG_ 969 VCSEC_UWBCenterComponentID 0;
BA_ "Confidence" SG_ 969 VCSEC_UWBCenterPcbaID 0;
BA_ "Confidence" SG_ 969 VCSEC_UWBCenterAssemblyID 0;
BA_ "Confidence" SG_ 969 VCSEC_UWBCenterUsageID 0;
BA_ "Confidence" SG_ 969 VCSEC_BLERIGHTREARCrc 0;
BA_ "Confidence" SG_ 969 VCSEC_BLERIGHTREARComponentID 0;
BA_ "Confidence" SG_ 969 VCSEC_BLERIGHTREARPcbaID 0;
BA_ "Confidence" SG_ 969 VCSEC_BLERIGHTREARAssemblyID 0;
BA_ "Confidence" SG_ 969 VCSEC_BLERIGHTREARUsageID 0;
BA_ "Confidence" SG_ 969 VCSEC_BLENFCCRADLECrc 0;
BA_ "Confidence" SG_ 969 VCSEC_BLENFCCRADLEComponentID 0;
BA_ "Confidence" SG_ 969 VCSEC_BLENFCCRADLEPcbaID 0;
BA_ "Confidence" SG_ 969 VCSEC_BLENFCCRADLEAssemblyID 0;
BA_ "Confidence" SG_ 969 VCSEC_BLENFCCRADLEUsageID 0;
BA_ "Confidence" SG_ 969 VCSEC_BLELEFTREARCrc 0;
BA_ "Confidence" SG_ 969 VCSEC_BLELEFTREARComponentID 0;
BA_ "Confidence" SG_ 969 VCSEC_BLELEFTREARPcbaID 0;
BA_ "Confidence" SG_ 969 VCSEC_BLELEFTREARAssemblyID 0;
BA_ "Confidence" SG_ 969 VCSEC_BLELEFTREARUsageID 0;
BA_ "Confidence" SG_ 607 VCSEC_childSeat0_connectionState 0;
BA_ "Confidence" SG_ 607 VCSEC_childSeat0_taskDisconnecti 0;
BA_ "SystemSignalLongSymbol" SG_ 607 VCSEC_childSeat0_taskDisconnecti "VCSEC_childSeat0_taskDisconnectionReason";
BA_ "Confidence" SG_ 607 VCSEC_childSeat0_state 0;
BA_ "Confidence" SG_ 607 VCSEC_childSeat0_taskErrorCode 0;
BA_ "Confidence" SG_ 607 VCSEC_childSeat0_RSSI 0;
BA_ "GenSigSNA" SG_ 607 VCSEC_childSeat0_RSSI "127";
BA_ "Confidence" SG_ 607 VCSEC_childSeat0_ISOFixStatus 0;
BA_ "Confidence" SG_ 607 VCSEC_childSeat0_buckleStatus 0;
BA_ "Confidence" SG_ 607 VCSEC_childSeat0_occupancyStatus 0;
BA_ "Confidence" SG_ 607 VCSEC_childSeat1_connectionState 0;
BA_ "Confidence" SG_ 607 VCSEC_childSeat1_taskDisconnecti 0;
BA_ "SystemSignalLongSymbol" SG_ 607 VCSEC_childSeat1_taskDisconnecti "VCSEC_childSeat1_taskDisconnectionReason";
BA_ "Confidence" SG_ 607 VCSEC_childSeat1_state 0;
BA_ "Confidence" SG_ 607 VCSEC_childSeat1_taskErrorCode 0;
BA_ "Confidence" SG_ 607 VCSEC_childSeat1_RSSI 0;
BA_ "GenSigSNA" SG_ 607 VCSEC_childSeat1_RSSI "127";
BA_ "Confidence" SG_ 607 VCSEC_childSeat1_ISOFixStatus 0;
BA_ "Confidence" SG_ 607 VCSEC_childSeat1_buckleStatus 0;
BA_ "Confidence" SG_ 607 VCSEC_childSeat1_occupancyStatus 0;
BA_ "Confidence" SG_ 607 VCSEC_childPresenceDetectionWarn 0;
BA_ "SystemSignalLongSymbol" SG_ 607 VCSEC_childPresenceDetectionWarn "VCSEC_childPresenceDetectionWarningActive";
BA_ "Confidence" SG_ 607 VCSEC_childSeatScanStatus 0;
BA_ "Confidence" SG_ 607 VCSEC_childPresenceDetectionStat 0;
BA_ "SystemSignalLongSymbol" SG_ 607 VCSEC_childPresenceDetectionStat "VCSEC_childPresenceDetectionState";
BA_ "Confidence" SG_ 607 VCSEC_childPresenceDetectionSupp 0;
BA_ "SystemSignalLongSymbol" SG_ 607 VCSEC_childPresenceDetectionSupp "VCSEC_childPresenceDetectionSupportType";
BA_ "Confidence" SG_ 607 VCSEC_childPresenceDetectionNoti 0;
BA_ "SystemSignalLongSymbol" SG_ 607 VCSEC_childPresenceDetectionNoti "VCSEC_childPresenceDetectionNotificationEnabled";
BA_ "Confidence" SG_ 857 VCSEC_DeviceStatusIndex 1;
BA_ "Confidence" SG_ 857 VCSEC_Device0AuthResponseTime 0;
BA_ "Confidence" SG_ 857 VCSEC_Device0Impermanent 0;
BA_ "Confidence" SG_ 857 VCSEC_Device0SELockedDown 0;
BA_ "Confidence" SG_ 857 VCSEC_Device0Version 0;
BA_ "Confidence" SG_ 857 VCSEC_Device0WLEntry 0;
BA_ "Confidence" SG_ 857 VCSEC_Device0OSVersion 0;
BA_ "Confidence" SG_ 857 VCSEC_Device0BatteryLevel 0;
BA_ "Confidence" SG_ 857 VCSEC_Device0Formfactor 0;
BA_ "Confidence" SG_ 857 VCSEC_Device0BlacklistStatus 0;
BA_ "Confidence" SG_ 857 VCSEC_Device0Stationary 0;
BA_ "Confidence" SG_ 857 VCSEC_Device0Bonded 0;
BA_ "Confidence" SG_ 857 VCSEC_Device0Role 0;
BA_ "Confidence" SG_ 857 VCSEC_Device0WhitelistActiveTime 0;
BA_ "Confidence" SG_ 857 VCSEC_Device0SHA1 0;
BA_ "Confidence" SG_ 857 VCSEC_Device0Permissions 0;
BA_ "Confidence" SG_ 857 VCSEC_Device0ManufacturerHashBit 0;
BA_ "SystemSignalLongSymbol" SG_ 857 VCSEC_Device0ManufacturerHashBit "VCSEC_Device0ManufacturerHashBits";
BA_ "Confidence" SG_ 857 VCSEC_Device0BuildNumberHashBits 0;
BA_ "Confidence" SG_ 857 VCSEC_Device1AuthResponseTime 0;
BA_ "GenSigSNA" SG_ 857 VCSEC_Device1AuthResponseTime "127";
BA_ "Confidence" SG_ 857 VCSEC_Device1Impermanent 0;
BA_ "Confidence" SG_ 857 VCSEC_Device1SELockedDown 0;
BA_ "Confidence" SG_ 857 VCSEC_Device1Version 0;
BA_ "Confidence" SG_ 857 VCSEC_Device1WLEntry 0;
BA_ "Confidence" SG_ 857 VCSEC_Device1OSVersion 0;
BA_ "Confidence" SG_ 857 VCSEC_Device1BatteryLevel 0;
BA_ "Confidence" SG_ 857 VCSEC_Device1Formfactor 0;
BA_ "Confidence" SG_ 857 VCSEC_Device1BlacklistStatus 0;
BA_ "Confidence" SG_ 857 VCSEC_Device1Stationary 0;
BA_ "Confidence" SG_ 857 VCSEC_Device1Bonded 0;
BA_ "Confidence" SG_ 857 VCSEC_Device1Role 0;
BA_ "Confidence" SG_ 857 VCSEC_Device1WhitelistActiveTime 0;
BA_ "Confidence" SG_ 857 VCSEC_Device1SHA1 0;
BA_ "Confidence" SG_ 857 VCSEC_Device1Permissions 0;
BA_ "Confidence" SG_ 857 VCSEC_Device1ManufacturerHashBit 0;
BA_ "SystemSignalLongSymbol" SG_ 857 VCSEC_Device1ManufacturerHashBit "VCSEC_Device1ManufacturerHashBits";
BA_ "Confidence" SG_ 857 VCSEC_Device1BuildNumberHashBits 0;
BA_ "Confidence" SG_ 857 VCSEC_Device2AuthResponseTime 0;
BA_ "GenSigSNA" SG_ 857 VCSEC_Device2AuthResponseTime "127";
BA_ "Confidence" SG_ 857 VCSEC_Device2Impermanent 0;
BA_ "Confidence" SG_ 857 VCSEC_Device2SELockedDown 0;
BA_ "Confidence" SG_ 857 VCSEC_Device2Version 0;
BA_ "Confidence" SG_ 857 VCSEC_Device2WLEntry 0;
BA_ "Confidence" SG_ 857 VCSEC_Device2OSVersion 0;
BA_ "Confidence" SG_ 857 VCSEC_Device2BatteryLevel 0;
BA_ "Confidence" SG_ 857 VCSEC_Device2Formfactor 0;
BA_ "Confidence" SG_ 857 VCSEC_Device2BlacklistStatus 0;
BA_ "Confidence" SG_ 857 VCSEC_Device2Stationary 0;
BA_ "Confidence" SG_ 857 VCSEC_Device2Bonded 0;
BA_ "Confidence" SG_ 857 VCSEC_Device2Role 0;
BA_ "Confidence" SG_ 857 VCSEC_Device2WhitelistActiveTime 0;
BA_ "Confidence" SG_ 857 VCSEC_Device2SHA1 0;
BA_ "Confidence" SG_ 857 VCSEC_Device2Permissions 0;
BA_ "Confidence" SG_ 857 VCSEC_Device2ManufacturerHashBit 0;
BA_ "SystemSignalLongSymbol" SG_ 857 VCSEC_Device2ManufacturerHashBit "VCSEC_Device2ManufacturerHashBits";
BA_ "Confidence" SG_ 857 VCSEC_Device2BuildNumberHashBits 0;
BA_ "Confidence" SG_ 857 VCSEC_Device3AuthResponseTime 0;
BA_ "GenSigSNA" SG_ 857 VCSEC_Device3AuthResponseTime "127";
BA_ "Confidence" SG_ 857 VCSEC_Device3Impermanent 0;
BA_ "Confidence" SG_ 857 VCSEC_Device3SELockedDown 0;
BA_ "Confidence" SG_ 857 VCSEC_Device3Version 0;
BA_ "Confidence" SG_ 857 VCSEC_Device3WLEntry 0;
BA_ "Confidence" SG_ 857 VCSEC_Device3OSVersion 0;
BA_ "Confidence" SG_ 857 VCSEC_Device3BatteryLevel 0;
BA_ "Confidence" SG_ 857 VCSEC_Device3Formfactor 0;
BA_ "Confidence" SG_ 857 VCSEC_Device3BlacklistStatus 0;
BA_ "Confidence" SG_ 857 VCSEC_Device3Stationary 0;
BA_ "Confidence" SG_ 857 VCSEC_Device3Bonded 0;
BA_ "Confidence" SG_ 857 VCSEC_Device3Role 0;
BA_ "Confidence" SG_ 857 VCSEC_Device3WhitelistActiveTime 0;
BA_ "Confidence" SG_ 857 VCSEC_Device3SHA1 0;
BA_ "Confidence" SG_ 857 VCSEC_Device3Permissions 0;
BA_ "Confidence" SG_ 857 VCSEC_Device3ManufacturerHashBit 0;
BA_ "SystemSignalLongSymbol" SG_ 857 VCSEC_Device3ManufacturerHashBit "VCSEC_Device3ManufacturerHashBits";
BA_ "Confidence" SG_ 857 VCSEC_Device3BuildNumberHashBits 0;
BA_ "Confidence" SG_ 857 VCSEC_Device4AuthResponseTime 0;
BA_ "GenSigSNA" SG_ 857 VCSEC_Device4AuthResponseTime "127";
BA_ "Confidence" SG_ 857 VCSEC_Device4Impermanent 0;
BA_ "Confidence" SG_ 857 VCSEC_Device4SELockedDown 0;
BA_ "Confidence" SG_ 857 VCSEC_Device4Version 0;
BA_ "Confidence" SG_ 857 VCSEC_Device4WLEntry 0;
BA_ "Confidence" SG_ 857 VCSEC_Device4OSVersion 0;
BA_ "Confidence" SG_ 857 VCSEC_Device4BatteryLevel 0;
BA_ "Confidence" SG_ 857 VCSEC_Device4Formfactor 0;
BA_ "Confidence" SG_ 857 VCSEC_Device4BlacklistStatus 0;
BA_ "Confidence" SG_ 857 VCSEC_Device4Stationary 0;
BA_ "Confidence" SG_ 857 VCSEC_Device4Bonded 0;
BA_ "Confidence" SG_ 857 VCSEC_Device4Role 0;
BA_ "Confidence" SG_ 857 VCSEC_Device4WhitelistActiveTime 0;
BA_ "Confidence" SG_ 857 VCSEC_Device4SHA1 0;
BA_ "Confidence" SG_ 857 VCSEC_Device4Permissions 0;
BA_ "Confidence" SG_ 857 VCSEC_Device4ManufacturerHashBit 0;
BA_ "SystemSignalLongSymbol" SG_ 857 VCSEC_Device4ManufacturerHashBit "VCSEC_Device4ManufacturerHashBits";
BA_ "Confidence" SG_ 857 VCSEC_Device4BuildNumberHashBits 0;
BA_ "Confidence" SG_ 857 VCSEC_Device5AuthResponseTime 0;
BA_ "GenSigSNA" SG_ 857 VCSEC_Device5AuthResponseTime "127";
BA_ "Confidence" SG_ 857 VCSEC_Device5Impermanent 0;
BA_ "Confidence" SG_ 857 VCSEC_Device5SELockedDown 0;
BA_ "Confidence" SG_ 857 VCSEC_Device5Version 0;
BA_ "Confidence" SG_ 857 VCSEC_Device5WLEntry 0;
BA_ "Confidence" SG_ 857 VCSEC_Device5OSVersion 0;
BA_ "Confidence" SG_ 857 VCSEC_Device5BatteryLevel 0;
BA_ "Confidence" SG_ 857 VCSEC_Device5Formfactor 0;
BA_ "Confidence" SG_ 857 VCSEC_Device5BlacklistStatus 0;
BA_ "Confidence" SG_ 857 VCSEC_Device5Stationary 0;
BA_ "Confidence" SG_ 857 VCSEC_Device5Bonded 0;
BA_ "Confidence" SG_ 857 VCSEC_Device5Role 0;
BA_ "Confidence" SG_ 857 VCSEC_Device5WhitelistActiveTime 0;
BA_ "Confidence" SG_ 857 VCSEC_Device5SHA1 0;
BA_ "Confidence" SG_ 857 VCSEC_Device5Permissions 0;
BA_ "Confidence" SG_ 857 VCSEC_Device5ManufacturerHashBit 0;
BA_ "SystemSignalLongSymbol" SG_ 857 VCSEC_Device5ManufacturerHashBit "VCSEC_Device5ManufacturerHashBits";
BA_ "Confidence" SG_ 857 VCSEC_Device5BuildNumberHashBits 0;
BA_ "Confidence" SG_ 857 VCSEC_Device6AuthResponseTime 0;
BA_ "GenSigSNA" SG_ 857 VCSEC_Device6AuthResponseTime "127";
BA_ "Confidence" SG_ 857 VCSEC_Device6Impermanent 0;
BA_ "Confidence" SG_ 857 VCSEC_Device6SELockedDown 0;
BA_ "Confidence" SG_ 857 VCSEC_Device6Version 0;
BA_ "Confidence" SG_ 857 VCSEC_Device6WLEntry 0;
BA_ "Confidence" SG_ 857 VCSEC_Device6OSVersion 0;
BA_ "Confidence" SG_ 857 VCSEC_Device6BatteryLevel 0;
BA_ "Confidence" SG_ 857 VCSEC_Device6Formfactor 0;
BA_ "Confidence" SG_ 857 VCSEC_Device6BlacklistStatus 0;
BA_ "Confidence" SG_ 857 VCSEC_Device6Stationary 0;
BA_ "Confidence" SG_ 857 VCSEC_Device6Bonded 0;
BA_ "Confidence" SG_ 857 VCSEC_Device6Role 0;
BA_ "Confidence" SG_ 857 VCSEC_Device6WhitelistActiveTime 0;
BA_ "Confidence" SG_ 857 VCSEC_Device6SHA1 0;
BA_ "Confidence" SG_ 857 VCSEC_Device6Permissions 0;
BA_ "Confidence" SG_ 857 VCSEC_Device6ManufacturerHashBit 0;
BA_ "SystemSignalLongSymbol" SG_ 857 VCSEC_Device6ManufacturerHashBit "VCSEC_Device6ManufacturerHashBits";
BA_ "Confidence" SG_ 857 VCSEC_Device6BuildNumberHashBits 0;
BA_ "Confidence" SG_ 857 VCSEC_Device7AuthResponseTime 0;
BA_ "GenSigSNA" SG_ 857 VCSEC_Device7AuthResponseTime "127";
BA_ "Confidence" SG_ 857 VCSEC_Device7Impermanent 0;
BA_ "Confidence" SG_ 857 VCSEC_Device7SELockedDown 0;
BA_ "Confidence" SG_ 857 VCSEC_Device7Version 0;
BA_ "Confidence" SG_ 857 VCSEC_Device7WLEntry 0;
BA_ "Confidence" SG_ 857 VCSEC_Device7OSVersion 0;
BA_ "Confidence" SG_ 857 VCSEC_Device7BatteryLevel 0;
BA_ "Confidence" SG_ 857 VCSEC_Device7Formfactor 0;
BA_ "Confidence" SG_ 857 VCSEC_Device7BlacklistStatus 0;
BA_ "Confidence" SG_ 857 VCSEC_Device7Stationary 0;
BA_ "Confidence" SG_ 857 VCSEC_Device7Bonded 0;
BA_ "Confidence" SG_ 857 VCSEC_Device7Role 0;
BA_ "Confidence" SG_ 857 VCSEC_Device7WhitelistActiveTime 0;
BA_ "Confidence" SG_ 857 VCSEC_Device7SHA1 0;
BA_ "Confidence" SG_ 857 VCSEC_Device7Permissions 0;
BA_ "Confidence" SG_ 857 VCSEC_Device7ManufacturerHashBit 0;
BA_ "SystemSignalLongSymbol" SG_ 857 VCSEC_Device7ManufacturerHashBit "VCSEC_Device7ManufacturerHashBits";
BA_ "Confidence" SG_ 857 VCSEC_Device7BuildNumberHashBits 0;
BA_ "Confidence" SG_ 857 VCSEC_Device8AuthResponseTime 0;
BA_ "GenSigSNA" SG_ 857 VCSEC_Device8AuthResponseTime "127";
BA_ "Confidence" SG_ 857 VCSEC_Device8Impermanent 0;
BA_ "Confidence" SG_ 857 VCSEC_Device8SELockedDown 0;
BA_ "Confidence" SG_ 857 VCSEC_Device8Version 0;
BA_ "Confidence" SG_ 857 VCSEC_Device8WLEntry 0;
BA_ "Confidence" SG_ 857 VCSEC_Device8OSVersion 0;
BA_ "Confidence" SG_ 857 VCSEC_Device8BatteryLevel 0;
BA_ "Confidence" SG_ 857 VCSEC_Device8Formfactor 0;
BA_ "Confidence" SG_ 857 VCSEC_Device8BlacklistStatus 0;
BA_ "Confidence" SG_ 857 VCSEC_Device8Stationary 0;
BA_ "Confidence" SG_ 857 VCSEC_Device8Bonded 0;
BA_ "Confidence" SG_ 857 VCSEC_Device8Role 0;
BA_ "Confidence" SG_ 857 VCSEC_Device8WhitelistActiveTime 0;
BA_ "Confidence" SG_ 857 VCSEC_Device8SHA1 0;
BA_ "Confidence" SG_ 857 VCSEC_Device8Permissions 0;
BA_ "Confidence" SG_ 857 VCSEC_Device8ManufacturerHashBit 0;
BA_ "SystemSignalLongSymbol" SG_ 857 VCSEC_Device8ManufacturerHashBit "VCSEC_Device8ManufacturerHashBits";
BA_ "Confidence" SG_ 857 VCSEC_Device8BuildNumberHashBits 0;
BA_ "Confidence" SG_ 857 VCSEC_Device9AuthResponseTime 0;
BA_ "GenSigSNA" SG_ 857 VCSEC_Device9AuthResponseTime "127";
BA_ "Confidence" SG_ 857 VCSEC_Device9Impermanent 0;
BA_ "Confidence" SG_ 857 VCSEC_Device9SELockedDown 0;
BA_ "Confidence" SG_ 857 VCSEC_Device9Version 0;
BA_ "Confidence" SG_ 857 VCSEC_Device9WLEntry 0;
BA_ "Confidence" SG_ 857 VCSEC_Device9OSVersion 0;
BA_ "Confidence" SG_ 857 VCSEC_Device9BatteryLevel 0;
BA_ "Confidence" SG_ 857 VCSEC_Device9Formfactor 0;
BA_ "Confidence" SG_ 857 VCSEC_Device9BlacklistStatus 0;
BA_ "Confidence" SG_ 857 VCSEC_Device9Stationary 0;
BA_ "Confidence" SG_ 857 VCSEC_Device9Bonded 0;
BA_ "Confidence" SG_ 857 VCSEC_Device9Role 0;
BA_ "Confidence" SG_ 857 VCSEC_Device9WhitelistActiveTime 0;
BA_ "Confidence" SG_ 857 VCSEC_Device9SHA1 0;
BA_ "Confidence" SG_ 857 VCSEC_Device9Permissions 0;
BA_ "Confidence" SG_ 857 VCSEC_Device9ManufacturerHashBit 0;
BA_ "SystemSignalLongSymbol" SG_ 857 VCSEC_Device9ManufacturerHashBit "VCSEC_Device9ManufacturerHashBits";
BA_ "Confidence" SG_ 857 VCSEC_Device9BuildNumberHashBits 0;
BA_ "Confidence" SG_ 857 VCSEC_Device10AuthResponseTime 0;
BA_ "GenSigSNA" SG_ 857 VCSEC_Device10AuthResponseTime "127";
BA_ "Confidence" SG_ 857 VCSEC_Device10Impermanent 0;
BA_ "Confidence" SG_ 857 VCSEC_Device10SELockedDown 0;
BA_ "Confidence" SG_ 857 VCSEC_Device10Version 0;
BA_ "Confidence" SG_ 857 VCSEC_Device10WLEntry 0;
BA_ "Confidence" SG_ 857 VCSEC_Device10OSVersion 0;
BA_ "Confidence" SG_ 857 VCSEC_Device10BatteryLevel 0;
BA_ "Confidence" SG_ 857 VCSEC_Device10Formfactor 0;
BA_ "Confidence" SG_ 857 VCSEC_Device10BlacklistStatus 0;
BA_ "Confidence" SG_ 857 VCSEC_Device10Stationary 0;
BA_ "Confidence" SG_ 857 VCSEC_Device10Bonded 0;
BA_ "Confidence" SG_ 857 VCSEC_Device10Role 0;
BA_ "Confidence" SG_ 857 VCSEC_Device10WhitelistActiveTim 0;
BA_ "SystemSignalLongSymbol" SG_ 857 VCSEC_Device10WhitelistActiveTim "VCSEC_Device10WhitelistActiveTime";
BA_ "Confidence" SG_ 857 VCSEC_Device10SHA1 0;
BA_ "Confidence" SG_ 857 VCSEC_Device10Permissions 0;
BA_ "Confidence" SG_ 857 VCSEC_Device10ManufacturerHashBi 0;
BA_ "SystemSignalLongSymbol" SG_ 857 VCSEC_Device10ManufacturerHashBi "VCSEC_Device10ManufacturerHashBits";
BA_ "Confidence" SG_ 857 VCSEC_Device10BuildNumberHashBit 0;
BA_ "SystemSignalLongSymbol" SG_ 857 VCSEC_Device10BuildNumberHashBit "VCSEC_Device10BuildNumberHashBits";
BA_ "Confidence" SG_ 857 VCSEC_Device11AuthResponseTime 0;
BA_ "GenSigSNA" SG_ 857 VCSEC_Device11AuthResponseTime "127";
BA_ "Confidence" SG_ 857 VCSEC_Device11Impermanent 0;
BA_ "Confidence" SG_ 857 VCSEC_Device11SELockedDown 0;
BA_ "Confidence" SG_ 857 VCSEC_Device11Version 0;
BA_ "Confidence" SG_ 857 VCSEC_Device11WLEntry 0;
BA_ "Confidence" SG_ 857 VCSEC_Device11OSVersion 0;
BA_ "Confidence" SG_ 857 VCSEC_Device11BatteryLevel 0;
BA_ "Confidence" SG_ 857 VCSEC_Device11Formfactor 0;
BA_ "Confidence" SG_ 857 VCSEC_Device11BlacklistStatus 0;
BA_ "Confidence" SG_ 857 VCSEC_Device11Stationary 0;
BA_ "Confidence" SG_ 857 VCSEC_Device11Bonded 0;
BA_ "Confidence" SG_ 857 VCSEC_Device11Role 0;
BA_ "Confidence" SG_ 857 VCSEC_Device11WhitelistActiveTim 0;
BA_ "SystemSignalLongSymbol" SG_ 857 VCSEC_Device11WhitelistActiveTim "VCSEC_Device11WhitelistActiveTime";
BA_ "Confidence" SG_ 857 VCSEC_Device11SHA1 0;
BA_ "Confidence" SG_ 857 VCSEC_Device11Permissions 0;
BA_ "Confidence" SG_ 857 VCSEC_Device11ManufacturerHashBi 0;
BA_ "SystemSignalLongSymbol" SG_ 857 VCSEC_Device11ManufacturerHashBi "VCSEC_Device11ManufacturerHashBits";
BA_ "Confidence" SG_ 857 VCSEC_Device11BuildNumberHashBit 0;
BA_ "SystemSignalLongSymbol" SG_ 857 VCSEC_Device11BuildNumberHashBit "VCSEC_Device11BuildNumberHashBits";
BA_ "Confidence" SG_ 857 VCSEC_Device12AuthResponseTime 0;
BA_ "GenSigSNA" SG_ 857 VCSEC_Device12AuthResponseTime "127";
BA_ "Confidence" SG_ 857 VCSEC_Device12Impermanent 0;
BA_ "Confidence" SG_ 857 VCSEC_Device12SELockedDown 0;
BA_ "Confidence" SG_ 857 VCSEC_Device12Version 0;
BA_ "Confidence" SG_ 857 VCSEC_Device12WLEntry 0;
BA_ "Confidence" SG_ 857 VCSEC_Device12OSVersion 0;
BA_ "Confidence" SG_ 857 VCSEC_Device12BatteryLevel 0;
BA_ "Confidence" SG_ 857 VCSEC_Device12Formfactor 0;
BA_ "Confidence" SG_ 857 VCSEC_Device12BlacklistStatus 0;
BA_ "Confidence" SG_ 857 VCSEC_Device12Stationary 0;
BA_ "Confidence" SG_ 857 VCSEC_Device12Bonded 0;
BA_ "Confidence" SG_ 857 VCSEC_Device12Role 0;
BA_ "Confidence" SG_ 857 VCSEC_Device12WhitelistActiveTim 0;
BA_ "SystemSignalLongSymbol" SG_ 857 VCSEC_Device12WhitelistActiveTim "VCSEC_Device12WhitelistActiveTime";
BA_ "Confidence" SG_ 857 VCSEC_Device12SHA1 0;
BA_ "Confidence" SG_ 857 VCSEC_Device12Permissions 0;
BA_ "Confidence" SG_ 857 VCSEC_Device12ManufacturerHashBi 0;
BA_ "SystemSignalLongSymbol" SG_ 857 VCSEC_Device12ManufacturerHashBi "VCSEC_Device12ManufacturerHashBits";
BA_ "Confidence" SG_ 857 VCSEC_Device12BuildNumberHashBit 0;
BA_ "SystemSignalLongSymbol" SG_ 857 VCSEC_Device12BuildNumberHashBit "VCSEC_Device12BuildNumberHashBits";
BA_ "Confidence" SG_ 857 VCSEC_Device13AuthResponseTime 0;
BA_ "GenSigSNA" SG_ 857 VCSEC_Device13AuthResponseTime "127";
BA_ "Confidence" SG_ 857 VCSEC_Device13Impermanent 0;
BA_ "Confidence" SG_ 857 VCSEC_Device13SELockedDown 0;
BA_ "Confidence" SG_ 857 VCSEC_Device13Version 0;
BA_ "Confidence" SG_ 857 VCSEC_Device13WLEntry 0;
BA_ "Confidence" SG_ 857 VCSEC_Device13OSVersion 0;
BA_ "Confidence" SG_ 857 VCSEC_Device13BatteryLevel 0;
BA_ "Confidence" SG_ 857 VCSEC_Device13Formfactor 0;
BA_ "Confidence" SG_ 857 VCSEC_Device13BlacklistStatus 0;
BA_ "Confidence" SG_ 857 VCSEC_Device13Stationary 0;
BA_ "Confidence" SG_ 857 VCSEC_Device13Bonded 0;
BA_ "Confidence" SG_ 857 VCSEC_Device13Role 0;
BA_ "Confidence" SG_ 857 VCSEC_Device13WhitelistActiveTim 0;
BA_ "SystemSignalLongSymbol" SG_ 857 VCSEC_Device13WhitelistActiveTim "VCSEC_Device13WhitelistActiveTime";
BA_ "Confidence" SG_ 857 VCSEC_Device13SHA1 0;
BA_ "Confidence" SG_ 857 VCSEC_Device13Permissions 0;
BA_ "Confidence" SG_ 857 VCSEC_Device13ManufacturerHashBi 0;
BA_ "SystemSignalLongSymbol" SG_ 857 VCSEC_Device13ManufacturerHashBi "VCSEC_Device13ManufacturerHashBits";
BA_ "Confidence" SG_ 857 VCSEC_Device13BuildNumberHashBit 0;
BA_ "SystemSignalLongSymbol" SG_ 857 VCSEC_Device13BuildNumberHashBit "VCSEC_Device13BuildNumberHashBits";
BA_ "Confidence" SG_ 857 VCSEC_Device14AuthResponseTime 0;
BA_ "GenSigSNA" SG_ 857 VCSEC_Device14AuthResponseTime "127";
BA_ "Confidence" SG_ 857 VCSEC_Device14Impermanent 0;
BA_ "Confidence" SG_ 857 VCSEC_Device14SELockedDown 0;
BA_ "Confidence" SG_ 857 VCSEC_Device14Version 0;
BA_ "Confidence" SG_ 857 VCSEC_Device14WLEntry 0;
BA_ "Confidence" SG_ 857 VCSEC_Device14OSVersion 0;
BA_ "Confidence" SG_ 857 VCSEC_Device14BatteryLevel 0;
BA_ "Confidence" SG_ 857 VCSEC_Device14Formfactor 0;
BA_ "Confidence" SG_ 857 VCSEC_Device14BlacklistStatus 0;
BA_ "Confidence" SG_ 857 VCSEC_Device14Stationary 0;
BA_ "Confidence" SG_ 857 VCSEC_Device14Bonded 0;
BA_ "Confidence" SG_ 857 VCSEC_Device14Role 0;
BA_ "Confidence" SG_ 857 VCSEC_Device14WhitelistActiveTim 0;
BA_ "SystemSignalLongSymbol" SG_ 857 VCSEC_Device14WhitelistActiveTim "VCSEC_Device14WhitelistActiveTime";
BA_ "Confidence" SG_ 857 VCSEC_Device14SHA1 0;
BA_ "Confidence" SG_ 857 VCSEC_Device14Permissions 0;
BA_ "Confidence" SG_ 857 VCSEC_Device14ManufacturerHashBi 0;
BA_ "SystemSignalLongSymbol" SG_ 857 VCSEC_Device14ManufacturerHashBi "VCSEC_Device14ManufacturerHashBits";
BA_ "Confidence" SG_ 857 VCSEC_Device14BuildNumberHashBit 0;
BA_ "SystemSignalLongSymbol" SG_ 857 VCSEC_Device14BuildNumberHashBit "VCSEC_Device14BuildNumberHashBits";
BA_ "Confidence" SG_ 857 VCSEC_Device15AuthResponseTime 0;
BA_ "GenSigSNA" SG_ 857 VCSEC_Device15AuthResponseTime "127";
BA_ "Confidence" SG_ 857 VCSEC_Device15Impermanent 0;
BA_ "Confidence" SG_ 857 VCSEC_Device15SELockedDown 0;
BA_ "Confidence" SG_ 857 VCSEC_Device15Version 0;
BA_ "Confidence" SG_ 857 VCSEC_Device15WLEntry 0;
BA_ "Confidence" SG_ 857 VCSEC_Device15OSVersion 0;
BA_ "Confidence" SG_ 857 VCSEC_Device15BatteryLevel 0;
BA_ "Confidence" SG_ 857 VCSEC_Device15Formfactor 0;
BA_ "Confidence" SG_ 857 VCSEC_Device15BlacklistStatus 0;
BA_ "Confidence" SG_ 857 VCSEC_Device15Stationary 0;
BA_ "Confidence" SG_ 857 VCSEC_Device15Bonded 0;
BA_ "Confidence" SG_ 857 VCSEC_Device15Role 0;
BA_ "Confidence" SG_ 857 VCSEC_Device15WhitelistActiveTim 0;
BA_ "SystemSignalLongSymbol" SG_ 857 VCSEC_Device15WhitelistActiveTim "VCSEC_Device15WhitelistActiveTime";
BA_ "Confidence" SG_ 857 VCSEC_Device15SHA1 0;
BA_ "Confidence" SG_ 857 VCSEC_Device15Permissions 0;
BA_ "Confidence" SG_ 857 VCSEC_Device15ManufacturerHashBi 0;
BA_ "SystemSignalLongSymbol" SG_ 857 VCSEC_Device15ManufacturerHashBi "VCSEC_Device15ManufacturerHashBits";
BA_ "Confidence" SG_ 857 VCSEC_Device15BuildNumberHashBit 0;
BA_ "SystemSignalLongSymbol" SG_ 857 VCSEC_Device15BuildNumberHashBit "VCSEC_Device15BuildNumberHashBits";
BA_ "Confidence" SG_ 857 VCSEC_Device16AuthResponseTime 0;
BA_ "GenSigSNA" SG_ 857 VCSEC_Device16AuthResponseTime "127";
BA_ "Confidence" SG_ 857 VCSEC_Device16Impermanent 0;
BA_ "Confidence" SG_ 857 VCSEC_Device16SELockedDown 0;
BA_ "Confidence" SG_ 857 VCSEC_Device16Version 0;
BA_ "Confidence" SG_ 857 VCSEC_Device16WLEntry 0;
BA_ "Confidence" SG_ 857 VCSEC_Device16OSVersion 0;
BA_ "Confidence" SG_ 857 VCSEC_Device16BatteryLevel 0;
BA_ "Confidence" SG_ 857 VCSEC_Device16Formfactor 0;
BA_ "Confidence" SG_ 857 VCSEC_Device16BlacklistStatus 0;
BA_ "Confidence" SG_ 857 VCSEC_Device16Stationary 0;
BA_ "Confidence" SG_ 857 VCSEC_Device16Bonded 0;
BA_ "Confidence" SG_ 857 VCSEC_Device16Role 0;
BA_ "Confidence" SG_ 857 VCSEC_Device16WhitelistActiveTim 0;
BA_ "SystemSignalLongSymbol" SG_ 857 VCSEC_Device16WhitelistActiveTim "VCSEC_Device16WhitelistActiveTime";
BA_ "Confidence" SG_ 857 VCSEC_Device16SHA1 0;
BA_ "Confidence" SG_ 857 VCSEC_Device16Permissions 0;
BA_ "Confidence" SG_ 857 VCSEC_Device16ManufacturerHashBi 0;
BA_ "SystemSignalLongSymbol" SG_ 857 VCSEC_Device16ManufacturerHashBi "VCSEC_Device16ManufacturerHashBits";
BA_ "Confidence" SG_ 857 VCSEC_Device16BuildNumberHashBit 0;
BA_ "SystemSignalLongSymbol" SG_ 857 VCSEC_Device16BuildNumberHashBit "VCSEC_Device16BuildNumberHashBits";
BA_ "Confidence" SG_ 857 VCSEC_Device17AuthResponseTime 0;
BA_ "GenSigSNA" SG_ 857 VCSEC_Device17AuthResponseTime "127";
BA_ "Confidence" SG_ 857 VCSEC_Device17Impermanent 0;
BA_ "Confidence" SG_ 857 VCSEC_Device17SELockedDown 0;
BA_ "Confidence" SG_ 857 VCSEC_Device17Version 0;
BA_ "Confidence" SG_ 857 VCSEC_Device17WLEntry 0;
BA_ "Confidence" SG_ 857 VCSEC_Device17OSVersion 0;
BA_ "Confidence" SG_ 857 VCSEC_Device17BatteryLevel 0;
BA_ "Confidence" SG_ 857 VCSEC_Device17Formfactor 0;
BA_ "Confidence" SG_ 857 VCSEC_Device17BlacklistStatus 0;
BA_ "Confidence" SG_ 857 VCSEC_Device17Stationary 0;
BA_ "Confidence" SG_ 857 VCSEC_Device17Bonded 0;
BA_ "Confidence" SG_ 857 VCSEC_Device17Role 0;
BA_ "Confidence" SG_ 857 VCSEC_Device17WhitelistActiveTim 0;
BA_ "SystemSignalLongSymbol" SG_ 857 VCSEC_Device17WhitelistActiveTim "VCSEC_Device17WhitelistActiveTime";
BA_ "Confidence" SG_ 857 VCSEC_Device17SHA1 0;
BA_ "Confidence" SG_ 857 VCSEC_Device17Permissions 0;
BA_ "Confidence" SG_ 857 VCSEC_Device17ManufacturerHashBi 0;
BA_ "SystemSignalLongSymbol" SG_ 857 VCSEC_Device17ManufacturerHashBi "VCSEC_Device17ManufacturerHashBits";
BA_ "Confidence" SG_ 857 VCSEC_Device17BuildNumberHashBit 0;
BA_ "SystemSignalLongSymbol" SG_ 857 VCSEC_Device17BuildNumberHashBit "VCSEC_Device17BuildNumberHashBits";
BA_ "Confidence" SG_ 857 VCSEC_Device18AuthResponseTime 0;
BA_ "GenSigSNA" SG_ 857 VCSEC_Device18AuthResponseTime "127";
BA_ "Confidence" SG_ 857 VCSEC_Device18Impermanent 0;
BA_ "Confidence" SG_ 857 VCSEC_Device18SELockedDown 0;
BA_ "Confidence" SG_ 857 VCSEC_Device18Version 0;
BA_ "Confidence" SG_ 857 VCSEC_Device18WLEntry 0;
BA_ "Confidence" SG_ 857 VCSEC_Device18OSVersion 0;
BA_ "Confidence" SG_ 857 VCSEC_Device18BatteryLevel 0;
BA_ "Confidence" SG_ 857 VCSEC_Device18Formfactor 0;
BA_ "Confidence" SG_ 857 VCSEC_Device18BlacklistStatus 0;
BA_ "Confidence" SG_ 857 VCSEC_Device18Stationary 0;
BA_ "Confidence" SG_ 857 VCSEC_Device18Bonded 0;
BA_ "Confidence" SG_ 857 VCSEC_Device18Role 0;
BA_ "Confidence" SG_ 857 VCSEC_Device18WhitelistActiveTim 0;
BA_ "SystemSignalLongSymbol" SG_ 857 VCSEC_Device18WhitelistActiveTim "VCSEC_Device18WhitelistActiveTime";
BA_ "Confidence" SG_ 857 VCSEC_Device18SHA1 0;
BA_ "Confidence" SG_ 857 VCSEC_Device18Permissions 0;
BA_ "Confidence" SG_ 857 VCSEC_Device18ManufacturerHashBi 0;
BA_ "SystemSignalLongSymbol" SG_ 857 VCSEC_Device18ManufacturerHashBi "VCSEC_Device18ManufacturerHashBits";
BA_ "Confidence" SG_ 857 VCSEC_Device18BuildNumberHashBit 0;
BA_ "SystemSignalLongSymbol" SG_ 857 VCSEC_Device18BuildNumberHashBit "VCSEC_Device18BuildNumberHashBits";
BA_ "Confidence" SG_ 857 VCSEC_Device19AuthResponseTime 0;
BA_ "GenSigSNA" SG_ 857 VCSEC_Device19AuthResponseTime "127";
BA_ "Confidence" SG_ 857 VCSEC_Device19Impermanent 0;
BA_ "Confidence" SG_ 857 VCSEC_Device19SELockedDown 0;
BA_ "Confidence" SG_ 857 VCSEC_Device19Version 0;
BA_ "Confidence" SG_ 857 VCSEC_Device19WLEntry 0;
BA_ "Confidence" SG_ 857 VCSEC_Device19OSVersion 0;
BA_ "Confidence" SG_ 857 VCSEC_Device19BatteryLevel 0;
BA_ "Confidence" SG_ 857 VCSEC_Device19Formfactor 0;
BA_ "Confidence" SG_ 857 VCSEC_Device19BlacklistStatus 0;
BA_ "Confidence" SG_ 857 VCSEC_Device19Stationary 0;
BA_ "Confidence" SG_ 857 VCSEC_Device19Bonded 0;
BA_ "Confidence" SG_ 857 VCSEC_Device19Role 0;
BA_ "Confidence" SG_ 857 VCSEC_Device19WhitelistActiveTim 0;
BA_ "SystemSignalLongSymbol" SG_ 857 VCSEC_Device19WhitelistActiveTim "VCSEC_Device19WhitelistActiveTime";
BA_ "Confidence" SG_ 857 VCSEC_Device19SHA1 0;
BA_ "Confidence" SG_ 857 VCSEC_Device19Permissions 0;
BA_ "Confidence" SG_ 857 VCSEC_Device19ManufacturerHashBi 0;
BA_ "SystemSignalLongSymbol" SG_ 857 VCSEC_Device19ManufacturerHashBi "VCSEC_Device19ManufacturerHashBits";
BA_ "Confidence" SG_ 857 VCSEC_Device19BuildNumberHashBit 0;
BA_ "SystemSignalLongSymbol" SG_ 857 VCSEC_Device19BuildNumberHashBit "VCSEC_Device19BuildNumberHashBits";
BA_ "Confidence" SG_ 953 VCSEC_IsoTpPipeODIN0 1;
BA_ "Confidence" SG_ 953 VCSEC_IsoTpPipeODIN1 1;
BA_ "Confidence" SG_ 953 VCSEC_IsoTpPipeODIN2 1;
BA_ "Confidence" SG_ 953 VCSEC_IsoTpPipeODIN3 1;
BA_ "Confidence" SG_ 953 VCSEC_IsoTpPipeODIN4 1;
BA_ "Confidence" SG_ 953 VCSEC_IsoTpPipeODIN5 1;
BA_ "Confidence" SG_ 953 VCSEC_IsoTpPipeODIN6 1;
BA_ "Confidence" SG_ 953 VCSEC_IsoTpPipeODIN7 1;
BA_ "Confidence" SG_ 473 VCSEC_IsoTpUDPPipeUI0 0;
BA_ "Confidence" SG_ 473 VCSEC_IsoTpUDPPipeUI1 0;
BA_ "Confidence" SG_ 473 VCSEC_IsoTpUDPPipeUI2 0;
BA_ "Confidence" SG_ 473 VCSEC_IsoTpUDPPipeUI3 0;
BA_ "Confidence" SG_ 473 VCSEC_IsoTpUDPPipeUI4 0;
BA_ "Confidence" SG_ 473 VCSEC_IsoTpUDPPipeUI5 0;
BA_ "Confidence" SG_ 473 VCSEC_IsoTpUDPPipeUI6 0;
BA_ "Confidence" SG_ 473 VCSEC_IsoTpUDPPipeUI7 0;
BA_ "Confidence" SG_ 1066 VCSEC_TPMSSensorState0 0;
BA_ "Confidence" SG_ 1066 VCSEC_TPMSRSSI0 0;
BA_ "Confidence" SG_ 1066 VCSEC_TPMSConnectionTypeCurrent0 0;
BA_ "Confidence" SG_ 1066 VCSEC_TPMSConnectionTypeDesired0 0;
BA_ "Confidence" SG_ 1066 VCSEC_TPMSSensorState1 0;
BA_ "Confidence" SG_ 1066 VCSEC_TPMSRSSI1 0;
BA_ "Confidence" SG_ 1066 VCSEC_TPMSConnectionTypeCurrent1 0;
BA_ "Confidence" SG_ 1066 VCSEC_TPMSConnectionTypeDesired1 0;
BA_ "Confidence" SG_ 1066 VCSEC_TPMSSensorState2 0;
BA_ "Confidence" SG_ 1066 VCSEC_TPMSRSSI2 0;
BA_ "Confidence" SG_ 1066 VCSEC_TPMSConnectionTypeCurrent2 0;
BA_ "Confidence" SG_ 1066 VCSEC_TPMSConnectionTypeDesired2 0;
BA_ "Confidence" SG_ 1066 VCSEC_TPMSSensorState3 0;
BA_ "Confidence" SG_ 1066 VCSEC_TPMSRSSI3 0;
BA_ "Confidence" SG_ 1066 VCSEC_TPMSConnectionTypeCurrent3 0;
BA_ "Confidence" SG_ 1066 VCSEC_TPMSConnectionTypeDesired3 0;
BA_ "Confidence" SG_ 1066 VCSEC_TPMSSensorPresence0 0;
BA_ "Confidence" SG_ 1066 VCSEC_TPMSSensorPresence1 0;
BA_ "Confidence" SG_ 1066 VCSEC_TPMSSensorPresence2 0;
BA_ "Confidence" SG_ 1066 VCSEC_TPMSSensorPresence3 0;
VAL_ 963 VCRIGHT_switchStatusIndex 1 "1" 0 "0" ;
VAL_ 963 VCRIGHT_frontOccupancySwitch 3 "SWITCH_FAULT" 2 "SWITCH_ON" 1 "SWITCH_OFF" 0 "SWITCH_SNA" ;
VAL_ 963 VCRIGHT_frontBuckleSwitch 3 "SWITCH_FAULT" 2 "SWITCH_ON" 1 "SWITCH_OFF" 0 "SWITCH_SNA" ;
VAL_ 963 VCRIGHT_rearCenterBuckleSwitch 3 "SWITCH_FAULT" 2 "SWITCH_ON" 1 "SWITCH_OFF" 0 "SWITCH_SNA" ;
VAL_ 963 VCRIGHT_rearRightBuckleSwitch 3 "SWITCH_FAULT" 2 "SWITCH_ON" 1 "SWITCH_OFF" 0 "SWITCH_SNA" ;
VAL_ 963 VCRIGHT_frontSeatTrackBack 3 "SWITCH_FAULT" 2 "SWITCH_ON" 1 "SWITCH_OFF" 0 "SWITCH_SNA" ;
VAL_ 963 VCRIGHT_frontSeatTrackForward 3 "SWITCH_FAULT" 2 "SWITCH_ON" 1 "SWITCH_OFF" 0 "SWITCH_SNA" ;
VAL_ 963 VCRIGHT_frontSeatTiltDown 3 "SWITCH_FAULT" 2 "SWITCH_ON" 1 "SWITCH_OFF" 0 "SWITCH_SNA" ;
VAL_ 963 VCRIGHT_frontSeatTiltUp 3 "SWITCH_FAULT" 2 "SWITCH_ON" 1 "SWITCH_OFF" 0 "SWITCH_SNA" ;
VAL_ 963 VCRIGHT_frontSeatLiftDown 3 "SWITCH_FAULT" 2 "SWITCH_ON" 1 "SWITCH_OFF" 0 "SWITCH_SNA" ;
VAL_ 963 VCRIGHT_frontSeatLiftUp 3 "SWITCH_FAULT" 2 "SWITCH_ON" 1 "SWITCH_OFF" 0 "SWITCH_SNA" ;
VAL_ 963 VCRIGHT_frontSeatBackrestBack 3 "SWITCH_FAULT" 2 "SWITCH_ON" 1 "SWITCH_OFF" 0 "SWITCH_SNA" ;
VAL_ 963 VCRIGHT_frontSeatBackrestForward 3 "SWITCH_FAULT" 2 "SWITCH_ON" 1 "SWITCH_OFF" 0 "SWITCH_SNA" ;
VAL_ 963 VCRIGHT_frontSeatLumbarDown 3 "SWITCH_FAULT" 2 "SWITCH_ON" 1 "SWITCH_OFF" 0 "SWITCH_SNA" ;
VAL_ 963 VCRIGHT_frontSeatLumbarUp 3 "SWITCH_FAULT" 2 "SWITCH_ON" 1 "SWITCH_OFF" 0 "SWITCH_SNA" ;
VAL_ 963 VCRIGHT_frontSeatLumbarIn 3 "SWITCH_FAULT" 2 "SWITCH_ON" 1 "SWITCH_OFF" 0 "SWITCH_SNA" ;
VAL_ 963 VCRIGHT_frontSeatResistiveOccupa 3 "SWITCH_FAULT" 2 "SWITCH_ON" 1 "SWITCH_OFF" 0 "SWITCH_SNA" ;
VAL_ 963 VCRIGHT_2RowSeatReclineSwitchpac 6 "FAULT" 5 "REARWARD_FAST" 4 "REARWARD_SLOW" 3 "FORWARD_FAST" 2 "FORWARD_SLOW" 1 "INACTIVE" 0 "DISCONNECTED" ;
VAL_ 963 VCRIGHT_frontSeatThighSupportRet 3 "SWITCH_FAULT" 2 "SWITCH_ON" 1 "SWITCH_OFF" 0 "SWITCH_SNA" ;
VAL_ 899 VCRIGHT_thsTemperature 255 "SNA" ;
VAL_ 899 VCRIGHT_thsState 4 "IDLE" 3 "WAIT_CRC_RESPONSE" 2 "WAIT_CRC_REQUEST" 1 "CONFIG" 0 "INIT" ;
VAL_ 899 VCRIGHT_thsLINCurrentSchedule 7 "OTHER" 3 "DIAGNOSTIC" 2 "CONFIG" 1 "MAIN" 0 "OFF" ;
VAL_ 899 VCRIGHT_thsHumidity 127 "SNA" ;
VAL_ 899 VCRIGHT_estimatedVehicleSituatio 2 "VEHICLE_SITUATION_OUTDOOR" 1 "VEHICLE_SITUATION_INDOOR" 0 "VEHICLE_SITUATION_UNKNOWN" ;
VAL_ 899 VCRIGHT_thsSolarLoadInfrared 1023 "SNA" ;
VAL_ 899 VCRIGHT_thsSolarLoadVisible 1023 "SNA" ;
VAL_ 899 VCRIGHT_estimatedThsSolarLoad 1023 "SNA" ;
VAL_ 1059 VCRIGHT_nmKeepAwakeReason 31 "VCRIGHT_KEEPAWAKE_REASON_MULTIPLE" 17 "VCRIGHT_KEEPAWAKE_REASON_DEFOG_CMD" 16 "VCRIGHT_KEEPAWAKE_REASON_DEFOG_CAMERA" 15 "VCRIGHT_KEEPAWAKE_REASON_VOC_PURGE" 14 "VCRIGHT_KEEPAWAKE_REASON_OTHER" 12 "VCRIGHT_KEEPAWAKE_REASON_TRUNK_SWITCH" 11 "VCRIGHT_KEEPAWAKE_REASON_HVAC_EVAP_DRYING" 10 "VCRIGHT_KEEPAWAKE_REASON_UDS_ACTIVE" 9 "VCRIGHT_KEEPAWAKE_REASON_TRUNK_LIGHT" 8 "VCRIGHT_KEEPAWAKE_REASON_SEAT" 7 "VCRIGHT_KEEPAWAKE_REASON_HANDLE" 6 "VCRIGHT_KEEPAWAKE_REASON_EPB_SUMMON_ACTIVE" 5 "VCRIGHT_KEEPAWAKE_REASON_CLOSURE_LATCH" 4 "VCRIGHT_KEEPAWAKE_REASON_HVAC_PRECONDITIONING" 3 "VCRIGHT_KEEPAWAKE_REASON_HVAC_CABIN_PURGE" 2 "VCRIGHT_KEEPAWAKE_REASON_EPB_NOT_SECURE" 1 "VCRIGHT_KEEPAWAKE_REASON_EPB_STATE_NOT_SAVED" 0 "VCRIGHT_KEEPAWAKE_REASON_NONE_SNA" ;
VAL_ 1059 VCRIGHT_nmWakeUpReason 15 "VCRIGHT_WAKEUP_REASON_UNKNOWN" 14 "VCRIGHT_WAKEUP_REASON_DEFOG_CMD" 13 "VCRIGHT_WAKEUP_REASON_DEFOG_CAMERA" 12 "VCRIGHT_WAKEUP_REASON_VOC_PURGE" 11 "VCRIGHT_WAKEUP_REASON_POWER_ON_RESET" 10 "VCRIGHT_WAKEUP_REASON_CABIN_HOT" 9 "VCRIGHT_WAKEUP_REASON_TRUNK_LATCH" 8 "VCRIGHT_WAKEUP_REASON_TRUNK_SWITCH" 7 "VCRIGHT_WAKEUP_REASON_LIN_RX" 6 "VCRIGHT_WAKEUP_REASON_EXTERIOR_HANDLE" 5 "VCRIGHT_WAKEUP_REASON_INTERIOR_HANDLE" 4 "VCRIGHT_WAKEUP_REASON_DOOR_LATCH" 3 "VCRIGHT_WAKEUP_REASON_RESET" 2 "VCRIGHT_WAKEUP_REASON_SWITCH_INPUT" 1 "VCRIGHT_WAKEUP_REASON_ECU_SPECIFIC" 0 "VCRIGHT_WAKEUP_REASON_NONE" ;
VAL_ 1059 VCRIGHT_nmDebugWakeUp 2147483648 "WKPU_31" 1073741824 "WKPU_30" 536870912 "WKPU_29" 268435456 "WKPU_28" 134217728 "WKPU_27" 67108864 "WKPU_26" 33554432 "WKPU_25" 16777216 "WKPU_24" 8388608 "WKPU_23" 4194304 "WKPU_22" 2097152 "WKPU_21" 1048576 "WKPU_20" 524288 "WKPU_19" 262144 "WKPU_18" 131072 "WKPU_17" 65536 "WKPU_16" 32768 "WKPU_15" 16384 "WKPU_14" 8192 "WKPU_13" 4096 "WKPU_12" 2048 "WKPU_11" 1024 "WKPU_10" 512 "WKPU_9" 256 "WKPU_8" 128 "WKPU_7" 64 "WKPU_6" 32 "WKPU_5" 16 "WKPU_4" 8 "WKPU_3" 4 "WKPU_2" 2 "WKPU_1" 1 "WKPU_0" 0 "WKPU_NONE" ;
VAL_ 1059 VCRIGHT_nmEthKeepAwakeReason 15 "VCRIGHT_ETH_KEEPAWAKE_REASON_MULTIPLE" 14 "VCRIGHT_ETH_KEEPAWAKE_REASON_OTHER" 6 "VCRIGHT_ETH_KEEPAWAKE_REASON_TEMP_SENSE_COP_VARIANT_ACTIVE" 5 "VCRIGHT_ETH_KEEPAWAKE_REASON_TEMP_SENSE_POLL" 4 "VCRIGHT_ETH_KEEPAWAKE_REASON_TEMP_SENSE_VCSEC_WAKE" 3 "VCRIGHT_ETH_KEEPAWAKE_REASON_TEMP_SENSE_DWELL_TIME_END" 2 "VCRIGHT_ETH_KEEPAWAKE_REASON_TEMP_SENSE_TRANSITION_FROM_OFF" 1 "VCRIGHT_ETH_KEEPAWAKE_REASON_TEMP_SENSE_TRANSITION_FROM_ACC" 0 "VCRIGHT_ETH_KEEPAWAKE_REASON_NONE_SNA" ;
VAL_ 1059 VCRIGHT_nmChKeepAwakeReason 15 "VCRIGHT_CH_KEEPAWAKE_REASON_MULTIPLE" 14 "VCRIGHT_CH_KEEPAWAKE_REASON_OTHER" 2 "VCRIGHT_CH_KEEPAWAKE_REASON_DEFOG_CMD" 1 "VCRIGHT_CH_KEEPAWAKE_REASON_DEFOG_CAMERA" 0 "VCRIGHT_CH_KEEPAWAKE_REASON_NONE_SNA" ;
VAL_ 707 VCRIGHT_windowStatusIndex 1 "Mux1" 0 "Mux0" ;
VAL_ 707 VCRIGHT_windowStateRF 10 "WINDOW_STATE_SHORT_RISE_REVERSE" 9 "WINDOW_STATE_SHORT_RISE" 8 "WINDOW_STATE_BACKDRIVE" 7 "WINDOW_STATE_MOVING_AUTO_DOWN" 6 "WINDOW_STATE_MOVING_AUTO_UP" 5 "WINDOW_STATE_SHORT_DROP_REVERSE" 4 "WINDOW_STATE_SHORT_DROP" 3 "WINDOW_STATE_BACKOFF" 2 "WINDOW_STATE_MOVING_DOWN" 1 "WINDOW_STATE_MOVING_UP" 0 "WINDOW_STATE_STOPPED" ;
VAL_ 707 VCRIGHT_windowTrimClearMoveReque 3 "WINDOW_TRIM_CLEAR_MOVE_REQUEST_BACKDRIVE" 2 "WINDOW_TRIM_CLEAR_MOVE_REQUEST_RESEAL" 1 "WINDOW_TRIM_CLEAR_MOVE_REQUEST_IDLE" 0 "WINDOW_TRIM_CLEAR_MOVE_REQUEST_SNA" ;
VAL_ 707 VCRIGHT_windowTrimClearActiveReq 2 "WINDOW_TRIM_CLEAR_ACTIVE_REQUEST_ACTIVE" 1 "WINDOW_TRIM_CLEAR_ACTIVE_REQUEST_INACTIVE" 0 "WINDOW_TRIM_CLEAR_ACTIVE_REQUEST_SNA" ;
VAL_ 707 VCRIGHT_windowPositionRF 1 "SNA" ;
VAL_ 707 VCRIGHT_windowStateRR 10 "WINDOW_STATE_SHORT_RISE_REVERSE" 9 "WINDOW_STATE_SHORT_RISE" 8 "WINDOW_STATE_BACKDRIVE" 7 "WINDOW_STATE_MOVING_AUTO_DOWN" 6 "WINDOW_STATE_MOVING_AUTO_UP" 5 "WINDOW_STATE_SHORT_DROP_REVERSE" 4 "WINDOW_STATE_SHORT_DROP" 3 "WINDOW_STATE_BACKOFF" 2 "WINDOW_STATE_MOVING_DOWN" 1 "WINDOW_STATE_MOVING_UP" 0 "WINDOW_STATE_STOPPED" ;
VAL_ 707 VCRIGHT_windowThermalModeRF 3 "WINDOW_THERMAL_MODE_CRITICAL" 2 "WINDOW_THERMAL_MODE_ALERT" 1 "WINDOW_THERMAL_MODE_NORMAL" 0 "WINDOW_THERMAL_MODE_SNA" ;
VAL_ 707 VCRIGHT_windowStopReasonRF 6 "WINDOW_STOP_REASON_STATE_TIMEOUT" 5 "WINDOW_STOP_REASON_FULL_OPEN_SOFT_STOP" 4 "WINDOW_STOP_REASON_STOP_REQUEST" 3 "WINDOW_STOP_REASON_TARGET_REACHED" 2 "WINDOW_STOP_REASON_NEW_REQUEST" 1 "WINDOW_STOP_REASON_DOOR_OPEN_TRIM_PROTECT" 0 "WINDOW_STOP_REASON_NONE" ;
VAL_ 707 VCRIGHT_windowStopReqReasonRF 8 "WINDOW_STOP_REQUEST_REASON_EXTERNAL_REQUEST" 7 "WINDOW_STOP_REQUEST_REASON_FULL_OPEN_SOFT_STOP" 6 "WINDOW_STOP_REQUEST_REASON_STATE_TIMEOUT" 5 "WINDOW_STOP_REQUEST_REASON_STALL" 4 "WINDOW_STOP_REQUEST_REASON_THERMAL" 3 "WINDOW_STOP_REQUEST_REASON_REAR_LOCKOUT" 2 "WINDOW_STOP_REQUEST_REASON_SWITCH_RELEASED" 1 "WINDOW_STOP_REQUEST_REASON_SWITCH_CANCEL_AUTO_MOVEMENT" 0 "WINDOW_STOP_REQUEST_REASON_NONE" ;
VAL_ 707 VCRIGHT_windowThermalModeRR 3 "WINDOW_THERMAL_MODE_CRITICAL" 2 "WINDOW_THERMAL_MODE_ALERT" 1 "WINDOW_THERMAL_MODE_NORMAL" 0 "WINDOW_THERMAL_MODE_SNA" ;
VAL_ 707 VCRIGHT_windowStopReasonRR 6 "WINDOW_STOP_REASON_STATE_TIMEOUT" 5 "WINDOW_STOP_REASON_FULL_OPEN_SOFT_STOP" 4 "WINDOW_STOP_REASON_STOP_REQUEST" 3 "WINDOW_STOP_REASON_TARGET_REACHED" 2 "WINDOW_STOP_REASON_NEW_REQUEST" 1 "WINDOW_STOP_REASON_DOOR_OPEN_TRIM_PROTECT" 0 "WINDOW_STOP_REASON_NONE" ;
VAL_ 707 VCRIGHT_windowStopReqReasonRR 8 "WINDOW_STOP_REQUEST_REASON_EXTERNAL_REQUEST" 7 "WINDOW_STOP_REQUEST_REASON_FULL_OPEN_SOFT_STOP" 6 "WINDOW_STOP_REQUEST_REASON_STATE_TIMEOUT" 5 "WINDOW_STOP_REQUEST_REASON_STALL" 4 "WINDOW_STOP_REQUEST_REASON_THERMAL" 3 "WINDOW_STOP_REQUEST_REASON_REAR_LOCKOUT" 2 "WINDOW_STOP_REQUEST_REASON_SWITCH_RELEASED" 1 "WINDOW_STOP_REQUEST_REASON_SWITCH_CANCEL_AUTO_MOVEMENT" 0 "WINDOW_STOP_REQUEST_REASON_NONE" ;
VAL_ 707 VCRIGHT_windowControlStateRF 2 "WINDOW_CONTROL_STATE_GOING_TO_POSITION" 1 "WINDOW_CONTROL_STATE_CLOSING" 0 "WINDOW_CONTROL_STATE_IDLE" ;
VAL_ 707 VCRIGHT_windowCtrlUnavailableRF 7 "WINDOW_CONTROL_UNAVAILABLE_REASON_WINDOW_MOVING" 6 "WINDOW_CONTROL_UNAVAILABLE_REASON_VEHICLE_IN_DRIVE" 5 "WINDOW_CONTROL_UNAVAILABLE_REASON_UNCALIBRATED" 4 "WINDOW_CONTROL_UNAVAILABLE_REASON_THERMAL_LIMIT" 3 "WINDOW_CONTROL_UNAVAILABLE_REASON_PINCH" 2 "WINDOW_CONTROL_UNAVAILABLE_REASON_SWITCH_PRESSED" 1 "WINDOW_CONTROL_UNAVAILABLE_REASON_UNEXPECTED" 0 "WINDOW_CONTROL_UNAVAILABLE_REASON_NONE" ;
VAL_ 707 VCRIGHT_windowControlStateRR 2 "WINDOW_CONTROL_STATE_GOING_TO_POSITION" 1 "WINDOW_CONTROL_STATE_CLOSING" 0 "WINDOW_CONTROL_STATE_IDLE" ;
VAL_ 707 VCRIGHT_windowCtrlUnavailableRR 7 "WINDOW_CONTROL_UNAVAILABLE_REASON_WINDOW_MOVING" 6 "WINDOW_CONTROL_UNAVAILABLE_REASON_VEHICLE_IN_DRIVE" 5 "WINDOW_CONTROL_UNAVAILABLE_REASON_UNCALIBRATED" 4 "WINDOW_CONTROL_UNAVAILABLE_REASON_THERMAL_LIMIT" 3 "WINDOW_CONTROL_UNAVAILABLE_REASON_PINCH" 2 "WINDOW_CONTROL_UNAVAILABLE_REASON_SWITCH_PRESSED" 1 "WINDOW_CONTROL_UNAVAILABLE_REASON_UNEXPECTED" 0 "WINDOW_CONTROL_UNAVAILABLE_REASON_NONE" ;
VAL_ 707 VCRIGHT_windowPositionStateRF 7 "WINDOW_POSITION_CLOSED_TRIM_CLEAR" 6 "WINDOW_POSITION_FULL_OPEN" 5 "WINDOW_POSITION_PARTIAL_OPEN" 4 "WINDOW_POSITION_DAS_LIMITED" 3 "WINDOW_POSITION_VENT" 2 "WINDOW_POSITION_CRACKED" 1 "WINDOW_POSITION_CLOSED" 0 "WINDOW_POSITION_UNKNOWN" ;
VAL_ 707 VCRIGHT_windowPositionStateRR 7 "WINDOW_POSITION_CLOSED_TRIM_CLEAR" 6 "WINDOW_POSITION_FULL_OPEN" 5 "WINDOW_POSITION_PARTIAL_OPEN" 4 "WINDOW_POSITION_DAS_LIMITED" 3 "WINDOW_POSITION_VENT" 2 "WINDOW_POSITION_CRACKED" 1 "WINDOW_POSITION_CLOSED" 0 "WINDOW_POSITION_UNKNOWN" ;
VAL_ 707 VCRIGHT_windowVehGearStateRF 2 "WINDOW_VEHICLE_GEAR_STATE_IN_GEAR" 1 "WINDOW_VEHICLE_GEAR_STATE_PARK" 0 "WINDOW_VEHICLE_GEAR_STATE_UNKNOWN_SNA" ;
VAL_ 707 VCRIGHT_windowVehGearStateRR 2 "WINDOW_VEHICLE_GEAR_STATE_IN_GEAR" 1 "WINDOW_VEHICLE_GEAR_STATE_PARK" 0 "WINDOW_VEHICLE_GEAR_STATE_UNKNOWN_SNA" ;
VAL_ 707 VCRIGHT_windowSpeedTableStatusRF 2 "WINDOW_SPEED_TABLE_STATUS_FULLY_BUILT" 1 "WINDOW_SPEED_TABLE_STATUS_SENSITIVE_BUILT" 0 "WINDOW_SPEED_TABLE_STATUS_EMPTY_SNA" ;
VAL_ 707 VCRIGHT_windowSpeedTableStatusRR 2 "WINDOW_SPEED_TABLE_STATUS_FULLY_BUILT" 1 "WINDOW_SPEED_TABLE_STATUS_SENSITIVE_BUILT" 0 "WINDOW_SPEED_TABLE_STATUS_EMPTY_SNA" ;
VAL_ 969 VCSEC_BLEEndpointInfoIndex 127 "MAX_VALUE_FOR_COEX" 38 "BLELeftRearAppGithash" 37 "BLELeftRearGeneology" 36 "BLELeftRearInfo" 35 "BLENFCCradleAppGithash" 34 "BLENFCCradleGeneology" 33 "BLENFCCradleInfo" 32 "BLERightRearAppGithash" 31 "BLERightRearGeneology" 30 "BLERightRearInfo" 29 "UWBCenterAppGithash" 28 "UWBCenterGeneology" 27 "UWBCenterInfo" 26 "UWBLeftAppGithash" 25 "UWBLeftGeneology" 24 "UWBLeftInfo" 23 "UWBRearAppGithash" 22 "UWBRearGeneology" 21 "UWBRearInfo" 20 "UWBRearLeftAppGithash" 19 "UWBRearLeftGeneology" 18 "UWBRearLeftInfo" 17 "UWBRearRightAppGithash" 16 "UWBRearRightGeneology" 15 "UWBRearRightInfo" 14 "UWBRightAppGithash" 13 "UWBRightGeneology" 12 "UWBRightInfo" 11 "BLERearInfo" 10 "BLERearGeneology" 9 "BLERearAppGithash" 8 "BLERightInfo" 7 "BLERightGeneology" 6 "BLERightAppGithash" 5 "BLELeftInfo" 4 "BLELeftGeneology" 3 "BLELeftAppGithash" 2 "BLECenterInfo" 1 "BLECenterGeneology" 0 "BLECenterAppGithash" ;
VAL_ 969 VCSEC_UWBRightRadioConfigState 13 "DONE_VERIFYING_RADIO_CONFIG" 12 "WAIT_FOR_LOOPBACK_CALIBRATION" 11 "START_LOOPBACK_CALIBRATION" 10 "WAIT_FOR_PROGRAM_FLASH" 9 "PROGRAM_FLASH" 8 "WAIT_FOR_DOWNLOAD_DATA" 7 "DOWNLOAD_DATA" 6 "WAIT_FOR_INIT_CONFIGURATION" 5 "INIT_CONFIGURATION" 4 "PREPARE_UPDATE" 3 "WAIT_TO_GET_CURRENT_CRC" 2 "GET_CURRENT_CRC" 1 "WAIT_AFTER_TRIGGER" 0 "WAIT_FOR_TRIGGER" ;
VAL_ 969 VCSEC_UWBRightUpdateStatus 7 "SNA" 3 "IN_PROGRESS" 2 "FAIL" 1 "UP_TO_DATE" 0 "NOT_STARTED" ;
VAL_ 969 VCSEC_UWBRearRightRadioConfigSta 13 "DONE_VERIFYING_RADIO_CONFIG" 12 "WAIT_FOR_LOOPBACK_CALIBRATION" 11 "START_LOOPBACK_CALIBRATION" 10 "WAIT_FOR_PROGRAM_FLASH" 9 "PROGRAM_FLASH" 8 "WAIT_FOR_DOWNLOAD_DATA" 7 "DOWNLOAD_DATA" 6 "WAIT_FOR_INIT_CONFIGURATION" 5 "INIT_CONFIGURATION" 4 "PREPARE_UPDATE" 3 "WAIT_TO_GET_CURRENT_CRC" 2 "GET_CURRENT_CRC" 1 "WAIT_AFTER_TRIGGER" 0 "WAIT_FOR_TRIGGER" ;
VAL_ 969 VCSEC_UWBRearRightUpdateStatus 7 "SNA" 3 "IN_PROGRESS" 2 "FAIL" 1 "UP_TO_DATE" 0 "NOT_STARTED" ;
VAL_ 969 VCSEC_UWBRearLeftRadioConfigStat 13 "DONE_VERIFYING_RADIO_CONFIG" 12 "WAIT_FOR_LOOPBACK_CALIBRATION" 11 "START_LOOPBACK_CALIBRATION" 10 "WAIT_FOR_PROGRAM_FLASH" 9 "PROGRAM_FLASH" 8 "WAIT_FOR_DOWNLOAD_DATA" 7 "DOWNLOAD_DATA" 6 "WAIT_FOR_INIT_CONFIGURATION" 5 "INIT_CONFIGURATION" 4 "PREPARE_UPDATE" 3 "WAIT_TO_GET_CURRENT_CRC" 2 "GET_CURRENT_CRC" 1 "WAIT_AFTER_TRIGGER" 0 "WAIT_FOR_TRIGGER" ;
VAL_ 969 VCSEC_UWBRearLeftUpdateStatus 7 "SNA" 3 "IN_PROGRESS" 2 "FAIL" 1 "UP_TO_DATE" 0 "NOT_STARTED" ;
VAL_ 969 VCSEC_UWBRearRadioConfigState 13 "DONE_VERIFYING_RADIO_CONFIG" 12 "WAIT_FOR_LOOPBACK_CALIBRATION" 11 "START_LOOPBACK_CALIBRATION" 10 "WAIT_FOR_PROGRAM_FLASH" 9 "PROGRAM_FLASH" 8 "WAIT_FOR_DOWNLOAD_DATA" 7 "DOWNLOAD_DATA" 6 "WAIT_FOR_INIT_CONFIGURATION" 5 "INIT_CONFIGURATION" 4 "PREPARE_UPDATE" 3 "WAIT_TO_GET_CURRENT_CRC" 2 "GET_CURRENT_CRC" 1 "WAIT_AFTER_TRIGGER" 0 "WAIT_FOR_TRIGGER" ;
VAL_ 969 VCSEC_UWBRearUpdateStatus 7 "SNA" 3 "IN_PROGRESS" 2 "FAIL" 1 "UP_TO_DATE" 0 "NOT_STARTED" ;
VAL_ 969 VCSEC_UWBLeftRadioConfigState 13 "DONE_VERIFYING_RADIO_CONFIG" 12 "WAIT_FOR_LOOPBACK_CALIBRATION" 11 "START_LOOPBACK_CALIBRATION" 10 "WAIT_FOR_PROGRAM_FLASH" 9 "PROGRAM_FLASH" 8 "WAIT_FOR_DOWNLOAD_DATA" 7 "DOWNLOAD_DATA" 6 "WAIT_FOR_INIT_CONFIGURATION" 5 "INIT_CONFIGURATION" 4 "PREPARE_UPDATE" 3 "WAIT_TO_GET_CURRENT_CRC" 2 "GET_CURRENT_CRC" 1 "WAIT_AFTER_TRIGGER" 0 "WAIT_FOR_TRIGGER" ;
VAL_ 969 VCSEC_UWBLeftUpdateStatus 7 "SNA" 3 "IN_PROGRESS" 2 "FAIL" 1 "UP_TO_DATE" 0 "NOT_STARTED" ;
VAL_ 969 VCSEC_UWBCenterRadioConfigState 13 "DONE_VERIFYING_RADIO_CONFIG" 12 "WAIT_FOR_LOOPBACK_CALIBRATION" 11 "START_LOOPBACK_CALIBRATION" 10 "WAIT_FOR_PROGRAM_FLASH" 9 "PROGRAM_FLASH" 8 "WAIT_FOR_DOWNLOAD_DATA" 7 "DOWNLOAD_DATA" 6 "WAIT_FOR_INIT_CONFIGURATION" 5 "INIT_CONFIGURATION" 4 "PREPARE_UPDATE" 3 "WAIT_TO_GET_CURRENT_CRC" 2 "GET_CURRENT_CRC" 1 "WAIT_AFTER_TRIGGER" 0 "WAIT_FOR_TRIGGER" ;
VAL_ 969 VCSEC_UWBCenterUpdateStatus 7 "SNA" 3 "IN_PROGRESS" 2 "FAIL" 1 "UP_TO_DATE" 0 "NOT_STARTED" ;
VAL_ 607 VCSEC_childSeat0_connectionState 5 "DISCONNECTING" 4 "CONNECTED" 3 "WAIT_FOR_CONNECTION" 2 "CONNECTION_REQUEST" 1 "WAIT_FOR_ADV" 0 "INVALID" ;
VAL_ 607 VCSEC_childSeat0_taskDisconnecti 3 "CONNECTION_STATE_MISMATCH" 2 "BAD_CONNECTION_DROPPED" 1 "REQUESTED" 0 "NONE" ;
VAL_ 607 VCSEC_childSeat0_state 8 "DEVICE_READY" 7 "DEVICE_READ_STATUS_WAIT_FOR_RESPONSE" 6 "DEVICE_READ_STATUS" 5 "DEVICE_SIGNUP_NOTIFICATION_WAIT_FOR_RESPONSE" 4 "DEVICE_SIGNUP_NOTIFICATION" 3 "DEVICE_INIT_RESPONSE" 2 "DEVICE_INIT_WAIT_FOR_RESPONSE" 1 "DEVICE_INIT_REQUEST" 0 "DEVICE_IDLE" ;
VAL_ 607 VCSEC_childSeat0_taskErrorCode 4 "TIMEOUT" 3 "READ_STATUS_ERROR" 2 "SIGN_UP_NOTIFICATION_ERROR" 1 "INIT_ERROR" 0 "NONE" ;
VAL_ 607 VCSEC_childSeat0_RSSI 127 "SNA" ;
VAL_ 607 VCSEC_childSeat0_ISOFixStatus 2 "INSTALLED" 1 "NOT_INSTALLED" 0 "INVALID" ;
VAL_ 607 VCSEC_childSeat0_buckleStatus 2 "BUCKLED" 1 "NOT_BUCKLED" 0 "INVALID" ;
VAL_ 607 VCSEC_childSeat0_occupancyStatus 2 "OCCUPIED" 1 "NOT_OCCUPIED" 0 "INVALID" ;
VAL_ 607 VCSEC_childSeat1_connectionState 5 "DISCONNECTING" 4 "CONNECTED" 3 "WAIT_FOR_CONNECTION" 2 "CONNECTION_REQUEST" 1 "WAIT_FOR_ADV" 0 "INVALID" ;
VAL_ 607 VCSEC_childSeat1_taskDisconnecti 3 "CONNECTION_STATE_MISMATCH" 2 "BAD_CONNECTION_DROPPED" 1 "REQUESTED" 0 "NONE" ;
VAL_ 607 VCSEC_childSeat1_state 8 "DEVICE_READY" 7 "DEVICE_READ_STATUS_WAIT_FOR_RESPONSE" 6 "DEVICE_READ_STATUS" 5 "DEVICE_SIGNUP_NOTIFICATION_WAIT_FOR_RESPONSE" 4 "DEVICE_SIGNUP_NOTIFICATION" 3 "DEVICE_INIT_RESPONSE" 2 "DEVICE_INIT_WAIT_FOR_RESPONSE" 1 "DEVICE_INIT_REQUEST" 0 "DEVICE_IDLE" ;
VAL_ 607 VCSEC_childSeat1_taskErrorCode 4 "TIMEOUT" 3 "READ_STATUS_ERROR" 2 "SIGN_UP_NOTIFICATION_ERROR" 1 "INIT_ERROR" 0 "NONE" ;
VAL_ 607 VCSEC_childSeat1_RSSI 127 "SNA" ;
VAL_ 607 VCSEC_childSeat1_ISOFixStatus 2 "INSTALLED" 1 "NOT_INSTALLED" 0 "INVALID" ;
VAL_ 607 VCSEC_childSeat1_buckleStatus 2 "BUCKLED" 1 "NOT_BUCKLED" 0 "INVALID" ;
VAL_ 607 VCSEC_childSeat1_occupancyStatus 2 "OCCUPIED" 1 "NOT_OCCUPIED" 0 "INVALID" ;
VAL_ 607 VCSEC_childSeatScanStatus 2 "TIMEOUT" 1 "SCANNING" 0 "IDLE" ;
VAL_ 607 VCSEC_childPresenceDetectionStat 8 "ESCALATED_WARNING" 7 "INTERVENTION" 6 "INITIAL_WARNING" 5 "ARMED" 4 "WAIT_FOR_LOCK" 3 "IDLE" 2 "DEACTIVE" 1 "FAULTED" 0 "NOT_CONFIGURED" ;
VAL_ 607 VCSEC_childPresenceDetectionSupp 2 "EU_REG" 1 "CN_REG" 0 "NONE" ;
VAL_ 857 VCSEC_DeviceStatusIndex 119 "19_ANDROID_INFO" 118 "19_MODEL_NUMBER" 117 "19_INFO2" 116 "19_INFO" 115 "19_STATS" 114 "19_VITALS" 113 "18_ANDROID_INFO" 112 "18_MODEL_NUMBER" 111 "18_INFO2" 110 "18_INFO" 109 "18_STATS" 108 "18_VITALS" 107 "17_ANDROID_INFO" 106 "17_MODEL_NUMBER" 105 "17_INFO2" 104 "17_INFO" 103 "17_STATS" 102 "17_VITALS" 101 "16_ANDROID_INFO" 100 "16_MODEL_NUMBER" 99 "16_INFO2" 98 "16_INFO" 97 "16_STATS" 96 "16_VITALS" 95 "15_ANDROID_INFO" 94 "15_MODEL_NUMBER" 93 "15_INFO2" 92 "15_INFO" 91 "15_STATS" 90 "15_VITALS" 89 "14_ANDROID_INFO" 88 "14_MODEL_NUMBER" 87 "14_INFO2" 86 "14_INFO" 85 "14_STATS" 84 "14_VITALS" 83 "13_ANDROID_INFO" 82 "13_MODEL_NUMBER" 81 "13_INFO2" 80 "13_INFO" 79 "13_STATS" 78 "13_VITALS" 77 "12_ANDROID_INFO" 76 "12_MODEL_NUMBER" 75 "12_INFO2" 74 "12_INFO" 73 "12_STATS" 72 "12_VITALS" 71 "11_ANDROID_INFO" 70 "11_MODEL_NUMBER" 69 "11_INFO2" 68 "11_INFO" 67 "11_STATS" 66 "11_VITALS" 65 "10_ANDROID_INFO" 64 "10_MODEL_NUMBER" 63 "10_INFO2" 62 "10_INFO" 61 "10_STATS" 60 "10_VITALS" 59 "9_ANDROID_INFO" 58 "9_MODEL_NUMBER" 57 "9_INFO2" 56 "9_INFO" 55 "9_STATS" 54 "9_VITALS" 53 "8_ANDROID_INFO" 52 "8_MODEL_NUMBER" 51 "8_INFO2" 50 "8_INFO" 49 "8_STATS" 48 "8_VITALS" 47 "7_ANDROID_INFO" 46 "7_MODEL_NUMBER" 45 "7_INFO2" 44 "7_INFO" 43 "7_STATS" 42 "7_VITALS" 41 "6_ANDROID_INFO" 40 "6_MODEL_NUMBER" 39 "6_INFO2" 38 "6_INFO" 37 "6_STATS" 36 "6_VITALS" 35 "5_ANDROID_INFO" 34 "5_MODEL_NUMBER" 33 "5_INFO2" 32 "5_INFO" 31 "5_STATS" 30 "5_VITALS" 29 "4_ANDROID_INFO" 28 "4_MODEL_NUMBER" 27 "4_INFO2" 26 "4_INFO" 25 "4_STATS" 24 "4_VITALS" 23 "3_ANDROID_INFO" 22 "3_MODEL_NUMBER" 21 "3_INFO2" 20 "3_INFO" 19 "3_STATS" 18 "3_VITALS" 17 "2_ANDROID_INFO" 16 "2_MODEL_NUMBER" 15 "2_INFO2" 14 "2_INFO" 13 "2_STATS" 12 "2_VITALS" 11 "1_ANDROID_INFO" 10 "1_MODEL_NUMBER" 9 "1_INFO2" 8 "1_INFO" 7 "1_STATS" 6 "1_VITALS" 5 "0_ANDROID_INFO" 4 "0_MODEL_NUMBER" 3 "0_INFO2" 2 "0_INFO" 1 "0_STATS" 0 "0_VITALS" ;
VAL_ 857 VCSEC_Device0AuthResponseTime 127 "SNA" ;
VAL_ 857 VCSEC_Device0Formfactor 19 "KEY_FORM_FACTOR_HARMONY_OS_NEXT_DEVICE" 18 "KEY_FORM_FACTOR_NFC_CARD_WATCHDATA_PLASTIC_CARD" 17 "KEY_FORM_FACTOR_APPLE_WATCH" 16 "KEY_FORM_FACTOR_NFC_CARD_IDEMIA_PLASTIC_CARD" 15 "KEY_FORM_FACTOR_NFC_CARD_IDEMIA_METAL_CARD" 14 "KEY_FORM_FACTOR_NFC_CARD_P71" 13 "KEY_FORM_FACTOR_3_BUTTON_GEN2_CAR_KEYFOB_P60_V3" 12 "KEY_FORM_FACTOR_3_BUTTON_GEN2_CAR_KEYFOB_P60_V2" 11 "KEY_FORM_FACTOR_5_BUTTON_GEN2_CAR_KEYFOB_P60" 10 "KEY_FORM_FACTOR_3_BUTTON_GEN2_CAR_KEYFOB_P60" 9 "KEY_FORM_FACTOR_CLOUD_KEY" 8 "KEY_FORM_FACTOR_3_BUTTON_BLE_CAR_KEYFOB_P60" 7 "KEY_FORM_FACTOR_ANDROID_DEVICE" 6 "KEY_FORM_FACTOR_IOS_DEVICE" 5 "KEY_FORM_FACTOR_BLE_AND_NFC_DEVICE" 4 "KEY_FORM_FACTOR_NFC_DEVICE" 3 "KEY_FORM_FACTOR_BLE_DEVICE" 2 "KEY_FORM_FACTOR_3_BUTTON_BLE_CAR_KEYFOB" 1 "KEY_FORM_FACTOR_NFC_CARD" 0 "KEY_FORM_FACTOR_UNKNOWN" ;
VAL_ 857 VCSEC_Device0Role 10 "DEVICE_ROLE_PREDELIVERY_KEY" 9 "DEVICE_ROLE_RIDER_KEY" 8 "DEVICE_ROLE_GUEST_KEY" 7 "DEVICE_ROLE_SERVICE_TECH_KEY" 6 "DEVICE_ROLE_CHARGING_MANAGER_KEY" 5 "DEVICE_ROLE_VEHICLE_MONITOR_KEY" 4 "DEVICE_ROLE_FM_KEY" 3 "DEVICE_ROLE_DRIVER_KEY" 2 "DEVICE_ROLE_OWNER_KEY" 1 "DEVICE_ROLE_SERVICE_KEY" 0 "DEVICE_ROLE_NONE" ;
VAL_ 857 VCSEC_Device1AuthResponseTime 127 "SNA" ;
VAL_ 857 VCSEC_Device1Formfactor 19 "KEY_FORM_FACTOR_HARMONY_OS_NEXT_DEVICE" 18 "KEY_FORM_FACTOR_NFC_CARD_WATCHDATA_PLASTIC_CARD" 17 "KEY_FORM_FACTOR_APPLE_WATCH" 16 "KEY_FORM_FACTOR_NFC_CARD_IDEMIA_PLASTIC_CARD" 15 "KEY_FORM_FACTOR_NFC_CARD_IDEMIA_METAL_CARD" 14 "KEY_FORM_FACTOR_NFC_CARD_P71" 13 "KEY_FORM_FACTOR_3_BUTTON_GEN2_CAR_KEYFOB_P60_V3" 12 "KEY_FORM_FACTOR_3_BUTTON_GEN2_CAR_KEYFOB_P60_V2" 11 "KEY_FORM_FACTOR_5_BUTTON_GEN2_CAR_KEYFOB_P60" 10 "KEY_FORM_FACTOR_3_BUTTON_GEN2_CAR_KEYFOB_P60" 9 "KEY_FORM_FACTOR_CLOUD_KEY" 8 "KEY_FORM_FACTOR_3_BUTTON_BLE_CAR_KEYFOB_P60" 7 "KEY_FORM_FACTOR_ANDROID_DEVICE" 6 "KEY_FORM_FACTOR_IOS_DEVICE" 5 "KEY_FORM_FACTOR_BLE_AND_NFC_DEVICE" 4 "KEY_FORM_FACTOR_NFC_DEVICE" 3 "KEY_FORM_FACTOR_BLE_DEVICE" 2 "KEY_FORM_FACTOR_3_BUTTON_BLE_CAR_KEYFOB" 1 "KEY_FORM_FACTOR_NFC_CARD" 0 "KEY_FORM_FACTOR_UNKNOWN" ;
VAL_ 857 VCSEC_Device1Role 10 "DEVICE_ROLE_PREDELIVERY_KEY" 9 "DEVICE_ROLE_RIDER_KEY" 8 "DEVICE_ROLE_GUEST_KEY" 7 "DEVICE_ROLE_SERVICE_TECH_KEY" 6 "DEVICE_ROLE_CHARGING_MANAGER_KEY" 5 "DEVICE_ROLE_VEHICLE_MONITOR_KEY" 4 "DEVICE_ROLE_FM_KEY" 3 "DEVICE_ROLE_DRIVER_KEY" 2 "DEVICE_ROLE_OWNER_KEY" 1 "DEVICE_ROLE_SERVICE_KEY" 0 "DEVICE_ROLE_NONE" ;
VAL_ 857 VCSEC_Device2AuthResponseTime 127 "SNA" ;
VAL_ 857 VCSEC_Device2Formfactor 19 "KEY_FORM_FACTOR_HARMONY_OS_NEXT_DEVICE" 18 "KEY_FORM_FACTOR_NFC_CARD_WATCHDATA_PLASTIC_CARD" 17 "KEY_FORM_FACTOR_APPLE_WATCH" 16 "KEY_FORM_FACTOR_NFC_CARD_IDEMIA_PLASTIC_CARD" 15 "KEY_FORM_FACTOR_NFC_CARD_IDEMIA_METAL_CARD" 14 "KEY_FORM_FACTOR_NFC_CARD_P71" 13 "KEY_FORM_FACTOR_3_BUTTON_GEN2_CAR_KEYFOB_P60_V3" 12 "KEY_FORM_FACTOR_3_BUTTON_GEN2_CAR_KEYFOB_P60_V2" 11 "KEY_FORM_FACTOR_5_BUTTON_GEN2_CAR_KEYFOB_P60" 10 "KEY_FORM_FACTOR_3_BUTTON_GEN2_CAR_KEYFOB_P60" 9 "KEY_FORM_FACTOR_CLOUD_KEY" 8 "KEY_FORM_FACTOR_3_BUTTON_BLE_CAR_KEYFOB_P60" 7 "KEY_FORM_FACTOR_ANDROID_DEVICE" 6 "KEY_FORM_FACTOR_IOS_DEVICE" 5 "KEY_FORM_FACTOR_BLE_AND_NFC_DEVICE" 4 "KEY_FORM_FACTOR_NFC_DEVICE" 3 "KEY_FORM_FACTOR_BLE_DEVICE" 2 "KEY_FORM_FACTOR_3_BUTTON_BLE_CAR_KEYFOB" 1 "KEY_FORM_FACTOR_NFC_CARD" 0 "KEY_FORM_FACTOR_UNKNOWN" ;
VAL_ 857 VCSEC_Device2Role 10 "DEVICE_ROLE_PREDELIVERY_KEY" 9 "DEVICE_ROLE_RIDER_KEY" 8 "DEVICE_ROLE_GUEST_KEY" 7 "DEVICE_ROLE_SERVICE_TECH_KEY" 6 "DEVICE_ROLE_CHARGING_MANAGER_KEY" 5 "DEVICE_ROLE_VEHICLE_MONITOR_KEY" 4 "DEVICE_ROLE_FM_KEY" 3 "DEVICE_ROLE_DRIVER_KEY" 2 "DEVICE_ROLE_OWNER_KEY" 1 "DEVICE_ROLE_SERVICE_KEY" 0 "DEVICE_ROLE_NONE" ;
VAL_ 857 VCSEC_Device3AuthResponseTime 127 "SNA" ;
VAL_ 857 VCSEC_Device3Formfactor 19 "KEY_FORM_FACTOR_HARMONY_OS_NEXT_DEVICE" 18 "KEY_FORM_FACTOR_NFC_CARD_WATCHDATA_PLASTIC_CARD" 17 "KEY_FORM_FACTOR_APPLE_WATCH" 16 "KEY_FORM_FACTOR_NFC_CARD_IDEMIA_PLASTIC_CARD" 15 "KEY_FORM_FACTOR_NFC_CARD_IDEMIA_METAL_CARD" 14 "KEY_FORM_FACTOR_NFC_CARD_P71" 13 "KEY_FORM_FACTOR_3_BUTTON_GEN2_CAR_KEYFOB_P60_V3" 12 "KEY_FORM_FACTOR_3_BUTTON_GEN2_CAR_KEYFOB_P60_V2" 11 "KEY_FORM_FACTOR_5_BUTTON_GEN2_CAR_KEYFOB_P60" 10 "KEY_FORM_FACTOR_3_BUTTON_GEN2_CAR_KEYFOB_P60" 9 "KEY_FORM_FACTOR_CLOUD_KEY" 8 "KEY_FORM_FACTOR_3_BUTTON_BLE_CAR_KEYFOB_P60" 7 "KEY_FORM_FACTOR_ANDROID_DEVICE" 6 "KEY_FORM_FACTOR_IOS_DEVICE" 5 "KEY_FORM_FACTOR_BLE_AND_NFC_DEVICE" 4 "KEY_FORM_FACTOR_NFC_DEVICE" 3 "KEY_FORM_FACTOR_BLE_DEVICE" 2 "KEY_FORM_FACTOR_3_BUTTON_BLE_CAR_KEYFOB" 1 "KEY_FORM_FACTOR_NFC_CARD" 0 "KEY_FORM_FACTOR_UNKNOWN" ;
VAL_ 857 VCSEC_Device3Role 10 "DEVICE_ROLE_PREDELIVERY_KEY" 9 "DEVICE_ROLE_RIDER_KEY" 8 "DEVICE_ROLE_GUEST_KEY" 7 "DEVICE_ROLE_SERVICE_TECH_KEY" 6 "DEVICE_ROLE_CHARGING_MANAGER_KEY" 5 "DEVICE_ROLE_VEHICLE_MONITOR_KEY" 4 "DEVICE_ROLE_FM_KEY" 3 "DEVICE_ROLE_DRIVER_KEY" 2 "DEVICE_ROLE_OWNER_KEY" 1 "DEVICE_ROLE_SERVICE_KEY" 0 "DEVICE_ROLE_NONE" ;
VAL_ 857 VCSEC_Device4AuthResponseTime 127 "SNA" ;
VAL_ 857 VCSEC_Device4Formfactor 19 "KEY_FORM_FACTOR_HARMONY_OS_NEXT_DEVICE" 18 "KEY_FORM_FACTOR_NFC_CARD_WATCHDATA_PLASTIC_CARD" 17 "KEY_FORM_FACTOR_APPLE_WATCH" 16 "KEY_FORM_FACTOR_NFC_CARD_IDEMIA_PLASTIC_CARD" 15 "KEY_FORM_FACTOR_NFC_CARD_IDEMIA_METAL_CARD" 14 "KEY_FORM_FACTOR_NFC_CARD_P71" 13 "KEY_FORM_FACTOR_3_BUTTON_GEN2_CAR_KEYFOB_P60_V3" 12 "KEY_FORM_FACTOR_3_BUTTON_GEN2_CAR_KEYFOB_P60_V2" 11 "KEY_FORM_FACTOR_5_BUTTON_GEN2_CAR_KEYFOB_P60" 10 "KEY_FORM_FACTOR_3_BUTTON_GEN2_CAR_KEYFOB_P60" 9 "KEY_FORM_FACTOR_CLOUD_KEY" 8 "KEY_FORM_FACTOR_3_BUTTON_BLE_CAR_KEYFOB_P60" 7 "KEY_FORM_FACTOR_ANDROID_DEVICE" 6 "KEY_FORM_FACTOR_IOS_DEVICE" 5 "KEY_FORM_FACTOR_BLE_AND_NFC_DEVICE" 4 "KEY_FORM_FACTOR_NFC_DEVICE" 3 "KEY_FORM_FACTOR_BLE_DEVICE" 2 "KEY_FORM_FACTOR_3_BUTTON_BLE_CAR_KEYFOB" 1 "KEY_FORM_FACTOR_NFC_CARD" 0 "KEY_FORM_FACTOR_UNKNOWN" ;
VAL_ 857 VCSEC_Device4Role 10 "DEVICE_ROLE_PREDELIVERY_KEY" 9 "DEVICE_ROLE_RIDER_KEY" 8 "DEVICE_ROLE_GUEST_KEY" 7 "DEVICE_ROLE_SERVICE_TECH_KEY" 6 "DEVICE_ROLE_CHARGING_MANAGER_KEY" 5 "DEVICE_ROLE_VEHICLE_MONITOR_KEY" 4 "DEVICE_ROLE_FM_KEY" 3 "DEVICE_ROLE_DRIVER_KEY" 2 "DEVICE_ROLE_OWNER_KEY" 1 "DEVICE_ROLE_SERVICE_KEY" 0 "DEVICE_ROLE_NONE" ;
VAL_ 857 VCSEC_Device5AuthResponseTime 127 "SNA" ;
VAL_ 857 VCSEC_Device5Formfactor 19 "KEY_FORM_FACTOR_HARMONY_OS_NEXT_DEVICE" 18 "KEY_FORM_FACTOR_NFC_CARD_WATCHDATA_PLASTIC_CARD" 17 "KEY_FORM_FACTOR_APPLE_WATCH" 16 "KEY_FORM_FACTOR_NFC_CARD_IDEMIA_PLASTIC_CARD" 15 "KEY_FORM_FACTOR_NFC_CARD_IDEMIA_METAL_CARD" 14 "KEY_FORM_FACTOR_NFC_CARD_P71" 13 "KEY_FORM_FACTOR_3_BUTTON_GEN2_CAR_KEYFOB_P60_V3" 12 "KEY_FORM_FACTOR_3_BUTTON_GEN2_CAR_KEYFOB_P60_V2" 11 "KEY_FORM_FACTOR_5_BUTTON_GEN2_CAR_KEYFOB_P60" 10 "KEY_FORM_FACTOR_3_BUTTON_GEN2_CAR_KEYFOB_P60" 9 "KEY_FORM_FACTOR_CLOUD_KEY" 8 "KEY_FORM_FACTOR_3_BUTTON_BLE_CAR_KEYFOB_P60" 7 "KEY_FORM_FACTOR_ANDROID_DEVICE" 6 "KEY_FORM_FACTOR_IOS_DEVICE" 5 "KEY_FORM_FACTOR_BLE_AND_NFC_DEVICE" 4 "KEY_FORM_FACTOR_NFC_DEVICE" 3 "KEY_FORM_FACTOR_BLE_DEVICE" 2 "KEY_FORM_FACTOR_3_BUTTON_BLE_CAR_KEYFOB" 1 "KEY_FORM_FACTOR_NFC_CARD" 0 "KEY_FORM_FACTOR_UNKNOWN" ;
VAL_ 857 VCSEC_Device5Role 10 "DEVICE_ROLE_PREDELIVERY_KEY" 9 "DEVICE_ROLE_RIDER_KEY" 8 "DEVICE_ROLE_GUEST_KEY" 7 "DEVICE_ROLE_SERVICE_TECH_KEY" 6 "DEVICE_ROLE_CHARGING_MANAGER_KEY" 5 "DEVICE_ROLE_VEHICLE_MONITOR_KEY" 4 "DEVICE_ROLE_FM_KEY" 3 "DEVICE_ROLE_DRIVER_KEY" 2 "DEVICE_ROLE_OWNER_KEY" 1 "DEVICE_ROLE_SERVICE_KEY" 0 "DEVICE_ROLE_NONE" ;
VAL_ 857 VCSEC_Device6AuthResponseTime 127 "SNA" ;
VAL_ 857 VCSEC_Device6Formfactor 19 "KEY_FORM_FACTOR_HARMONY_OS_NEXT_DEVICE" 18 "KEY_FORM_FACTOR_NFC_CARD_WATCHDATA_PLASTIC_CARD" 17 "KEY_FORM_FACTOR_APPLE_WATCH" 16 "KEY_FORM_FACTOR_NFC_CARD_IDEMIA_PLASTIC_CARD" 15 "KEY_FORM_FACTOR_NFC_CARD_IDEMIA_METAL_CARD" 14 "KEY_FORM_FACTOR_NFC_CARD_P71" 13 "KEY_FORM_FACTOR_3_BUTTON_GEN2_CAR_KEYFOB_P60_V3" 12 "KEY_FORM_FACTOR_3_BUTTON_GEN2_CAR_KEYFOB_P60_V2" 11 "KEY_FORM_FACTOR_5_BUTTON_GEN2_CAR_KEYFOB_P60" 10 "KEY_FORM_FACTOR_3_BUTTON_GEN2_CAR_KEYFOB_P60" 9 "KEY_FORM_FACTOR_CLOUD_KEY" 8 "KEY_FORM_FACTOR_3_BUTTON_BLE_CAR_KEYFOB_P60" 7 "KEY_FORM_FACTOR_ANDROID_DEVICE" 6 "KEY_FORM_FACTOR_IOS_DEVICE" 5 "KEY_FORM_FACTOR_BLE_AND_NFC_DEVICE" 4 "KEY_FORM_FACTOR_NFC_DEVICE" 3 "KEY_FORM_FACTOR_BLE_DEVICE" 2 "KEY_FORM_FACTOR_3_BUTTON_BLE_CAR_KEYFOB" 1 "KEY_FORM_FACTOR_NFC_CARD" 0 "KEY_FORM_FACTOR_UNKNOWN" ;
VAL_ 857 VCSEC_Device6Role 10 "DEVICE_ROLE_PREDELIVERY_KEY" 9 "DEVICE_ROLE_RIDER_KEY" 8 "DEVICE_ROLE_GUEST_KEY" 7 "DEVICE_ROLE_SERVICE_TECH_KEY" 6 "DEVICE_ROLE_CHARGING_MANAGER_KEY" 5 "DEVICE_ROLE_VEHICLE_MONITOR_KEY" 4 "DEVICE_ROLE_FM_KEY" 3 "DEVICE_ROLE_DRIVER_KEY" 2 "DEVICE_ROLE_OWNER_KEY" 1 "DEVICE_ROLE_SERVICE_KEY" 0 "DEVICE_ROLE_NONE" ;
VAL_ 857 VCSEC_Device7AuthResponseTime 127 "SNA" ;
VAL_ 857 VCSEC_Device7Formfactor 19 "KEY_FORM_FACTOR_HARMONY_OS_NEXT_DEVICE" 18 "KEY_FORM_FACTOR_NFC_CARD_WATCHDATA_PLASTIC_CARD" 17 "KEY_FORM_FACTOR_APPLE_WATCH" 16 "KEY_FORM_FACTOR_NFC_CARD_IDEMIA_PLASTIC_CARD" 15 "KEY_FORM_FACTOR_NFC_CARD_IDEMIA_METAL_CARD" 14 "KEY_FORM_FACTOR_NFC_CARD_P71" 13 "KEY_FORM_FACTOR_3_BUTTON_GEN2_CAR_KEYFOB_P60_V3" 12 "KEY_FORM_FACTOR_3_BUTTON_GEN2_CAR_KEYFOB_P60_V2" 11 "KEY_FORM_FACTOR_5_BUTTON_GEN2_CAR_KEYFOB_P60" 10 "KEY_FORM_FACTOR_3_BUTTON_GEN2_CAR_KEYFOB_P60" 9 "KEY_FORM_FACTOR_CLOUD_KEY" 8 "KEY_FORM_FACTOR_3_BUTTON_BLE_CAR_KEYFOB_P60" 7 "KEY_FORM_FACTOR_ANDROID_DEVICE" 6 "KEY_FORM_FACTOR_IOS_DEVICE" 5 "KEY_FORM_FACTOR_BLE_AND_NFC_DEVICE" 4 "KEY_FORM_FACTOR_NFC_DEVICE" 3 "KEY_FORM_FACTOR_BLE_DEVICE" 2 "KEY_FORM_FACTOR_3_BUTTON_BLE_CAR_KEYFOB" 1 "KEY_FORM_FACTOR_NFC_CARD" 0 "KEY_FORM_FACTOR_UNKNOWN" ;
VAL_ 857 VCSEC_Device7Role 10 "DEVICE_ROLE_PREDELIVERY_KEY" 9 "DEVICE_ROLE_RIDER_KEY" 8 "DEVICE_ROLE_GUEST_KEY" 7 "DEVICE_ROLE_SERVICE_TECH_KEY" 6 "DEVICE_ROLE_CHARGING_MANAGER_KEY" 5 "DEVICE_ROLE_VEHICLE_MONITOR_KEY" 4 "DEVICE_ROLE_FM_KEY" 3 "DEVICE_ROLE_DRIVER_KEY" 2 "DEVICE_ROLE_OWNER_KEY" 1 "DEVICE_ROLE_SERVICE_KEY" 0 "DEVICE_ROLE_NONE" ;
VAL_ 857 VCSEC_Device8AuthResponseTime 127 "SNA" ;
VAL_ 857 VCSEC_Device8Formfactor 19 "KEY_FORM_FACTOR_HARMONY_OS_NEXT_DEVICE" 18 "KEY_FORM_FACTOR_NFC_CARD_WATCHDATA_PLASTIC_CARD" 17 "KEY_FORM_FACTOR_APPLE_WATCH" 16 "KEY_FORM_FACTOR_NFC_CARD_IDEMIA_PLASTIC_CARD" 15 "KEY_FORM_FACTOR_NFC_CARD_IDEMIA_METAL_CARD" 14 "KEY_FORM_FACTOR_NFC_CARD_P71" 13 "KEY_FORM_FACTOR_3_BUTTON_GEN2_CAR_KEYFOB_P60_V3" 12 "KEY_FORM_FACTOR_3_BUTTON_GEN2_CAR_KEYFOB_P60_V2" 11 "KEY_FORM_FACTOR_5_BUTTON_GEN2_CAR_KEYFOB_P60" 10 "KEY_FORM_FACTOR_3_BUTTON_GEN2_CAR_KEYFOB_P60" 9 "KEY_FORM_FACTOR_CLOUD_KEY" 8 "KEY_FORM_FACTOR_3_BUTTON_BLE_CAR_KEYFOB_P60" 7 "KEY_FORM_FACTOR_ANDROID_DEVICE" 6 "KEY_FORM_FACTOR_IOS_DEVICE" 5 "KEY_FORM_FACTOR_BLE_AND_NFC_DEVICE" 4 "KEY_FORM_FACTOR_NFC_DEVICE" 3 "KEY_FORM_FACTOR_BLE_DEVICE" 2 "KEY_FORM_FACTOR_3_BUTTON_BLE_CAR_KEYFOB" 1 "KEY_FORM_FACTOR_NFC_CARD" 0 "KEY_FORM_FACTOR_UNKNOWN" ;
VAL_ 857 VCSEC_Device8Role 10 "DEVICE_ROLE_PREDELIVERY_KEY" 9 "DEVICE_ROLE_RIDER_KEY" 8 "DEVICE_ROLE_GUEST_KEY" 7 "DEVICE_ROLE_SERVICE_TECH_KEY" 6 "DEVICE_ROLE_CHARGING_MANAGER_KEY" 5 "DEVICE_ROLE_VEHICLE_MONITOR_KEY" 4 "DEVICE_ROLE_FM_KEY" 3 "DEVICE_ROLE_DRIVER_KEY" 2 "DEVICE_ROLE_OWNER_KEY" 1 "DEVICE_ROLE_SERVICE_KEY" 0 "DEVICE_ROLE_NONE" ;
VAL_ 857 VCSEC_Device9AuthResponseTime 127 "SNA" ;
VAL_ 857 VCSEC_Device9Formfactor 19 "KEY_FORM_FACTOR_HARMONY_OS_NEXT_DEVICE" 18 "KEY_FORM_FACTOR_NFC_CARD_WATCHDATA_PLASTIC_CARD" 17 "KEY_FORM_FACTOR_APPLE_WATCH" 16 "KEY_FORM_FACTOR_NFC_CARD_IDEMIA_PLASTIC_CARD" 15 "KEY_FORM_FACTOR_NFC_CARD_IDEMIA_METAL_CARD" 14 "KEY_FORM_FACTOR_NFC_CARD_P71" 13 "KEY_FORM_FACTOR_3_BUTTON_GEN2_CAR_KEYFOB_P60_V3" 12 "KEY_FORM_FACTOR_3_BUTTON_GEN2_CAR_KEYFOB_P60_V2" 11 "KEY_FORM_FACTOR_5_BUTTON_GEN2_CAR_KEYFOB_P60" 10 "KEY_FORM_FACTOR_3_BUTTON_GEN2_CAR_KEYFOB_P60" 9 "KEY_FORM_FACTOR_CLOUD_KEY" 8 "KEY_FORM_FACTOR_3_BUTTON_BLE_CAR_KEYFOB_P60" 7 "KEY_FORM_FACTOR_ANDROID_DEVICE" 6 "KEY_FORM_FACTOR_IOS_DEVICE" 5 "KEY_FORM_FACTOR_BLE_AND_NFC_DEVICE" 4 "KEY_FORM_FACTOR_NFC_DEVICE" 3 "KEY_FORM_FACTOR_BLE_DEVICE" 2 "KEY_FORM_FACTOR_3_BUTTON_BLE_CAR_KEYFOB" 1 "KEY_FORM_FACTOR_NFC_CARD" 0 "KEY_FORM_FACTOR_UNKNOWN" ;
VAL_ 857 VCSEC_Device9Role 10 "DEVICE_ROLE_PREDELIVERY_KEY" 9 "DEVICE_ROLE_RIDER_KEY" 8 "DEVICE_ROLE_GUEST_KEY" 7 "DEVICE_ROLE_SERVICE_TECH_KEY" 6 "DEVICE_ROLE_CHARGING_MANAGER_KEY" 5 "DEVICE_ROLE_VEHICLE_MONITOR_KEY" 4 "DEVICE_ROLE_FM_KEY" 3 "DEVICE_ROLE_DRIVER_KEY" 2 "DEVICE_ROLE_OWNER_KEY" 1 "DEVICE_ROLE_SERVICE_KEY" 0 "DEVICE_ROLE_NONE" ;
VAL_ 857 VCSEC_Device10AuthResponseTime 127 "SNA" ;
VAL_ 857 VCSEC_Device10Formfactor 19 "KEY_FORM_FACTOR_HARMONY_OS_NEXT_DEVICE" 18 "KEY_FORM_FACTOR_NFC_CARD_WATCHDATA_PLASTIC_CARD" 17 "KEY_FORM_FACTOR_APPLE_WATCH" 16 "KEY_FORM_FACTOR_NFC_CARD_IDEMIA_PLASTIC_CARD" 15 "KEY_FORM_FACTOR_NFC_CARD_IDEMIA_METAL_CARD" 14 "KEY_FORM_FACTOR_NFC_CARD_P71" 13 "KEY_FORM_FACTOR_3_BUTTON_GEN2_CAR_KEYFOB_P60_V3" 12 "KEY_FORM_FACTOR_3_BUTTON_GEN2_CAR_KEYFOB_P60_V2" 11 "KEY_FORM_FACTOR_5_BUTTON_GEN2_CAR_KEYFOB_P60" 10 "KEY_FORM_FACTOR_3_BUTTON_GEN2_CAR_KEYFOB_P60" 9 "KEY_FORM_FACTOR_CLOUD_KEY" 8 "KEY_FORM_FACTOR_3_BUTTON_BLE_CAR_KEYFOB_P60" 7 "KEY_FORM_FACTOR_ANDROID_DEVICE" 6 "KEY_FORM_FACTOR_IOS_DEVICE" 5 "KEY_FORM_FACTOR_BLE_AND_NFC_DEVICE" 4 "KEY_FORM_FACTOR_NFC_DEVICE" 3 "KEY_FORM_FACTOR_BLE_DEVICE" 2 "KEY_FORM_FACTOR_3_BUTTON_BLE_CAR_KEYFOB" 1 "KEY_FORM_FACTOR_NFC_CARD" 0 "KEY_FORM_FACTOR_UNKNOWN" ;
VAL_ 857 VCSEC_Device10Role 10 "DEVICE_ROLE_PREDELIVERY_KEY" 9 "DEVICE_ROLE_RIDER_KEY" 8 "DEVICE_ROLE_GUEST_KEY" 7 "DEVICE_ROLE_SERVICE_TECH_KEY" 6 "DEVICE_ROLE_CHARGING_MANAGER_KEY" 5 "DEVICE_ROLE_VEHICLE_MONITOR_KEY" 4 "DEVICE_ROLE_FM_KEY" 3 "DEVICE_ROLE_DRIVER_KEY" 2 "DEVICE_ROLE_OWNER_KEY" 1 "DEVICE_ROLE_SERVICE_KEY" 0 "DEVICE_ROLE_NONE" ;
VAL_ 857 VCSEC_Device11AuthResponseTime 127 "SNA" ;
VAL_ 857 VCSEC_Device11Formfactor 19 "KEY_FORM_FACTOR_HARMONY_OS_NEXT_DEVICE" 18 "KEY_FORM_FACTOR_NFC_CARD_WATCHDATA_PLASTIC_CARD" 17 "KEY_FORM_FACTOR_APPLE_WATCH" 16 "KEY_FORM_FACTOR_NFC_CARD_IDEMIA_PLASTIC_CARD" 15 "KEY_FORM_FACTOR_NFC_CARD_IDEMIA_METAL_CARD" 14 "KEY_FORM_FACTOR_NFC_CARD_P71" 13 "KEY_FORM_FACTOR_3_BUTTON_GEN2_CAR_KEYFOB_P60_V3" 12 "KEY_FORM_FACTOR_3_BUTTON_GEN2_CAR_KEYFOB_P60_V2" 11 "KEY_FORM_FACTOR_5_BUTTON_GEN2_CAR_KEYFOB_P60" 10 "KEY_FORM_FACTOR_3_BUTTON_GEN2_CAR_KEYFOB_P60" 9 "KEY_FORM_FACTOR_CLOUD_KEY" 8 "KEY_FORM_FACTOR_3_BUTTON_BLE_CAR_KEYFOB_P60" 7 "KEY_FORM_FACTOR_ANDROID_DEVICE" 6 "KEY_FORM_FACTOR_IOS_DEVICE" 5 "KEY_FORM_FACTOR_BLE_AND_NFC_DEVICE" 4 "KEY_FORM_FACTOR_NFC_DEVICE" 3 "KEY_FORM_FACTOR_BLE_DEVICE" 2 "KEY_FORM_FACTOR_3_BUTTON_BLE_CAR_KEYFOB" 1 "KEY_FORM_FACTOR_NFC_CARD" 0 "KEY_FORM_FACTOR_UNKNOWN" ;
VAL_ 857 VCSEC_Device11Role 10 "DEVICE_ROLE_PREDELIVERY_KEY" 9 "DEVICE_ROLE_RIDER_KEY" 8 "DEVICE_ROLE_GUEST_KEY" 7 "DEVICE_ROLE_SERVICE_TECH_KEY" 6 "DEVICE_ROLE_CHARGING_MANAGER_KEY" 5 "DEVICE_ROLE_VEHICLE_MONITOR_KEY" 4 "DEVICE_ROLE_FM_KEY" 3 "DEVICE_ROLE_DRIVER_KEY" 2 "DEVICE_ROLE_OWNER_KEY" 1 "DEVICE_ROLE_SERVICE_KEY" 0 "DEVICE_ROLE_NONE" ;
VAL_ 857 VCSEC_Device12AuthResponseTime 127 "SNA" ;
VAL_ 857 VCSEC_Device12Formfactor 19 "KEY_FORM_FACTOR_HARMONY_OS_NEXT_DEVICE" 18 "KEY_FORM_FACTOR_NFC_CARD_WATCHDATA_PLASTIC_CARD" 17 "KEY_FORM_FACTOR_APPLE_WATCH" 16 "KEY_FORM_FACTOR_NFC_CARD_IDEMIA_PLASTIC_CARD" 15 "KEY_FORM_FACTOR_NFC_CARD_IDEMIA_METAL_CARD" 14 "KEY_FORM_FACTOR_NFC_CARD_P71" 13 "KEY_FORM_FACTOR_3_BUTTON_GEN2_CAR_KEYFOB_P60_V3" 12 "KEY_FORM_FACTOR_3_BUTTON_GEN2_CAR_KEYFOB_P60_V2" 11 "KEY_FORM_FACTOR_5_BUTTON_GEN2_CAR_KEYFOB_P60" 10 "KEY_FORM_FACTOR_3_BUTTON_GEN2_CAR_KEYFOB_P60" 9 "KEY_FORM_FACTOR_CLOUD_KEY" 8 "KEY_FORM_FACTOR_3_BUTTON_BLE_CAR_KEYFOB_P60" 7 "KEY_FORM_FACTOR_ANDROID_DEVICE" 6 "KEY_FORM_FACTOR_IOS_DEVICE" 5 "KEY_FORM_FACTOR_BLE_AND_NFC_DEVICE" 4 "KEY_FORM_FACTOR_NFC_DEVICE" 3 "KEY_FORM_FACTOR_BLE_DEVICE" 2 "KEY_FORM_FACTOR_3_BUTTON_BLE_CAR_KEYFOB" 1 "KEY_FORM_FACTOR_NFC_CARD" 0 "KEY_FORM_FACTOR_UNKNOWN" ;
VAL_ 857 VCSEC_Device12Role 10 "DEVICE_ROLE_PREDELIVERY_KEY" 9 "DEVICE_ROLE_RIDER_KEY" 8 "DEVICE_ROLE_GUEST_KEY" 7 "DEVICE_ROLE_SERVICE_TECH_KEY" 6 "DEVICE_ROLE_CHARGING_MANAGER_KEY" 5 "DEVICE_ROLE_VEHICLE_MONITOR_KEY" 4 "DEVICE_ROLE_FM_KEY" 3 "DEVICE_ROLE_DRIVER_KEY" 2 "DEVICE_ROLE_OWNER_KEY" 1 "DEVICE_ROLE_SERVICE_KEY" 0 "DEVICE_ROLE_NONE" ;
VAL_ 857 VCSEC_Device13AuthResponseTime 127 "SNA" ;
VAL_ 857 VCSEC_Device13Formfactor 19 "KEY_FORM_FACTOR_HARMONY_OS_NEXT_DEVICE" 18 "KEY_FORM_FACTOR_NFC_CARD_WATCHDATA_PLASTIC_CARD" 17 "KEY_FORM_FACTOR_APPLE_WATCH" 16 "KEY_FORM_FACTOR_NFC_CARD_IDEMIA_PLASTIC_CARD" 15 "KEY_FORM_FACTOR_NFC_CARD_IDEMIA_METAL_CARD" 14 "KEY_FORM_FACTOR_NFC_CARD_P71" 13 "KEY_FORM_FACTOR_3_BUTTON_GEN2_CAR_KEYFOB_P60_V3" 12 "KEY_FORM_FACTOR_3_BUTTON_GEN2_CAR_KEYFOB_P60_V2" 11 "KEY_FORM_FACTOR_5_BUTTON_GEN2_CAR_KEYFOB_P60" 10 "KEY_FORM_FACTOR_3_BUTTON_GEN2_CAR_KEYFOB_P60" 9 "KEY_FORM_FACTOR_CLOUD_KEY" 8 "KEY_FORM_FACTOR_3_BUTTON_BLE_CAR_KEYFOB_P60" 7 "KEY_FORM_FACTOR_ANDROID_DEVICE" 6 "KEY_FORM_FACTOR_IOS_DEVICE" 5 "KEY_FORM_FACTOR_BLE_AND_NFC_DEVICE" 4 "KEY_FORM_FACTOR_NFC_DEVICE" 3 "KEY_FORM_FACTOR_BLE_DEVICE" 2 "KEY_FORM_FACTOR_3_BUTTON_BLE_CAR_KEYFOB" 1 "KEY_FORM_FACTOR_NFC_CARD" 0 "KEY_FORM_FACTOR_UNKNOWN" ;
VAL_ 857 VCSEC_Device13Role 10 "DEVICE_ROLE_PREDELIVERY_KEY" 9 "DEVICE_ROLE_RIDER_KEY" 8 "DEVICE_ROLE_GUEST_KEY" 7 "DEVICE_ROLE_SERVICE_TECH_KEY" 6 "DEVICE_ROLE_CHARGING_MANAGER_KEY" 5 "DEVICE_ROLE_VEHICLE_MONITOR_KEY" 4 "DEVICE_ROLE_FM_KEY" 3 "DEVICE_ROLE_DRIVER_KEY" 2 "DEVICE_ROLE_OWNER_KEY" 1 "DEVICE_ROLE_SERVICE_KEY" 0 "DEVICE_ROLE_NONE" ;
VAL_ 857 VCSEC_Device14AuthResponseTime 127 "SNA" ;
VAL_ 857 VCSEC_Device14Formfactor 19 "KEY_FORM_FACTOR_HARMONY_OS_NEXT_DEVICE" 18 "KEY_FORM_FACTOR_NFC_CARD_WATCHDATA_PLASTIC_CARD" 17 "KEY_FORM_FACTOR_APPLE_WATCH" 16 "KEY_FORM_FACTOR_NFC_CARD_IDEMIA_PLASTIC_CARD" 15 "KEY_FORM_FACTOR_NFC_CARD_IDEMIA_METAL_CARD" 14 "KEY_FORM_FACTOR_NFC_CARD_P71" 13 "KEY_FORM_FACTOR_3_BUTTON_GEN2_CAR_KEYFOB_P60_V3" 12 "KEY_FORM_FACTOR_3_BUTTON_GEN2_CAR_KEYFOB_P60_V2" 11 "KEY_FORM_FACTOR_5_BUTTON_GEN2_CAR_KEYFOB_P60" 10 "KEY_FORM_FACTOR_3_BUTTON_GEN2_CAR_KEYFOB_P60" 9 "KEY_FORM_FACTOR_CLOUD_KEY" 8 "KEY_FORM_FACTOR_3_BUTTON_BLE_CAR_KEYFOB_P60" 7 "KEY_FORM_FACTOR_ANDROID_DEVICE" 6 "KEY_FORM_FACTOR_IOS_DEVICE" 5 "KEY_FORM_FACTOR_BLE_AND_NFC_DEVICE" 4 "KEY_FORM_FACTOR_NFC_DEVICE" 3 "KEY_FORM_FACTOR_BLE_DEVICE" 2 "KEY_FORM_FACTOR_3_BUTTON_BLE_CAR_KEYFOB" 1 "KEY_FORM_FACTOR_NFC_CARD" 0 "KEY_FORM_FACTOR_UNKNOWN" ;
VAL_ 857 VCSEC_Device14Role 10 "DEVICE_ROLE_PREDELIVERY_KEY" 9 "DEVICE_ROLE_RIDER_KEY" 8 "DEVICE_ROLE_GUEST_KEY" 7 "DEVICE_ROLE_SERVICE_TECH_KEY" 6 "DEVICE_ROLE_CHARGING_MANAGER_KEY" 5 "DEVICE_ROLE_VEHICLE_MONITOR_KEY" 4 "DEVICE_ROLE_FM_KEY" 3 "DEVICE_ROLE_DRIVER_KEY" 2 "DEVICE_ROLE_OWNER_KEY" 1 "DEVICE_ROLE_SERVICE_KEY" 0 "DEVICE_ROLE_NONE" ;
VAL_ 857 VCSEC_Device15AuthResponseTime 127 "SNA" ;
VAL_ 857 VCSEC_Device15Formfactor 19 "KEY_FORM_FACTOR_HARMONY_OS_NEXT_DEVICE" 18 "KEY_FORM_FACTOR_NFC_CARD_WATCHDATA_PLASTIC_CARD" 17 "KEY_FORM_FACTOR_APPLE_WATCH" 16 "KEY_FORM_FACTOR_NFC_CARD_IDEMIA_PLASTIC_CARD" 15 "KEY_FORM_FACTOR_NFC_CARD_IDEMIA_METAL_CARD" 14 "KEY_FORM_FACTOR_NFC_CARD_P71" 13 "KEY_FORM_FACTOR_3_BUTTON_GEN2_CAR_KEYFOB_P60_V3" 12 "KEY_FORM_FACTOR_3_BUTTON_GEN2_CAR_KEYFOB_P60_V2" 11 "KEY_FORM_FACTOR_5_BUTTON_GEN2_CAR_KEYFOB_P60" 10 "KEY_FORM_FACTOR_3_BUTTON_GEN2_CAR_KEYFOB_P60" 9 "KEY_FORM_FACTOR_CLOUD_KEY" 8 "KEY_FORM_FACTOR_3_BUTTON_BLE_CAR_KEYFOB_P60" 7 "KEY_FORM_FACTOR_ANDROID_DEVICE" 6 "KEY_FORM_FACTOR_IOS_DEVICE" 5 "KEY_FORM_FACTOR_BLE_AND_NFC_DEVICE" 4 "KEY_FORM_FACTOR_NFC_DEVICE" 3 "KEY_FORM_FACTOR_BLE_DEVICE" 2 "KEY_FORM_FACTOR_3_BUTTON_BLE_CAR_KEYFOB" 1 "KEY_FORM_FACTOR_NFC_CARD" 0 "KEY_FORM_FACTOR_UNKNOWN" ;
VAL_ 857 VCSEC_Device15Role 10 "DEVICE_ROLE_PREDELIVERY_KEY" 9 "DEVICE_ROLE_RIDER_KEY" 8 "DEVICE_ROLE_GUEST_KEY" 7 "DEVICE_ROLE_SERVICE_TECH_KEY" 6 "DEVICE_ROLE_CHARGING_MANAGER_KEY" 5 "DEVICE_ROLE_VEHICLE_MONITOR_KEY" 4 "DEVICE_ROLE_FM_KEY" 3 "DEVICE_ROLE_DRIVER_KEY" 2 "DEVICE_ROLE_OWNER_KEY" 1 "DEVICE_ROLE_SERVICE_KEY" 0 "DEVICE_ROLE_NONE" ;
VAL_ 857 VCSEC_Device16AuthResponseTime 127 "SNA" ;
VAL_ 857 VCSEC_Device16Formfactor 19 "KEY_FORM_FACTOR_HARMONY_OS_NEXT_DEVICE" 18 "KEY_FORM_FACTOR_NFC_CARD_WATCHDATA_PLASTIC_CARD" 17 "KEY_FORM_FACTOR_APPLE_WATCH" 16 "KEY_FORM_FACTOR_NFC_CARD_IDEMIA_PLASTIC_CARD" 15 "KEY_FORM_FACTOR_NFC_CARD_IDEMIA_METAL_CARD" 14 "KEY_FORM_FACTOR_NFC_CARD_P71" 13 "KEY_FORM_FACTOR_3_BUTTON_GEN2_CAR_KEYFOB_P60_V3" 12 "KEY_FORM_FACTOR_3_BUTTON_GEN2_CAR_KEYFOB_P60_V2" 11 "KEY_FORM_FACTOR_5_BUTTON_GEN2_CAR_KEYFOB_P60" 10 "KEY_FORM_FACTOR_3_BUTTON_GEN2_CAR_KEYFOB_P60" 9 "KEY_FORM_FACTOR_CLOUD_KEY" 8 "KEY_FORM_FACTOR_3_BUTTON_BLE_CAR_KEYFOB_P60" 7 "KEY_FORM_FACTOR_ANDROID_DEVICE" 6 "KEY_FORM_FACTOR_IOS_DEVICE" 5 "KEY_FORM_FACTOR_BLE_AND_NFC_DEVICE" 4 "KEY_FORM_FACTOR_NFC_DEVICE" 3 "KEY_FORM_FACTOR_BLE_DEVICE" 2 "KEY_FORM_FACTOR_3_BUTTON_BLE_CAR_KEYFOB" 1 "KEY_FORM_FACTOR_NFC_CARD" 0 "KEY_FORM_FACTOR_UNKNOWN" ;
VAL_ 857 VCSEC_Device16Role 10 "DEVICE_ROLE_PREDELIVERY_KEY" 9 "DEVICE_ROLE_RIDER_KEY" 8 "DEVICE_ROLE_GUEST_KEY" 7 "DEVICE_ROLE_SERVICE_TECH_KEY" 6 "DEVICE_ROLE_CHARGING_MANAGER_KEY" 5 "DEVICE_ROLE_VEHICLE_MONITOR_KEY" 4 "DEVICE_ROLE_FM_KEY" 3 "DEVICE_ROLE_DRIVER_KEY" 2 "DEVICE_ROLE_OWNER_KEY" 1 "DEVICE_ROLE_SERVICE_KEY" 0 "DEVICE_ROLE_NONE" ;
VAL_ 857 VCSEC_Device17AuthResponseTime 127 "SNA" ;
VAL_ 857 VCSEC_Device17Formfactor 19 "KEY_FORM_FACTOR_HARMONY_OS_NEXT_DEVICE" 18 "KEY_FORM_FACTOR_NFC_CARD_WATCHDATA_PLASTIC_CARD" 17 "KEY_FORM_FACTOR_APPLE_WATCH" 16 "KEY_FORM_FACTOR_NFC_CARD_IDEMIA_PLASTIC_CARD" 15 "KEY_FORM_FACTOR_NFC_CARD_IDEMIA_METAL_CARD" 14 "KEY_FORM_FACTOR_NFC_CARD_P71" 13 "KEY_FORM_FACTOR_3_BUTTON_GEN2_CAR_KEYFOB_P60_V3" 12 "KEY_FORM_FACTOR_3_BUTTON_GEN2_CAR_KEYFOB_P60_V2" 11 "KEY_FORM_FACTOR_5_BUTTON_GEN2_CAR_KEYFOB_P60" 10 "KEY_FORM_FACTOR_3_BUTTON_GEN2_CAR_KEYFOB_P60" 9 "KEY_FORM_FACTOR_CLOUD_KEY" 8 "KEY_FORM_FACTOR_3_BUTTON_BLE_CAR_KEYFOB_P60" 7 "KEY_FORM_FACTOR_ANDROID_DEVICE" 6 "KEY_FORM_FACTOR_IOS_DEVICE" 5 "KEY_FORM_FACTOR_BLE_AND_NFC_DEVICE" 4 "KEY_FORM_FACTOR_NFC_DEVICE" 3 "KEY_FORM_FACTOR_BLE_DEVICE" 2 "KEY_FORM_FACTOR_3_BUTTON_BLE_CAR_KEYFOB" 1 "KEY_FORM_FACTOR_NFC_CARD" 0 "KEY_FORM_FACTOR_UNKNOWN" ;
VAL_ 857 VCSEC_Device17Role 10 "DEVICE_ROLE_PREDELIVERY_KEY" 9 "DEVICE_ROLE_RIDER_KEY" 8 "DEVICE_ROLE_GUEST_KEY" 7 "DEVICE_ROLE_SERVICE_TECH_KEY" 6 "DEVICE_ROLE_CHARGING_MANAGER_KEY" 5 "DEVICE_ROLE_VEHICLE_MONITOR_KEY" 4 "DEVICE_ROLE_FM_KEY" 3 "DEVICE_ROLE_DRIVER_KEY" 2 "DEVICE_ROLE_OWNER_KEY" 1 "DEVICE_ROLE_SERVICE_KEY" 0 "DEVICE_ROLE_NONE" ;
VAL_ 857 VCSEC_Device18AuthResponseTime 127 "SNA" ;
VAL_ 857 VCSEC_Device18Formfactor 19 "KEY_FORM_FACTOR_HARMONY_OS_NEXT_DEVICE" 18 "KEY_FORM_FACTOR_NFC_CARD_WATCHDATA_PLASTIC_CARD" 17 "KEY_FORM_FACTOR_APPLE_WATCH" 16 "KEY_FORM_FACTOR_NFC_CARD_IDEMIA_PLASTIC_CARD" 15 "KEY_FORM_FACTOR_NFC_CARD_IDEMIA_METAL_CARD" 14 "KEY_FORM_FACTOR_NFC_CARD_P71" 13 "KEY_FORM_FACTOR_3_BUTTON_GEN2_CAR_KEYFOB_P60_V3" 12 "KEY_FORM_FACTOR_3_BUTTON_GEN2_CAR_KEYFOB_P60_V2" 11 "KEY_FORM_FACTOR_5_BUTTON_GEN2_CAR_KEYFOB_P60" 10 "KEY_FORM_FACTOR_3_BUTTON_GEN2_CAR_KEYFOB_P60" 9 "KEY_FORM_FACTOR_CLOUD_KEY" 8 "KEY_FORM_FACTOR_3_BUTTON_BLE_CAR_KEYFOB_P60" 7 "KEY_FORM_FACTOR_ANDROID_DEVICE" 6 "KEY_FORM_FACTOR_IOS_DEVICE" 5 "KEY_FORM_FACTOR_BLE_AND_NFC_DEVICE" 4 "KEY_FORM_FACTOR_NFC_DEVICE" 3 "KEY_FORM_FACTOR_BLE_DEVICE" 2 "KEY_FORM_FACTOR_3_BUTTON_BLE_CAR_KEYFOB" 1 "KEY_FORM_FACTOR_NFC_CARD" 0 "KEY_FORM_FACTOR_UNKNOWN" ;
VAL_ 857 VCSEC_Device18Role 10 "DEVICE_ROLE_PREDELIVERY_KEY" 9 "DEVICE_ROLE_RIDER_KEY" 8 "DEVICE_ROLE_GUEST_KEY" 7 "DEVICE_ROLE_SERVICE_TECH_KEY" 6 "DEVICE_ROLE_CHARGING_MANAGER_KEY" 5 "DEVICE_ROLE_VEHICLE_MONITOR_KEY" 4 "DEVICE_ROLE_FM_KEY" 3 "DEVICE_ROLE_DRIVER_KEY" 2 "DEVICE_ROLE_OWNER_KEY" 1 "DEVICE_ROLE_SERVICE_KEY" 0 "DEVICE_ROLE_NONE" ;
VAL_ 857 VCSEC_Device19AuthResponseTime 127 "SNA" ;
VAL_ 857 VCSEC_Device19Formfactor 19 "KEY_FORM_FACTOR_HARMONY_OS_NEXT_DEVICE" 18 "KEY_FORM_FACTOR_NFC_CARD_WATCHDATA_PLASTIC_CARD" 17 "KEY_FORM_FACTOR_APPLE_WATCH" 16 "KEY_FORM_FACTOR_NFC_CARD_IDEMIA_PLASTIC_CARD" 15 "KEY_FORM_FACTOR_NFC_CARD_IDEMIA_METAL_CARD" 14 "KEY_FORM_FACTOR_NFC_CARD_P71" 13 "KEY_FORM_FACTOR_3_BUTTON_GEN2_CAR_KEYFOB_P60_V3" 12 "KEY_FORM_FACTOR_3_BUTTON_GEN2_CAR_KEYFOB_P60_V2" 11 "KEY_FORM_FACTOR_5_BUTTON_GEN2_CAR_KEYFOB_P60" 10 "KEY_FORM_FACTOR_3_BUTTON_GEN2_CAR_KEYFOB_P60" 9 "KEY_FORM_FACTOR_CLOUD_KEY" 8 "KEY_FORM_FACTOR_3_BUTTON_BLE_CAR_KEYFOB_P60" 7 "KEY_FORM_FACTOR_ANDROID_DEVICE" 6 "KEY_FORM_FACTOR_IOS_DEVICE" 5 "KEY_FORM_FACTOR_BLE_AND_NFC_DEVICE" 4 "KEY_FORM_FACTOR_NFC_DEVICE" 3 "KEY_FORM_FACTOR_BLE_DEVICE" 2 "KEY_FORM_FACTOR_3_BUTTON_BLE_CAR_KEYFOB" 1 "KEY_FORM_FACTOR_NFC_CARD" 0 "KEY_FORM_FACTOR_UNKNOWN" ;
VAL_ 857 VCSEC_Device19Role 10 "DEVICE_ROLE_PREDELIVERY_KEY" 9 "DEVICE_ROLE_RIDER_KEY" 8 "DEVICE_ROLE_GUEST_KEY" 7 "DEVICE_ROLE_SERVICE_TECH_KEY" 6 "DEVICE_ROLE_CHARGING_MANAGER_KEY" 5 "DEVICE_ROLE_VEHICLE_MONITOR_KEY" 4 "DEVICE_ROLE_FM_KEY" 3 "DEVICE_ROLE_DRIVER_KEY" 2 "DEVICE_ROLE_OWNER_KEY" 1 "DEVICE_ROLE_SERVICE_KEY" 0 "DEVICE_ROLE_NONE" ;
VAL_ 1066 VCSEC_TPMSSensorState0 5 "SENSOR_WAIT_FOR_NEXT_ADV" 4 "SENSOR_DISCONNECTING" 3 "SENSOR_CONNECTED" 2 "SENSOR_WAIT_FOR_CONN" 1 "SENSOR_WAIT_FOR_ADV" 0 "SENSOR_NOT_PAIRED" ;
VAL_ 1066 VCSEC_TPMSConnectionTypeCurrent0 3 "CONNECTIONTYPE_FAST_SLAVE_LATENCY" 2 "CONNECTIONTYPE_UNKNOWN" 1 "CONNECTIONTYPE_SLOW" 0 "CONNECTIONTYPE_FAST" ;
VAL_ 1066 VCSEC_TPMSConnectionTypeDesired0 3 "CONNECTIONTYPE_FAST_SLAVE_LATENCY" 2 "CONNECTIONTYPE_UNKNOWN" 1 "CONNECTIONTYPE_SLOW" 0 "CONNECTIONTYPE_FAST" ;
VAL_ 1066 VCSEC_TPMSSensorState1 5 "SENSOR_WAIT_FOR_NEXT_ADV" 4 "SENSOR_DISCONNECTING" 3 "SENSOR_CONNECTED" 2 "SENSOR_WAIT_FOR_CONN" 1 "SENSOR_WAIT_FOR_ADV" 0 "SENSOR_NOT_PAIRED" ;
VAL_ 1066 VCSEC_TPMSConnectionTypeCurrent1 3 "CONNECTIONTYPE_FAST_SLAVE_LATENCY" 2 "CONNECTIONTYPE_UNKNOWN" 1 "CONNECTIONTYPE_SLOW" 0 "CONNECTIONTYPE_FAST" ;
VAL_ 1066 VCSEC_TPMSConnectionTypeDesired1 3 "CONNECTIONTYPE_FAST_SLAVE_LATENCY" 2 "CONNECTIONTYPE_UNKNOWN" 1 "CONNECTIONTYPE_SLOW" 0 "CONNECTIONTYPE_FAST" ;
VAL_ 1066 VCSEC_TPMSSensorState2 5 "SENSOR_WAIT_FOR_NEXT_ADV" 4 "SENSOR_DISCONNECTING" 3 "SENSOR_CONNECTED" 2 "SENSOR_WAIT_FOR_CONN" 1 "SENSOR_WAIT_FOR_ADV" 0 "SENSOR_NOT_PAIRED" ;
VAL_ 1066 VCSEC_TPMSConnectionTypeCurrent2 3 "CONNECTIONTYPE_FAST_SLAVE_LATENCY" 2 "CONNECTIONTYPE_UNKNOWN" 1 "CONNECTIONTYPE_SLOW" 0 "CONNECTIONTYPE_FAST" ;
VAL_ 1066 VCSEC_TPMSConnectionTypeDesired2 3 "CONNECTIONTYPE_FAST_SLAVE_LATENCY" 2 "CONNECTIONTYPE_UNKNOWN" 1 "CONNECTIONTYPE_SLOW" 0 "CONNECTIONTYPE_FAST" ;
VAL_ 1066 VCSEC_TPMSSensorState3 5 "SENSOR_WAIT_FOR_NEXT_ADV" 4 "SENSOR_DISCONNECTING" 3 "SENSOR_CONNECTED" 2 "SENSOR_WAIT_FOR_CONN" 1 "SENSOR_WAIT_FOR_ADV" 0 "SENSOR_NOT_PAIRED" ;
VAL_ 1066 VCSEC_TPMSConnectionTypeCurrent3 3 "CONNECTIONTYPE_FAST_SLAVE_LATENCY" 2 "CONNECTIONTYPE_UNKNOWN" 1 "CONNECTIONTYPE_SLOW" 0 "CONNECTIONTYPE_FAST" ;
VAL_ 1066 VCSEC_TPMSConnectionTypeDesired3 3 "CONNECTIONTYPE_FAST_SLAVE_LATENCY" 2 "CONNECTIONTYPE_UNKNOWN" 1 "CONNECTIONTYPE_SLOW" 0 "CONNECTIONTYPE_FAST" ;
VAL_ 1066 VCSEC_TPMSSensorPresence0 2 "PRESENT" 1 "NOT_PRESENT" 0 "NOT_PAIRED" ;
VAL_ 1066 VCSEC_TPMSSensorPresence1 2 "PRESENT" 1 "NOT_PRESENT" 0 "NOT_PAIRED" ;
VAL_ 1066 VCSEC_TPMSSensorPresence2 2 "PRESENT" 1 "NOT_PRESENT" 0 "NOT_PAIRED" ;
VAL_ 1066 VCSEC_TPMSSensorPresence3 2 "PRESENT" 1 "NOT_PRESENT" 0 "NOT_PAIRED" ;
